VERSION "created by canmatrix"

NS_ :

BS_:

BU_: IPD

BO_ 351 ICBAD_RZCUCANFD_20ms_FrP05: 20 IPD
 SG_ ICBAD_20ms_Group05_CRC : 7|8@0+ (1,0) [0|255] "null" Vector__XXX
 SG_ ICBAD_20ms_Group05_RC : 11|4@0+ (1,0) [0|15] "null" Vector__XXX
 SG_ ICBAD_20ms_Group05_Reserved1 : 12|1@0+ (1,0) [0|1] "null" Vector__XXX
 SG_ APAVCUReqSts : 15|3@0+ (1,0) [0|7] "null" Vector__XXX
 SG_ ICBAD_20ms_Group05_Reserved2 : 23|8@0+ (1,0) [0|255] "null" Vector__XXX
 SG_ APAToqReqVal : 31|12@0+ (0.5,-848) [-848|1199.5] "Nm" Vector__XXX
 SG_ APACrpSpdReqVal_IPD : 33|10@0+ (0.1,0) [0|102.3] "km/h" Vector__XXX
 SG_ ICBAD_20ms_Group05_Reserved3 : 34|1@0+ (1,0) [0|1] "null" Vector__XXX
 SG_ APARevrDrgReq : 35|1@0+ (1,0) [0|1] "null" Vector__XXX
 SG_ ICBAD_20ms_Group05_Reserved4 : 55|8@0+ (1,0) [0|255] "null" Vector__XXX
 SG_ ICBAD_20ms_Group05_Reserved5 : 63|8@0+ (1,0) [0|255] "null" Vector__XXX
 SG_ APATotWhlToqReqVal : 71|16@0+ (1,-30000) [-30000|35535] "Nm" Vector__XXX
 SG_ ICBAD_20ms_Group05_Reserved6 : 87|8@0+ (1,0) [0|255] "null" Vector__XXX
 SG_ ICBAD_20ms_Group05_Reserved7 : 95|8@0+ (1,0) [0|255] "null" Vector__XXX
 SG_ ICBAD_20ms_Group05_Reserved8 : 103|8@0+ (1,0) [0|255] "null" Vector__XXX
 SG_ ICBAD_20ms_Group05_Reserved9 : 111|8@0+ (1,0) [0|255] "null" Vector__XXX
 SG_ ICBAD_20ms_Group05_Reserved10 : 119|8@0+ (1,0) [0|255] "null" Vector__XXX
 SG_ ICBAD_20ms_Group05_Reserved11 : 127|8@0+ (1,0) [0|255] "null" Vector__XXX
 SG_ ICBAD_20ms_Group05_Reserved12 : 135|8@0+ (1,0) [0|255] "null" Vector__XXX
 SG_ ICBAD_20ms_Group05_Reserved13 : 143|8@0+ (1,0) [0|255] "null" Vector__XXX
 SG_ ICBAD_20ms_Group05_Reserved14 : 151|8@0+ (1,0) [0|255] "null" Vector__XXX
 SG_ ICBAD_20ms_Group05_Reserved15 : 159|8@0+ (1,0) [0|255] "null" Vector__XXX

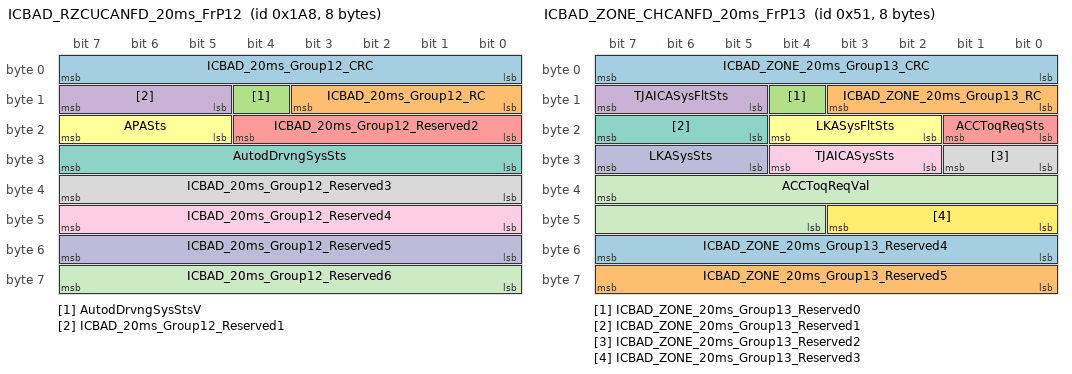
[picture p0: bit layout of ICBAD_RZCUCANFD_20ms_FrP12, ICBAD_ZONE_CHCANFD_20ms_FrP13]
BO_ 424 ICBAD_RZCUCANFD_20ms_FrP12: 8 IPD
 SG_ ICBAD_20ms_Group12_CRC : 7|8@0+ (1,0) [0|255] "null" Vector__XXX
 SG_ ICBAD_20ms_Group12_RC : 11|4@0+ (1,0) [0|15] "null" Vector__XXX
 SG_ AutodDrvngSysStsV : 12|1@0+ (1,0) [0|1] "null" Vector__XXX
 SG_ ICBAD_20ms_Group12_Reserved1 : 15|3@0+ (1,0) [0|7] "null" Vector__XXX
 SG_ ICBAD_20ms_Group12_Reserved2 : 20|5@0+ (1,0) [0|31] "null" Vector__XXX
 SG_ APASts : 23|3@0+ (1,0) [0|7] "null" Vector__XXX
 SG_ AutodDrvngSysSts : 31|8@0+ (1,0) [0|255] "null" Vector__XXX
 SG_ ICBAD_20ms_Group12_Reserved3 : 39|8@0+ (1,0) [0|255] "null" Vector__XXX
 SG_ ICBAD_20ms_Group12_Reserved4 : 47|8@0+ (1,0) [0|255] "null" Vector__XXX
 SG_ ICBAD_20ms_Group12_Reserved5 : 55|8@0+ (1,0) [0|255] "null" Vector__XXX
 SG_ ICBAD_20ms_Group12_Reserved6 : 63|8@0+ (1,0) [0|255] "null" Vector__XXX

BO_ 431 ICBAD_RZCUCANFD_20ms_FrP15_NoSec: 12 IPD
 SG_ ICBAD_20ms_Group15_CRC : 7|8@0+ (1,0) [0|255] "null" Vector__XXX
 SG_ ICBAD_20ms_Group15_RC : 11|4@0+ (1,0) [0|15] "null" Vector__XXX
 SG_ ACCDclReqSts : 13|2@0+ (1,0) [0|3] "null" Vector__XXX
 SG_ ICBAD_20ms_Group15_Reserved1 : 15|2@0+ (1,0) [0|3] "null" Vector__XXX
 SG_ ICBAD_20ms_Group15_Reserved2 : 23|8@0+ (1,0) [0|255] "null" Vector__XXX
 SG_ ACCOtptShaftTotToqReqVal : 31|12@0+ (2,-3392) [-3392|4798] "Nm" Vector__XXX
 SG_ ICBAD_20ms_Group15_Reserved3 : 33|2@0+ (1,0) [0|3] "null" Vector__XXX
 SG_ ACCOtptShaftTotToqReqSts : 35|2@0+ (1,0) [0|3] "null" Vector__XXX
 SG_ AutodDrvngSysStsPT : 47|8@0+ (1,0) [0|255] "null" Vector__XXX
 SG_ ICBAD_20ms_Group15_Reserved4 : 55|8@0+ (1,0) [0|255] "null" Vector__XXX
 SG_ ICBAD_20ms_Group15_Reserved5 : 63|8@0+ (1,0) [0|255] "null" Vector__XXX
 SG_ ICBAD_20ms_Group15_Reserved6 : 71|8@0+ (1,0) [0|255] "null" Vector__XXX
 SG_ ICBAD_20ms_Group15_Reserved7 : 79|8@0+ (1,0) [0|255] "null" Vector__XXX
 SG_ ICBAD_20ms_Group15_Reserved8 : 87|8@0+ (1,0) [0|255] "null" Vector__XXX
 SG_ ICBAD_20ms_Group15_Reserved9 : 95|8@0+ (1,0) [0|255] "null" Vector__XXX

BO_ 81 ICBAD_ZONE_CHCANFD_20ms_FrP13: 8 IPD
 SG_ ICBAD_ZONE_20ms_Group13_CRC : 7|8@0+ (1,0) [0|255] "null" Vector__XXX
 SG_ ICBAD_ZONE_20ms_Group13_RC : 11|4@0+ (1,0) [0|15] "null" Vector__XXX
 SG_ ICBAD_ZONE_20ms_Group13_Reserved0 : 12|1@0+ (1,0) [0|1] "null" Vector__XXX
 SG_ TJAICASysFltSts : 15|3@0+ (1,0) [0|7] "null" Vector__XXX
 SG_ ACCToqReqSts : 17|2@0+ (1,0) [0|3] "null" Vector__XXX
 SG_ LKASysFltSts : 20|3@0+ (1,0) [0|7] "null" Vector__XXX
 SG_ ICBAD_ZONE_20ms_Group13_Reserved1 : 23|3@0+ (1,0) [0|7] "null" Vector__XXX
 SG_ ICBAD_ZONE_20ms_Group13_Reserved2 : 25|2@0+ (1,0) [0|3] "null" Vector__XXX
 SG_ TJAICASysSts : 28|3@0+ (1,0) [0|7] "null" Vector__XXX
 SG_ LKASysSts : 31|3@0+ (1,0) [0|7] "null" Vector__XXX
 SG_ ACCToqReqVal : 39|12@0+ (0.5,-848) [-848|1199.5] "null" Vector__XXX
 SG_ ICBAD_ZONE_20ms_Group13_Reserved3 : 43|4@0+ (1,0) [0|15] "null" Vector__XXX
 SG_ ICBAD_ZONE_20ms_Group13_Reserved4 : 55|8@0+ (1,0) [0|255] "null" Vector__XXX
 SG_ ICBAD_ZONE_20ms_Group13_Reserved5 : 63|8@0+ (1,0) [0|255] "null" Vector__XXX

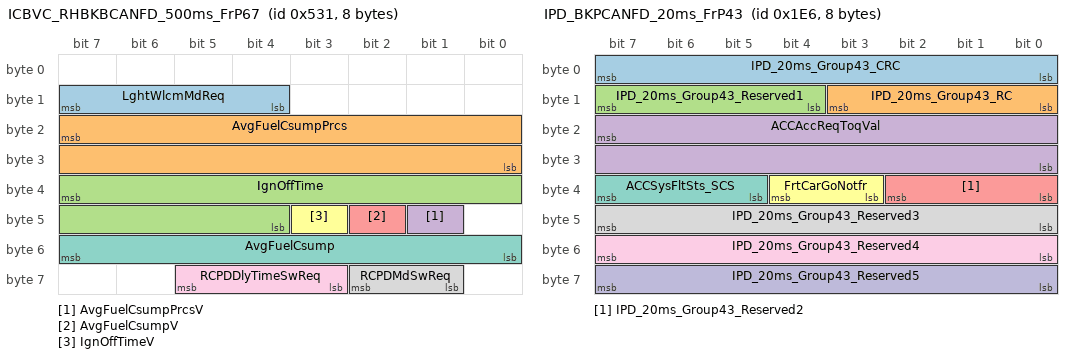
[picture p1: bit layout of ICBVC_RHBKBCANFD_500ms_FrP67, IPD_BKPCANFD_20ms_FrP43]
BO_ 1329 ICBVC_RHBKBCANFD_500ms_FrP67: 8 Vector__XXX
 SG_ LghtWlcmMdReq : 15|4@0+ (1,0) [0|15] "null" Vector__XXX
 SG_ AvgFuelCsumpPrcs : 23|16@0+ (0.01,0) [0.00|655.35] "0.01L/100km" Vector__XXX
 SG_ IgnOffTime : 39|12@0+ (0.5,0) [0|2047.5] "null" IPD
 SG_ AvgFuelCsumpPrcsV : 41|1@0+ (1,0) [0|1] "null" Vector__XXX
 SG_ AvgFuelCsumpV : 42|1@0+ (1,0) [0|1] "null" Vector__XXX
 SG_ IgnOffTimeV : 43|1@0+ (1,0) [0|1] "null" IPD
 SG_ AvgFuelCsump : 55|8@0+ (0.1,0) [0|25.5] "null" Vector__XXX
 SG_ RCPDMdSwReq : 58|2@0+ (1,0) [0|3] "null" Vector__XXX
 SG_ RCPDDlyTimeSwReq : 61|3@0+ (1,0) [0|7] "null" Vector__XXX

BO_ 1023 ICBVC_RZCUCANFD_100ms_FrP19: 8 Vector__XXX
 SG_ ICBVC_100ms_Group19_CRC : 7|8@0+ (1,0) [0|255] "null" IPD
 SG_ ICBVC_100ms_Group19_RC : 11|4@0+ (1,0) [0|15] "null" IPD
 SG_ RgnLvReqFICMV : 12|1@0+ (1,0) [0|1] "null" IPD
 SG_ RgnLvReqFICM : 15|3@0+ (1,0) [0|7] "null" IPD
 SG_ LVBatChrgReqRaw : 16|1@0+ (1,0) [0|1] "null" IPD
 SG_ LVBatChrgReqInhbt : 17|1@0+ (1,0) [0|1] "null" IPD
 SG_ LVBatEnrgSufct : 18|1@0+ (1,0) [0|1] "null" IPD
 SG_ LVBatEnrgLow : 19|1@0+ (1,0) [0|1] "null" IPD
 SG_ ICBVC_100ms_Group19_Reserved21 : 21|2@0+ (1,0) [0|3] "null" IPD
 SG_ EnrgSplReqV : 22|1@0+ (1,0) [0|1] "null" IPD
 SG_ EnrgSplReq : 23|1@0+ (1,0) [0|1] "null" IPD
 SG_ PMDCSta : 27|4@0+ (1,0) [0|15] "null" IPD
 SG_ EPMOprtMd : 31|4@0+ (1,0) [0|15] "null" IPD
 SG_ ICBVC_100ms_Group19_Reserved35 : 35|4@0+ (1,0) [0|15] "null" IPD
 SG_ VehEnrgRdyLvlV : 36|1@0+ (1,0) [0|1] "null" IPD
 SG_ VehEnrgRdyLvl : 39|3@0+ (1,0) [0|7] "null" IPD
 SG_ EPMCurEstdCapct : 47|8@0+ (0.5,0) [0|127.5] "Ah" IPD
 SG_ EPMMaxEstdCapct : 55|8@0+ (0.5,0) [0|127.5] "Ah" IPD
 SG_ LVBMDisChrgMOSCtrl : 56|1@0+ (1,0) [0|1] "null" IPD
 SG_ AuxBatUnAssembled : 57|1@0+ (1,0) [0|1] "null" IPD
 SG_ ICBVC_100ms_Group19_Reserved58 : 58|1@0+ (1,0) [0|1] "null" IPD
 SG_ EPTToqCustSetngReqV : 59|1@0+ (1,0) [0|1] "null" IPD
 SG_ EPTToqCustSetngReq : 61|2@0+ (1,0) [0|3] "null" IPD
 SG_ LVBatSelfWakeupFlg : 62|1@0+ (1,0) [0|1] "null" IPD
 SG_ EnrgSplReqRaw : 63|1@0+ (1,0) [0|1] "null" IPD

BO_ 486 IPD_BKPCANFD_20ms_FrP43: 8 IPD
 SG_ IPD_20ms_Group43_CRC : 7|8@0+ (1,0) [0|255] "null" Vector__XXX
 SG_ IPD_20ms_Group43_RC : 11|4@0+ (1,0) [0|15] "null" Vector__XXX
 SG_ IPD_20ms_Group43_Reserved1 : 15|4@0+ (1,0) [0|15] "null" Vector__XXX
 SG_ ACCAccReqToqVal : 23|16@0+ (1,0) [0|65535] "Nm" Vector__XXX
 SG_ IPD_20ms_Group43_Reserved2 : 34|3@0+ (1,0) [0|7] "null" Vector__XXX
 SG_ FrtCarGoNotfr : 36|2@0+ (1,0) [0|3] "null" Vector__XXX
 SG_ ACCSysFltSts_SCS : 39|3@0+ (1,0) [0|7] "null" Vector__XXX
 SG_ IPD_20ms_Group43_Reserved3 : 47|8@0+ (1,0) [0|255] "null" Vector__XXX
 SG_ IPD_20ms_Group43_Reserved4 : 55|8@0+ (1,0) [0|255] "null" Vector__XXX
 SG_ IPD_20ms_Group43_Reserved5 : 63|8@0+ (1,0) [0|255] "null" Vector__XXX

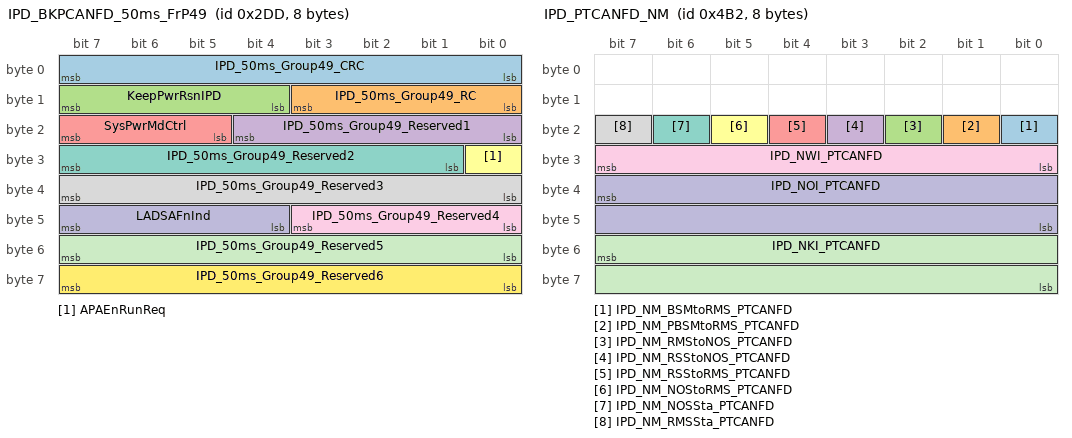
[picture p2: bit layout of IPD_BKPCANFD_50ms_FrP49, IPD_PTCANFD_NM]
BO_ 733 IPD_BKPCANFD_50ms_FrP49: 8 IPD
 SG_ IPD_50ms_Group49_CRC : 7|8@0+ (1,0) [0|255] "null" Vector__XXX
 SG_ IPD_50ms_Group49_RC : 11|4@0+ (1,0) [0|15] "null" Vector__XXX
 SG_ KeepPwrRsnIPD : 15|4@0+ (1,0) [0|15] "null" Vector__XXX
 SG_ IPD_50ms_Group49_Reserved1 : 20|5@0+ (1,0) [0|31] "null" Vector__XXX
 SG_ SysPwrMdCtrl : 23|3@0+ (1,0) [0|7] "null" Vector__XXX
 SG_ APAEnRunReq : 24|1@0+ (1,0) [0|1] "null" Vector__XXX
 SG_ IPD_50ms_Group49_Reserved2 : 31|7@0+ (1,0) [0|127] "null" Vector__XXX
 SG_ IPD_50ms_Group49_Reserved3 : 39|8@0+ (1,0) [0|255] "null" Vector__XXX
 SG_ IPD_50ms_Group49_Reserved4 : 43|4@0+ (1,0) [0|15] "null" Vector__XXX
 SG_ LADSAFnInd : 47|4@0+ (1,0) [0|15] "null" Vector__XXX
 SG_ IPD_50ms_Group49_Reserved5 : 55|8@0+ (1,0) [0|255] "null" Vector__XXX
 SG_ IPD_50ms_Group49_Reserved6 : 63|8@0+ (1,0) [0|255] "null" Vector__XXX

BO_ 982 IPD_PTCANFD_100ms_FrP03: 20 IPD
 SG_ ACCDetObjLongtRltvDist : 7|12@0+ (0.0625,0) [0.0000|255.9375] "null" Vector__XXX
 SG_ ACCDetObjSyncCtr : 11|4@0+ (1,0) [0|15] "null" Vector__XXX
 SG_ ACCDetObjLongtRltvSpd : 23|12@0+ (0.0625,-128) [-128.0000|127.9375] "null" Vector__XXX
 SG_ ACCDetObjRisk : 24|1@0+ (1,0) [0|1] "null" Vector__XXX
 SG_ ACCDetObjTyp : 27|3@0+ (1,0) [0|7] "null" Vector__XXX
 SG_ ACCDetObjLatRltvDist : 33|15@0+ (0.0078,-128) [-128.0000|127.5826] "null" Vector__XXX
 SG_ ACCDetObjExistPrblty : 39|6@0+ (0.015625,0) [0.000000|0.984375] "null" Vector__XXX
 SG_ ACCDetObjId : 50|6@0+ (1,0) [0|63] "null" Vector__XXX

BO_ 478 IPD_PTCANFD_20ms_FrP64: 16 IPD
 SG_ IPD_20ms_Group64_CRC : 7|8@0+ (1,0) [0|255] "null" Vector__XXX
 SG_ IPD_20ms_Group64_RC : 11|4@0+ (1,0) [0|15] "null" Vector__XXX
 SG_ APASCSDrvrReqSts : 12|1@0+ (1,0) [0|1] "null" Vector__XXX
 SG_ APASCSBrkFn : 15|3@0+ (1,0) [0|7] "null" Vector__XXX
 SG_ APASCSParkngVelMax : 23|8@0+ (0.1,0) [0|25.5] "null" Vector__XXX
 SG_ APASCSParkngTrgtDist : 31|12@0+ (1,0) [0|4095] "null" Vector__XXX
 SG_ APAEnToqReqVal : 35|12@0+ (0.5,-848) [-848|1199.5] "null" Vector__XXX
 SG_ IPD_20ms_Group64_Reserved1 : 48|1@0+ (1,0) [0|1] "null" Vector__XXX
 SG_ APAEnToqReqSts : 49|1@0+ (1,0) [0|1] "null" Vector__XXX
 SG_ APASCSParkngPrflReq : 50|1@0+ (1,0) [0|1] "null" Vector__XXX
 SG_ APASCSReqSts : 53|3@0+ (1,0) [0|7] "null" Vector__XXX
 SG_ APASCSBrkFnMd : 55|2@0+ (1,0) [0|3] "null" Vector__XXX
 SG_ IPD_20ms_Group64_Reserved2 : 63|8@0+ (1,0) [0|255] "null" Vector__XXX
 SG_ IPD_20ms_Group64_Reserved3 : 71|8@0+ (1,0) [0|255] "null" Vector__XXX
 SG_ IPD_20ms_Group64_Reserved4 : 79|8@0+ (1,0) [0|255] "null" Vector__XXX
 SG_ IPD_20ms_Group64_Reserved5 : 87|8@0+ (1,0) [0|255] "null" Vector__XXX
 SG_ IPD_20ms_Group64_Reserved6 : 95|8@0+ (1,0) [0|255] "null" Vector__XXX
 SG_ IPD_20ms_Group64_Reserved7 : 103|8@0+ (1,0) [0|255] "null" Vector__XXX
 SG_ IPD_20ms_Group64_Reserved8 : 111|8@0+ (1,0) [0|255] "null" Vector__XXX
 SG_ IPD_20ms_Group64_Reserved9 : 119|8@0+ (1,0) [0|255] "null" Vector__XXX
 SG_ IPD_20ms_Group64_Reserved10 : 127|8@0+ (1,0) [0|255] "null" Vector__XXX

BO_ 176 IPD_PTCANFD_20ms_FrP67: 16 IPD
 SG_ IPD_20ms_Group67_CRC : 7|8@0+ (1,0) [0|255] "null" Vector__XXX
 SG_ IPD_20ms_Group67_RC : 11|4@0+ (1,0) [0|15] "null" Vector__XXX
 SG_ IPD_20ms_Group67_Reserved15 : 15|4@0+ (1,0) [0|15] "null" Vector__XXX
 SG_ IPD_20ms_Group67_Reserved23 : 23|8@0+ (1,0) [0|255] "null" Vector__XXX
 SG_ IPD_20ms_Group67_Reserved31 : 31|8@0+ (1,0) [0|255] "null" Vector__XXX
 SG_ IPD_20ms_Group67_Reserved39 : 39|8@0+ (1,0) [0|255] "null" Vector__XXX
 SG_ IPD_20ms_Group67_Reserved47 : 47|8@0+ (1,0) [0|255] "null" Vector__XXX
 SG_ IPD_20ms_Group67_Reserved55 : 55|8@0+ (1,0) [0|255] "null" Vector__XXX
 SG_ IPD_20ms_Group67_Reserved63 : 63|8@0+ (1,0) [0|255] "null" Vector__XXX
 SG_ IPD_20ms_Group67_Reserved71 : 71|8@0+ (1,0) [0|255] "null" Vector__XXX
 SG_ ADS_SpdAstSysTrgtSpd : 79|15@0+ (0.015625,0) [0.000000|511.984375] "null" Vector__XXX
 SG_ ADS_SpdAstSysTrgtSpdV : 80|1@0+ (1,0) [0|1] "null" Vector__XXX
 SG_ IPD_20ms_Group67_Reserved95 : 95|8@0+ (1,0) [0|255] "null" Vector__XXX
 SG_ IPD_20ms_Group67_Reserved103 : 103|8@0+ (1,0) [0|255] "null" Vector__XXX
 SG_ IPD_20ms_Group67_Reserved111 : 111|8@0+ (1,0) [0|255] "null" Vector__XXX
 SG_ IPD_20ms_Group67_Reserved119 : 119|8@0+ (1,0) [0|255] "null" Vector__XXX
 SG_ IPD_20ms_Group67_Reserved127 : 127|8@0+ (1,0) [0|255] "null" Vector__XXX

BO_ 1202 IPD_PTCANFD_NM: 8 IPD
 SG_ IPD_NM_BSMtoRMS_PTCANFD : 16|1@0+ (1,0) [0|1] "null" Vector__XXX
 SG_ IPD_NM_PBSMtoRMS_PTCANFD : 17|1@0+ (1,0) [0|1] "null" Vector__XXX
 SG_ IPD_NM_RMStoNOS_PTCANFD : 18|1@0+ (1,0) [0|1] "null" Vector__XXX
 SG_ IPD_NM_RSStoNOS_PTCANFD : 19|1@0+ (1,0) [0|1] "null" Vector__XXX
 SG_ IPD_NM_RSStoRMS_PTCANFD : 20|1@0+ (1,0) [0|1] "null" Vector__XXX
 SG_ IPD_NM_NOStoRMS_PTCANFD : 21|1@0+ (1,0) [0|1] "null" Vector__XXX
 SG_ IPD_NM_NOSSta_PTCANFD : 22|1@0+ (1,0) [0|1] "null" Vector__XXX
 SG_ IPD_NM_RMSSta_PTCANFD : 23|1@0+ (1,0) [0|1] "null" Vector__XXX
 SG_ IPD_NWI_PTCANFD : 31|8@0+ (1,0) [0|255] "null" Vector__XXX
 SG_ IPD_NOI_PTCANFD : 39|16@0+ (1,0) [0|65535] "null" Vector__XXX
 SG_ IPD_NKI_PTCANFD : 55|16@0+ (1,0) [0|65535] "null" Vector__XXX

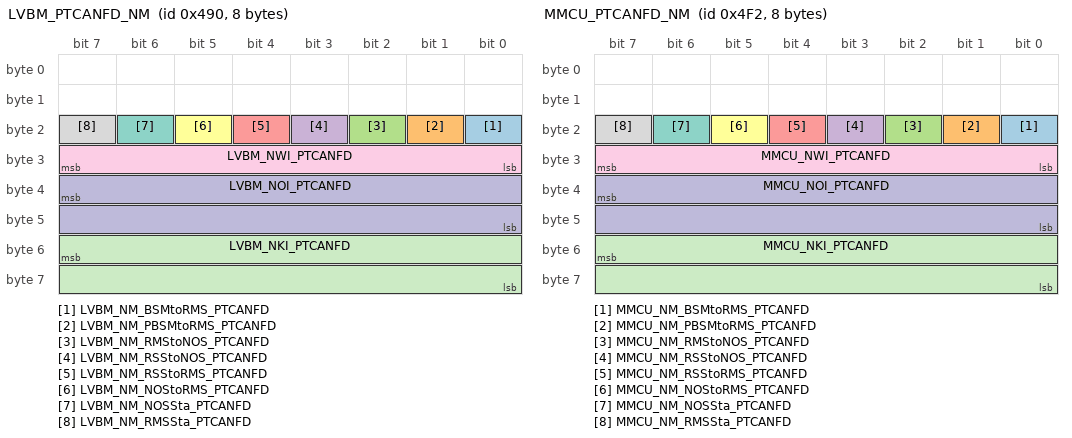
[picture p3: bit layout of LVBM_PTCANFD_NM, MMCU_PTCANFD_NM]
BO_ 1168 LVBM_PTCANFD_NM: 8 Vector__XXX
 SG_ LVBM_NM_BSMtoRMS_PTCANFD : 16|1@0+ (1,0) [0|1] "null" Vector__XXX
 SG_ LVBM_NM_PBSMtoRMS_PTCANFD : 17|1@0+ (1,0) [0|1] "null" Vector__XXX
 SG_ LVBM_NM_RMStoNOS_PTCANFD : 18|1@0+ (1,0) [0|1] "null" Vector__XXX
 SG_ LVBM_NM_RSStoNOS_PTCANFD : 19|1@0+ (1,0) [0|1] "null" Vector__XXX
 SG_ LVBM_NM_RSStoRMS_PTCANFD : 20|1@0+ (1,0) [0|1] "null" Vector__XXX
 SG_ LVBM_NM_NOStoRMS_PTCANFD : 21|1@0+ (1,0) [0|1] "null" Vector__XXX
 SG_ LVBM_NM_NOSSta_PTCANFD : 22|1@0+ (1,0) [0|1] "null" Vector__XXX
 SG_ LVBM_NM_RMSSta_PTCANFD : 23|1@0+ (1,0) [0|1] "null" Vector__XXX
 SG_ LVBM_NWI_PTCANFD : 31|8@0+ (1,0) [0|255] "null" Vector__XXX
 SG_ LVBM_NOI_PTCANFD : 39|16@0+ (1,0) [0|65535] "null" Vector__XXX
 SG_ LVBM_NKI_PTCANFD : 55|16@0+ (1,0) [0|65535] "null" Vector__XXX

BO_ 1266 MMCU_PTCANFD_NM: 8 Vector__XXX
 SG_ MMCU_NM_BSMtoRMS_PTCANFD : 16|1@0+ (1,0) [0|1] "null" Vector__XXX
 SG_ MMCU_NM_PBSMtoRMS_PTCANFD : 17|1@0+ (1,0) [0|1] "null" Vector__XXX
 SG_ MMCU_NM_RMStoNOS_PTCANFD : 18|1@0+ (1,0) [0|1] "null" Vector__XXX
 SG_ MMCU_NM_RSStoNOS_PTCANFD : 19|1@0+ (1,0) [0|1] "null" Vector__XXX
 SG_ MMCU_NM_RSStoRMS_PTCANFD : 20|1@0+ (1,0) [0|1] "null" Vector__XXX
 SG_ MMCU_NM_NOStoRMS_PTCANFD : 21|1@0+ (1,0) [0|1] "null" Vector__XXX
 SG_ MMCU_NM_NOSSta_PTCANFD : 22|1@0+ (1,0) [0|1] "null" Vector__XXX
 SG_ MMCU_NM_RMSSta_PTCANFD : 23|1@0+ (1,0) [0|1] "null" Vector__XXX
 SG_ MMCU_NWI_PTCANFD : 31|8@0+ (1,0) [0|255] "null" Vector__XXX
 SG_ MMCU_NOI_PTCANFD : 39|16@0+ (1,0) [0|65535] "null" Vector__XXX
 SG_ MMCU_NKI_PTCANFD : 55|16@0+ (1,0) [0|65535] "null" Vector__XXX

BO_ 153 PEU_PTCANFD_10ms_FrP25: 20 Vector__XXX
 SG_ PEU_10ms_Group25_CRC : 7|8@0+ (1,0) [0|255] "null" IPD
 SG_ PEU_10ms_Group25_RC : 11|4@0+ (1,0) [0|15] "null" IPD
 SG_ PEUMotBSpdSts : 13|2@0+ (1,0) [0|3] "null" IPD
 SG_ PEUMotASpdSts : 15|2@0+ (1,0) [0|3] "null" IPD
 SG_ PEUMotADampTrqCmdd : 23|16@0+ (0.03125,-1023.96875) [-1023.96875|1024.00000] "null" IPD
 SG_ PEUMotASpd : 39|16@0+ (1,-32768) [-32768|32767] "rpm" IPD
 SG_ PEUMotBDampTrqCmdd : 55|16@0+ (0.03125,-1023.96875) [-1023.96875|1024.00000] "null" IPD
 SG_ PEUMotBSpd : 71|16@0+ (1,-32768) [-32768|32767] "null" IPD
 SG_ PEUMotAToqAch : 87|12@0+ (0.5,-1023.5) [-1023.5|1024] "null" IPD
 SG_ PEUMotBToqAch : 90|11@0+ (0.5,-511.5) [-511.5|512] "null" IPD
 SG_ PEUMotASpdV : 91|1@0+ (1,0) [0|1] "null" IPD
 SG_ PEU_10ms_Group25_Reserved1 : 106|3@0+ (1,0) [0|7] "null" IPD
 SG_ ReAxleMaxAvlblWhlRgtnTqV : 107|1@0+ (1,0) [0|1] "null" IPD
 SG_ ReAxleMaxAvlblWhlDrvTqV : 108|1@0+ (1,0) [0|1] "null" IPD
 SG_ PEUMotBToqAchV : 109|1@0+ (1,0) [0|1] "null" IPD
 SG_ PEUMotBSpdV : 110|1@0+ (1,0) [0|1] "null" IPD
 SG_ PEUMotAToqAchV : 111|1@0+ (1,0) [0|1] "null" IPD
 SG_ ReAxleMaxAvlblWhlDrvTq : 119|16@0+ (1,-32767) [-32767|32768] "Nm" IPD
 SG_ ReAxleMaxAvlblWhlRgtnTq : 135|16@0+ (1,-32767) [-32767|32768] "Nm" IPD
 SG_ PEU_10ms_Group25_Reserved147 : 147|4@0+ (1,0) [0|15] "null" IPD
 SG_ PEUMotBMdAch : 149|2@0+ (1,0) [0|3] "null" IPD
 SG_ PEUMotAMdAch : 151|2@0+ (1,0) [0|3] "null" IPD
 SG_ PEU_10ms_Group25_Reserved3 : 159|8@0+ (1,0) [0|255] "null" IPD

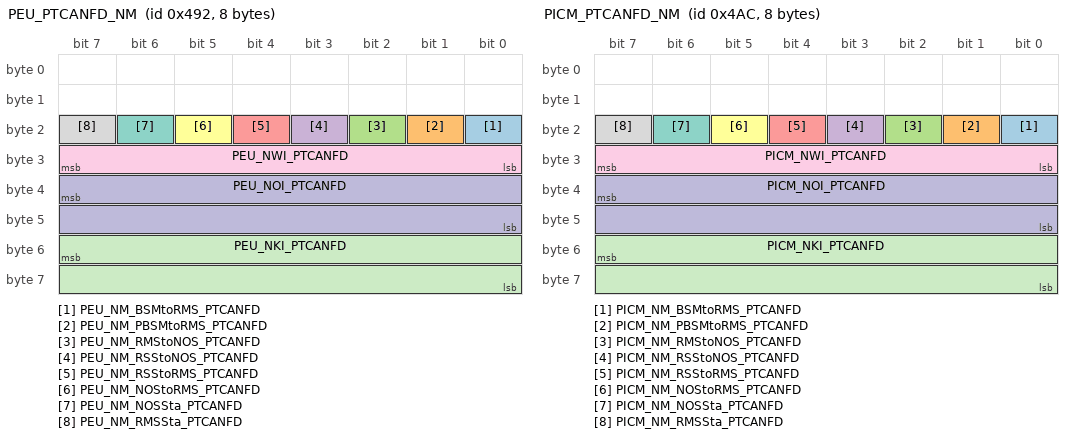
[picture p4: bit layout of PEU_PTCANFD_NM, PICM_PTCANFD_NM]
BO_ 1170 PEU_PTCANFD_NM: 8 Vector__XXX
 SG_ PEU_NM_BSMtoRMS_PTCANFD : 16|1@0+ (1,0) [0|1] "null" Vector__XXX
 SG_ PEU_NM_PBSMtoRMS_PTCANFD : 17|1@0+ (1,0) [0|1] "null" Vector__XXX
 SG_ PEU_NM_RMStoNOS_PTCANFD : 18|1@0+ (1,0) [0|1] "null" Vector__XXX
 SG_ PEU_NM_RSStoNOS_PTCANFD : 19|1@0+ (1,0) [0|1] "null" Vector__XXX
 SG_ PEU_NM_RSStoRMS_PTCANFD : 20|1@0+ (1,0) [0|1] "null" Vector__XXX
 SG_ PEU_NM_NOStoRMS_PTCANFD : 21|1@0+ (1,0) [0|1] "null" Vector__XXX
 SG_ PEU_NM_NOSSta_PTCANFD : 22|1@0+ (1,0) [0|1] "null" Vector__XXX
 SG_ PEU_NM_RMSSta_PTCANFD : 23|1@0+ (1,0) [0|1] "null" Vector__XXX
 SG_ PEU_NWI_PTCANFD : 31|8@0+ (1,0) [0|255] "null" Vector__XXX
 SG_ PEU_NOI_PTCANFD : 39|16@0+ (1,0) [0|65535] "null" Vector__XXX
 SG_ PEU_NKI_PTCANFD : 55|16@0+ (1,0) [0|65535] "null" Vector__XXX

BO_ 714 PICM_PTCANFD_100ms_FrP06: 20 Vector__XXX
 SG_ AGSModestatus2 : 13|2@0+ (1,0) [0|3] "null" Vector__XXX
 SG_ AGSModestatus1 : 15|2@0+ (1,0) [0|3] "null" Vector__XXX
 SG_ AGS1FltRsn : 23|12@0+ (1,0) [0|4095] "null" Vector__XXX
 SG_ AGS2FltRsn : 27|12@0+ (1,0) [0|4095] "null" Vector__XXX
 SG_ AGSActualPosition1 : 47|8@0+ (0.392157,0) [0.000000|100.000035] "null" Vector__XXX
 SG_ AGSActualPosition2 : 55|8@0+ (0.392157,0) [0.000000|100.000035] "null" Vector__XXX
 SG_ EPTElecWtrPumpActuSpd : 63|8@0+ (0.4,0) [0|102] "null" IPD
 SG_ ESSElecWtrPumpActuSpd : 71|8@0+ (0.4,0) [0|102] "null" Vector__XXX
 SG_ EDUClntTem : 79|8@0+ (1,-40) [-40|215] "null" IPD
 SG_ AGSTorqueResponse2 : 81|2@0+ (1,0) [0|3] "null" Vector__XXX
 SG_ AGSTorqueResponse1 : 83|2@0+ (1,0) [0|3] "null" Vector__XXX
 SG_ AGSSelflearnStatus2 : 85|2@0+ (1,0) [0|3] "null" Vector__XXX
 SG_ AGSSelflearnStatus1 : 87|2@0+ (1,0) [0|3] "null" Vector__XXX
 SG_ OBMLifeTimeParmFromEsMaxLmt : 88|1@0+ (1,0) [0|1] "null" Vector__XXX
 SG_ EndSocTrgtHCUV : 89|1@0+ (1,0) [0|1] "null" Vector__XXX
 SG_ AISocMngtActv : 90|1@0+ (1,0) [0|1] "null" Vector__XXX
 SG_ TrgtSOCUpdtReq : 91|1@0+ (1,0) [0|1] "null" Vector__XXX
 SG_ WCACThrWayVlvActuPosV : 92|1@0+ (1,0) [0|1] "null" Vector__XXX
 SG_ EDUClntTemV : 93|1@0+ (1,0) [0|1] "null" IPD
 SG_ AGSMoveStatus2 : 94|1@0+ (1,0) [0|1] "null" Vector__XXX
 SG_ AGSMoveStatus1 : 95|1@0+ (1,0) [0|1] "null" Vector__XXX
 SG_ WCACThrWayVlvActuPos : 103|8@0+ (0.4,0) [0|102] "Percent" Vector__XXX
 SG_ EndSocTrgtHCU : 111|10@0+ (0.1,0) [0|102.3] "null" Vector__XXX

BO_ 1196 PICM_PTCANFD_NM: 8 Vector__XXX
 SG_ PICM_NM_BSMtoRMS_PTCANFD : 16|1@0+ (1,0) [0|1] "null" Vector__XXX
 SG_ PICM_NM_PBSMtoRMS_PTCANFD : 17|1@0+ (1,0) [0|1] "null" Vector__XXX
 SG_ PICM_NM_RMStoNOS_PTCANFD : 18|1@0+ (1,0) [0|1] "null" Vector__XXX
 SG_ PICM_NM_RSStoNOS_PTCANFD : 19|1@0+ (1,0) [0|1] "null" Vector__XXX
 SG_ PICM_NM_RSStoRMS_PTCANFD : 20|1@0+ (1,0) [0|1] "null" Vector__XXX
 SG_ PICM_NM_NOStoRMS_PTCANFD : 21|1@0+ (1,0) [0|1] "null" Vector__XXX
 SG_ PICM_NM_NOSSta_PTCANFD : 22|1@0+ (1,0) [0|1] "null" Vector__XXX
 SG_ PICM_NM_RMSSta_PTCANFD : 23|1@0+ (1,0) [0|1] "null" Vector__XXX
 SG_ PICM_NWI_PTCANFD : 31|8@0+ (1,0) [0|255] "null" Vector__XXX
 SG_ PICM_NOI_PTCANFD : 39|16@0+ (1,0) [0|65535] "null" Vector__XXX
 SG_ PICM_NKI_PTCANFD : 55|16@0+ (1,0) [0|65535] "null" Vector__XXX

BO_ 140 PICU_PTCANFD_10ms_FrP03: 20 Vector__XXX
 SG_ PICU_10ms_Group03_CRC : 7|8@0+ (1,0) [0|255] "null" IPD
 SG_ PICU_10ms_Group03_RC : 11|4@0+ (1,0) [0|15] "null" IPD
 SG_ FrtAxleActuWhlToqV : 12|1@0+ (1,0) [0|1] "null" IPD
 SG_ PICU_10ms_Group03_Reserved1 : 13|1@0+ (1,0) [0|1] "null" IPD
 SG_ DrvrReqRrAxleWhlToqV : 14|1@0+ (1,0) [0|1] "null" IPD
 SG_ DrvrReqFrtAxleWhlToqV : 15|1@0+ (1,0) [0|1] "null" IPD
 SG_ DrvrReqFrtAxleWhlToq : 23|16@0+ (1,-30000) [-30000|35535] "null" IPD
 SG_ DrvrReqRrAxleWhlToq : 39|16@0+ (1,-30000) [-30000|35535] "null" IPD
 SG_ FrtAxleActuWhlToq : 55|16@0+ (1,-30000) [-30000|35535] "null" IPD
 SG_ RrAxleActuWhlToq : 71|16@0+ (1,-30000) [-30000|35535] "null" IPD
 SG_ TotActuWhlToq : 87|16@0+ (1,-30000) [-30000|35535] "null" IPD
 SG_ PICU_10ms_Group03_Reserved2 : 99|4@0+ (1,0) [0|15] "null" IPD
 SG_ TotActuWhlToqV : 100|1@0+ (1,0) [0|1] "null" IPD
 SG_ RrAxleActuWhlToqV : 101|1@0+ (1,0) [0|1] "null" IPD
 SG_ PtHVCntarReq : 103|2@0+ (1,0) [0|3] "null" IPD
 SG_ PICU_10ms_Group03_Reserved3 : 111|8@0+ (1,0) [0|255] "null" IPD
 SG_ PICU_10ms_Group03_Reserved4 : 119|8@0+ (1,0) [0|255] "null" IPD
 SG_ PICU_10ms_Group03_Reserved5 : 127|8@0+ (1,0) [0|255] "null" IPD
 SG_ PICU_10ms_Group03_Reserved6 : 135|8@0+ (1,0) [0|255] "null" IPD
 SG_ PICU_10ms_Group03_Reserved7 : 143|8@0+ (1,0) [0|255] "null" IPD
 SG_ PICU_10ms_Group03_Reserved8 : 151|8@0+ (1,0) [0|255] "null" IPD
 SG_ PICU_10ms_Group03_Reserved9 : 159|8@0+ (1,0) [0|255] "null" IPD

BO_ 359 PICU_PTCANFD_20ms_FrP11: 16 Vector__XXX
 SG_ PICU_20ms_Group11_CRC : 7|8@0+ (1,0) [0|255] "null" IPD
 SG_ PICU_20ms_Group11_RC : 11|4@0+ (1,0) [0|15] "null" IPD
 SG_ PICU_20ms_Group11_Reserved1 : 12|1@0+ (1,0) [0|1] "null" IPD
 SG_ HybAPAAvlbl : 13|1@0+ (1,0) [0|1] "null" IPD
 SG_ MinAvlblTotWhlToqV : 14|1@0+ (1,0) [0|1] "null" IPD
 SG_ MaxAvlblTotWhlToqV : 15|1@0+ (1,0) [0|1] "null" IPD
 SG_ MaxAvlblTotWhlToq : 23|16@0+ (1,-30000) [-30000|35535] "Nm" IPD
 SG_ MinAvlblTotWhlToq : 39|16@0+ (1,-30000) [-30000|35535] "Nm" IPD
 SG_ PICU_20ms_Group11_Reserved2 : 55|8@0+ (1,0) [0|255] "null" IPD
 SG_ CstRgtnBrkLgtReq : 56|1@0+ (1,0) [0|1] "null" IPD
 SG_ CstRgtnBrkLgtReqV : 57|1@0+ (1,0) [0|1] "null" IPD
 SG_ PICU_20ms_Group11_Reserved3 : 63|6@0+ (1,0) [0|63] "null" IPD
 SG_ PICU_20ms_Group11_Reserved4 : 71|8@0+ (1,0) [0|255] "null" IPD
 SG_ PICU_20ms_Group11_Reserved6 : 73|2@0+ (1,0) [0|3] "null" IPD
 SG_ RdundtHybCmddEnToqRespTyp : 75|2@0+ (1,0) [0|3] "null" IPD
 SG_ PICU_20ms_Group11_Reserved5 : 79|4@0+ (1,0) [0|15] "null" IPD
 SG_ PICU_20ms_Group11_Reserved7 : 87|8@0+ (1,0) [0|255] "null" IPD
 SG_ RdundtHybCmddEnToqImmd : 95|12@0+ (0.5,-848) [-848|1199.5] "null" IPD
 SG_ RdundtHybCmddEnToqPrdtd : 99|12@0+ (0.5,-848) [-848|1199.5] "null" IPD
 SG_ PICU_20ms_Group11_Reserved8 : 119|8@0+ (1,0) [0|255] "null" IPD
 SG_ PICU_20ms_Group11_Reserved9 : 127|8@0+ (1,0) [0|255] "null" IPD

BO_ 236 PICU_PTEXTDCAN_10ms_FrP23: 8 Vector__XXX
 SG_ PICU_10ms_Group23_CRC : 7|8@0+ (1,0) [0|255] "null" IPD
 SG_ PICU_10ms_Group23_RC : 11|4@0+ (1,0) [0|15] "null" IPD
 SG_ EnStCtrlA : 12|1@0+ (1,0) [0|1] "null" IPD
 SG_ EnFuelCutA : 13|1@0+ (1,0) [0|1] "null" IPD
 SG_ HybEnStSpOvrd : 15|2@0+ (1,0) [0|3] "null" IPD
 SG_ HybEnSpdReqF : 16|1@0+ (1,0) [0|1] "null" IPD
 SG_ EnDclFuelCutOffAld : 17|1@0+ (1,0) [0|1] "null" IPD
 SG_ PICU_10ms_Group23_Reserved18 : 18|1@0+ (1,0) [0|1] "null" IPD
 SG_ RVSEnRunning : 19|1@0+ (1,0) [0|1] "null" IPD
 SG_ EnHybVehStaOvrd : 23|4@0+ (1,0) [0|15] "null" IPD
 SG_ EnSynRdy : 24|1@0+ (1,0) [0|1] "null" IPD
 SG_ EnSysDsbld : 25|1@0+ (1,0) [0|1] "null" IPD
 SG_ EnComFlrRducdPwrCmdd : 26|1@0+ (1,0) [0|1] "null" IPD
 SG_ PtACCA : 27|1@0+ (1,0) [0|1] "null" IPD
 SG_ EnDclFuelCutOffReq : 28|1@0+ (1,0) [0|1] "null" IPD
 SG_ EnDclFuelCutOffSta : 29|1@0+ (1,0) [0|1] "null" IPD
 SG_ EnIdleCtrlA : 30|1@0+ (1,0) [0|1] "null" IPD
 SG_ EnIdleCtrlSts : 31|1@0+ (1,0) [0|1] "null" IPD
 SG_ CrkshftNonTrRegdCmddToq : 39|12@0+ (0.5,0) [0|2047.5] "null" IPD
 SG_ EnReqdStTyp : 43|4@0+ (1,0) [0|15] "null" IPD
 SG_ EnFuelRcvrySpd : 55|16@0+ (0.25,0) [0.00|16383.75] "null" IPD

BO_ 777 RZCU_PTCANFD_100ms_FrP10: 8 Vector__XXX
 SG_ RZCU_100ms_Group10_CRC : 7|8@0+ (1,0) [0|255] "null" IPD
 SG_ RZCU_100ms_Group10_RC : 11|4@0+ (1,0) [0|15] "null" IPD
 SG_ RZCU_100ms_Group10_Reserved1 : 13|2@0+ (1,0) [0|3] "null" IPD
 SG_ FlbStrgFnSts : 15|2@0+ (1,0) [0|3] "null" IPD
 SG_ OfbdChrgrNgtvSktTem : 23|8@0+ (1,-40) [-40|215] "degreeCelsius" IPD
 SG_ OnBdChrgrSktPstvSnsrTem : 31|8@0+ (1,-40) [-40|215] "degreeCelsius" IPD
 SG_ EleccLckCtrlResp : 34|3@0+ (1,0) [0|7] "null" IPD
 SG_ OnbdChrgrSktEleccLckEnable : 36|2@0+ (1,0) [0|3] "null" IPD
 SG_ OnBdChrgrSktPstvSnsrTemV : 37|1@0+ (1,0) [0|1] "null" IPD
 SG_ OfbdChrgrNgtvSktTemV : 38|1@0+ (1,0) [0|1] "null" IPD
 SG_ RZCU_100ms_Group10_Reserved2 : 39|1@0+ (1,0) [0|1] "null" IPD
 SG_ RZCU_100ms_Group10_Reserved3 : 45|7@0+ (1,0) [0|127] "null" IPD
 SG_ FlbStrgFnStsResp : 47|2@0+ (1,0) [0|3] "null" IPD
 SG_ RZCU_100ms_Group10_Reserved4 : 49|4@0+ (1,0) [0|15] "null" IPD
 SG_ IMU_Signal_status : 52|3@0+ (1,0) [0|7] "null" IPD
 SG_ VCUCtrlS2Req : 54|2@0+ (1,0) [0|3] "null" IPD
 SG_ RZCU_100ms_Group10_Reserved5 : 58|3@0+ (1,0) [0|7] "null" IPD
 SG_ OnBdChrgrSktElecLckStaV : 59|1@0+ (1,0) [0|1] "null" IPD
 SG_ OnBdChrgrSktElecLckSta : 61|2@0+ (1,0) [0|3] "null" IPD

BA_DEF_ BO_ "FrameTriggeringName" STRING;
BA_DEF_ BO_ "GenMsgCycleTime" INT 0 65535;
BA_DEF_ BO_ "GenMsgSendType" ENUM  "cyclicX","spontanX","cyclicIfActiveX","spontanWithDelay","cyclicAndSpontanX","cyclicAndSpontanWithDelay","spontanWithRepitition","cyclicIfActiveAndSpontanWD","cyclicIfActiveFast","cyclicWithRepeatOnDemand","none";
BA_DEF_ BO_ "GenMsgStartValue" STRING;
BA_DEF_ BO_ "PduName" STRING;
BA_DEF_ BO_ "SystemMessageLongSymbol" STRING;
BA_DEF_ BO_ "VFrameFormat" ENUM  "StandardCAN","ExtendedCAN","reserved","reserved","reserved","reserved","reserved","reserved","reserved","reserved","reserved","reserved","reserved","reserved","StandardCAN_FD","ExtendedCAN_FD";
BA_DEF_ SG_ "CompuMethodName" STRING;
BA_DEF_ SG_ "GenSigStartValue" FLOAT 0 100000000000;
BA_DEF_ SG_ "ISignalName" STRING;
BA_DEF_ SG_ "LongName" STRING;
BA_DEF_ SG_ "SysSignalName" STRING;
BA_DEF_ SG_ "SystemSignalLongSymbol" STRING;
BA_ "FrameTriggeringName" BO_ 351 "ICBAD_RZCUCANFD_20ms_FrP05";
BA_ "GenMsgCycleTime" BO_ 351 20;
BA_ "GenMsgSendType" BO_ 351 0;
BA_ "GenMsgStartValue" BO_ 351 "0010ff000400ffff0000ffffffffffffffffffff";
BA_ "PduName" BO_ 351 "ICBAD_20ms_PDU05";
BA_ "VFrameFormat" BO_ 351 14;
BA_ "FrameTriggeringName" BO_ 424 "ICBAD_RZCUCANFD_20ms_FrP12";
BA_ "GenMsgCycleTime" BO_ 424 20;
BA_ "GenMsgSendType" BO_ 424 0;
BA_ "GenMsgStartValue" BO_ 424 "00e01f00ffffffff";
BA_ "PduName" BO_ 424 "ICBAD_20ms_PDU12";
BA_ "VFrameFormat" BO_ 424 14;
BA_ "FrameTriggeringName" BO_ 431 "ICBAD_RZCUCANFD_20ms_FrP15_NoSecOC";
BA_ "GenMsgCycleTime" BO_ 431 20;
BA_ "GenMsgSendType" BO_ 431 0;
BA_ "GenMsgStartValue" BO_ 431 "00c0ff6a0300ffffffffffff";
BA_ "PduName" BO_ 431 "ICBAD_20ms_PDU15";
BA_ "SystemMessageLongSymbol" BO_ 431 "ICBAD_RZCUCANFD_20ms_FrP15_NoSecOC";
BA_ "VFrameFormat" BO_ 431 14;
BA_ "FrameTriggeringName" BO_ 81 "ICBAD_ZONE_CHCANFD_20ms_FrP13";
BA_ "GenMsgCycleTime" BO_ 81 20;
BA_ "GenMsgSendType" BO_ 81 0;
BA_ "GenMsgStartValue" BO_ 81 "0010e0036a0fffff";
BA_ "PduName" BO_ 81 "ICBAD_ZONE_20ms_PDU13";
BA_ "VFrameFormat" BO_ 81 14;
BA_ "FrameTriggeringName" BO_ 1329 "ICBVC_RHBKBCANFD_500ms_FrP67";
BA_ "GenMsgCycleTime" BO_ 1329 500;
BA_ "GenMsgSendType" BO_ 1329 0;
BA_ "GenMsgStartValue" BO_ 1329 "00000000fff60000";
BA_ "PduName" BO_ 1329 "ICBVC_500ms_PDU67";
BA_ "VFrameFormat" BO_ 1329 14;
BA_ "FrameTriggeringName" BO_ 1023 "ICBVC_RZCUCANFD_100ms_FrP19";
BA_ "GenMsgCycleTime" BO_ 1023 100;
BA_ "GenMsgSendType" BO_ 1023 0;
BA_ "GenMsgStartValue" BO_ 1023 "003078002f00002c";
BA_ "PduName" BO_ 1023 "ICBVC_100ms_PDU19";
BA_ "VFrameFormat" BO_ 1023 14;
BA_ "FrameTriggeringName" BO_ 486 "IPD_BKPCANFD_20ms_FrP43";
BA_ "GenMsgCycleTime" BO_ 486 20;
BA_ "GenMsgSendType" BO_ 486 0;
BA_ "GenMsgStartValue" BO_ 486 "00f0000007ffffff";
BA_ "PduName" BO_ 486 "IPD_20ms_PDU43";
BA_ "VFrameFormat" BO_ 486 14;
BA_ "FrameTriggeringName" BO_ 733 "IPD_BKPCANFD_50ms_FrP49";
BA_ "GenMsgCycleTime" BO_ 733 50;
BA_ "GenMsgSendType" BO_ 733 0;
BA_ "GenMsgStartValue" BO_ 733 "00001ffeff0fffff";
BA_ "PduName" BO_ 733 "IPD_50ms_PDU49";
BA_ "VFrameFormat" BO_ 733 14;
BA_ "FrameTriggeringName" BO_ 982 "IPD_PTCANFD_100ms_FrP03";
BA_ "GenMsgCycleTime" BO_ 982 100;
BA_ "GenMsgSendType" BO_ 982 0;
BA_ "GenMsgStartValue" BO_ 982 "0000000000000000000000000000000000000000";
BA_ "PduName" BO_ 982 "IPD_100ms_PDU03";
BA_ "VFrameFormat" BO_ 982 14;
BA_ "FrameTriggeringName" BO_ 478 "IPD_PTCANFD_20ms_FrP64";
BA_ "GenMsgCycleTime" BO_ 478 20;
BA_ "GenMsgSendType" BO_ 478 0;
BA_ "GenMsgStartValue" BO_ 478 "00000000000001ffffffffffffffffff";
BA_ "PduName" BO_ 478 "IPD_20ms_PDU64";
BA_ "VFrameFormat" BO_ 478 14;
BA_ "FrameTriggeringName" BO_ 176 "IPD_PTCANFD_20ms_FrP67";
BA_ "GenMsgCycleTime" BO_ 176 20;
BA_ "GenMsgSendType" BO_ 176 0;
BA_ "GenMsgStartValue" BO_ 176 "00f0ffffffffffffff0000ffffffffff";
BA_ "PduName" BO_ 176 "IPD_20ms_PDU67";
BA_ "VFrameFormat" BO_ 176 14;
BA_ "FrameTriggeringName" BO_ 1202 "IPD_PTCANFD_NM";
BA_ "GenMsgSendType" BO_ 1202 1;
BA_ "GenMsgStartValue" BO_ 1202 "0000000000000000";
BA_ "PduName" BO_ 1202 "NmPDU_PTCANFD_IPD";
BA_ "VFrameFormat" BO_ 1202 14;
BA_ "FrameTriggeringName" BO_ 1168 "LVBM_PTCANFD_NM";
BA_ "GenMsgSendType" BO_ 1168 1;
BA_ "GenMsgStartValue" BO_ 1168 "0000000000000000";
BA_ "PduName" BO_ 1168 "NmPDU_PTCANFD_LVBM";
BA_ "VFrameFormat" BO_ 1168 14;
BA_ "FrameTriggeringName" BO_ 1266 "MMCU_PTCANFD_NM";
BA_ "GenMsgSendType" BO_ 1266 1;
BA_ "GenMsgStartValue" BO_ 1266 "0000000000000000";
BA_ "PduName" BO_ 1266 "NmPDU_PTCANFD_MMCU";
BA_ "VFrameFormat" BO_ 1266 14;
BA_ "FrameTriggeringName" BO_ 153 "PEU_PTCANFD_10ms_FrP25";
BA_ "GenMsgCycleTime" BO_ 153 10;
BA_ "GenMsgSendType" BO_ 153 0;
BA_ "GenMsgStartValue" BO_ 153 "00007fff7fff7fff7fff7ffbff1f7fff7fff0fff";
BA_ "PduName" BO_ 153 "PEU_10ms_PDU25";
BA_ "VFrameFormat" BO_ 153 14;
BA_ "FrameTriggeringName" BO_ 1170 "PEU_PTCANFD_NM";
BA_ "GenMsgSendType" BO_ 1170 1;
BA_ "GenMsgStartValue" BO_ 1170 "0000000000000000";
BA_ "PduName" BO_ 1170 "NmPDU_PTCANFD_PEU";
BA_ "VFrameFormat" BO_ 1170 14;
BA_ "FrameTriggeringName" BO_ 714 "PICM_PTCANFD_100ms_FrP06";
BA_ "GenMsgCycleTime" BO_ 714 100;
BA_ "GenMsgSendType" BO_ 714 0;
BA_ "GenMsgStartValue" BO_ 714 "00f00000000000ffff00ff320000000000000000";
BA_ "PduName" BO_ 714 "PICM_100ms_PDU06";
BA_ "VFrameFormat" BO_ 714 14;
BA_ "FrameTriggeringName" BO_ 1196 "PICM_PTCANFD_NM";
BA_ "GenMsgSendType" BO_ 1196 1;
BA_ "GenMsgStartValue" BO_ 1196 "0000000000000000";
BA_ "PduName" BO_ 1196 "NmPDU_PTCANFD_PICM";
BA_ "VFrameFormat" BO_ 1196 14;
BA_ "FrameTriggeringName" BO_ 140 "PICU_PTCANFD_10ms_FrP03";
BA_ "GenMsgCycleTime" BO_ 140 10;
BA_ "GenMsgSendType" BO_ 140 0;
BA_ "GenMsgStartValue" BO_ 140 "00f0753075307530753075303fffffffffffffff";
BA_ "PduName" BO_ 140 "PICU_10ms_PDU03";
BA_ "VFrameFormat" BO_ 140 14;
BA_ "FrameTriggeringName" BO_ 359 "PICU_PTCANFD_20ms_FrP11";
BA_ "GenMsgCycleTime" BO_ 359 20;
BA_ "GenMsgSendType" BO_ 359 0;
BA_ "GenMsgStartValue" BO_ 359 "00d075307530fffcfff3ff6a06a0ffff";
BA_ "PduName" BO_ 359 "PICU_20ms_PDU11";
BA_ "VFrameFormat" BO_ 359 14;
BA_ "FrameTriggeringName" BO_ 236 "PICU_PTEXTDCAN_10ms_FrP23";
BA_ "GenMsgCycleTime" BO_ 236 20;
BA_ "GenMsgSendType" BO_ 236 0;
BA_ "GenMsgStartValue" BO_ 236 "0000040000000000";
BA_ "PduName" BO_ 236 "PICU_10ms_PDU23";
BA_ "VFrameFormat" BO_ 236 14;
BA_ "FrameTriggeringName" BO_ 777 "RZCU_PTCANFD_100ms_FrP10";
BA_ "GenMsgCycleTime" BO_ 777 100;
BA_ "GenMsgSendType" BO_ 777 0;
BA_ "GenMsgStartValue" BO_ 777 "0030fe00e03f83cf";
BA_ "PduName" BO_ 777 "RZCU_100ms_PDU10";
BA_ "VFrameFormat" BO_ 777 14;
BA_ "CompuMethodName" SG_ 351 ICBAD_20ms_Group05_CRC "ICBAD_20ms_Group05_CRC";
BA_ "ISignalName" SG_ 351 ICBAD_20ms_Group05_CRC "IICBAD_20ms_Group05_CRC";
BA_ "LongName" SG_ 351 ICBAD_20ms_Group05_CRC "ICBAD_20ms_Group05_CRC";
BA_ "SysSignalName" SG_ 351 ICBAD_20ms_Group05_CRC "ICBAD_20ms_Group05_CRC";
BA_ "CompuMethodName" SG_ 351 ICBAD_20ms_Group05_RC "ICBAD_20ms_Group05_RC";
BA_ "ISignalName" SG_ 351 ICBAD_20ms_Group05_RC "IICBAD_20ms_Group05_RC";
BA_ "LongName" SG_ 351 ICBAD_20ms_Group05_RC "ICBAD_20ms_Group05_RC";
BA_ "SysSignalName" SG_ 351 ICBAD_20ms_Group05_RC "ICBAD_20ms_Group05_RC";
BA_ "CompuMethodName" SG_ 351 ICBAD_20ms_Group05_Reserved1 "ICBAD_20ms_Group05_Reserved1";
BA_ "GenSigStartValue" SG_ 351 ICBAD_20ms_Group05_Reserved1 1;
BA_ "ISignalName" SG_ 351 ICBAD_20ms_Group05_Reserved1 "IICBAD_20ms_Group05_Reserved1";
BA_ "SysSignalName" SG_ 351 ICBAD_20ms_Group05_Reserved1 "ICBAD_20ms_Group05_Reserved1";
BA_ "CompuMethodName" SG_ 351 APAVCUReqSts "APAVCUReqSts";
BA_ "ISignalName" SG_ 351 APAVCUReqSts "IAPAVCUReqSts";
BA_ "LongName" SG_ 351 APAVCUReqSts "Apa Vcu Request Status";
BA_ "SysSignalName" SG_ 351 APAVCUReqSts "APAVCUReqSts";
BA_ "CompuMethodName" SG_ 351 ICBAD_20ms_Group05_Reserved2 "ICBAD_20ms_Group05_Reserved2";
BA_ "GenSigStartValue" SG_ 351 ICBAD_20ms_Group05_Reserved2 255;
BA_ "ISignalName" SG_ 351 ICBAD_20ms_Group05_Reserved2 "IICBAD_20ms_Group05_Reserved2";
BA_ "SysSignalName" SG_ 351 ICBAD_20ms_Group05_Reserved2 "ICBAD_20ms_Group05_Reserved2";
BA_ "CompuMethodName" SG_ 351 APAToqReqVal "APAToqReqVal";
BA_ "ISignalName" SG_ 351 APAToqReqVal "IAPAToqReqVal";
BA_ "LongName" SG_ 351 APAToqReqVal "Advanced Park Assist Torque Request Value";
BA_ "SysSignalName" SG_ 351 APAToqReqVal "APAToqReqVal";
BA_ "CompuMethodName" SG_ 351 APACrpSpdReqVal_IPD "APACrpSpdReqVal_IPD";
BA_ "ISignalName" SG_ 351 APACrpSpdReqVal_IPD "IAPACrpSpdReqVal_IPD";
BA_ "LongName" SG_ 351 APACrpSpdReqVal_IPD "Advanced Park Assist Creep Speed Request Value";
BA_ "SysSignalName" SG_ 351 APACrpSpdReqVal_IPD "APACrpSpdReqVal_IPD";
BA_ "CompuMethodName" SG_ 351 ICBAD_20ms_Group05_Reserved3 "ICBAD_20ms_Group05_Reserved3";
BA_ "GenSigStartValue" SG_ 351 ICBAD_20ms_Group05_Reserved3 1;
BA_ "ISignalName" SG_ 351 ICBAD_20ms_Group05_Reserved3 "IICBAD_20ms_Group05_Reserved3";
BA_ "SysSignalName" SG_ 351 ICBAD_20ms_Group05_Reserved3 "ICBAD_20ms_Group05_Reserved3";
BA_ "CompuMethodName" SG_ 351 APARevrDrgReq "APARevrDrgReq";
BA_ "ISignalName" SG_ 351 APARevrDrgReq "IAPARevrDrgReq";
BA_ "LongName" SG_ 351 APARevrDrgReq "Advanced Park Assist Reverse Drag Request";
BA_ "SysSignalName" SG_ 351 APARevrDrgReq "APARevrDrgReq";
BA_ "CompuMethodName" SG_ 351 ICBAD_20ms_Group05_Reserved4 "ICBAD_20ms_Group05_Reserved4";
BA_ "GenSigStartValue" SG_ 351 ICBAD_20ms_Group05_Reserved4 255;
BA_ "ISignalName" SG_ 351 ICBAD_20ms_Group05_Reserved4 "IICBAD_20ms_Group05_Reserved4";
BA_ "SysSignalName" SG_ 351 ICBAD_20ms_Group05_Reserved4 "ICBAD_20ms_Group05_Reserved4";
BA_ "CompuMethodName" SG_ 351 ICBAD_20ms_Group05_Reserved5 "ICBAD_20ms_Group05_Reserved5";
BA_ "GenSigStartValue" SG_ 351 ICBAD_20ms_Group05_Reserved5 255;
BA_ "ISignalName" SG_ 351 ICBAD_20ms_Group05_Reserved5 "IICBAD_20ms_Group05_Reserved5";
BA_ "SysSignalName" SG_ 351 ICBAD_20ms_Group05_Reserved5 "ICBAD_20ms_Group05_Reserved5";
BA_ "CompuMethodName" SG_ 351 APATotWhlToqReqVal "APATotWhlToqReqVal";
BA_ "ISignalName" SG_ 351 APATotWhlToqReqVal "IAPATotWhlToqReqVal";
BA_ "LongName" SG_ 351 APATotWhlToqReqVal "Advanced_Park_Assist_Total_Wheel_Torque_Request_Value";
BA_ "SysSignalName" SG_ 351 APATotWhlToqReqVal "APATotWhlToqReqVal";
BA_ "CompuMethodName" SG_ 351 ICBAD_20ms_Group05_Reserved6 "ICBAD_20ms_Group05_Reserved6";
BA_ "GenSigStartValue" SG_ 351 ICBAD_20ms_Group05_Reserved6 255;
BA_ "ISignalName" SG_ 351 ICBAD_20ms_Group05_Reserved6 "IICBAD_20ms_Group05_Reserved6";
BA_ "SysSignalName" SG_ 351 ICBAD_20ms_Group05_Reserved6 "ICBAD_20ms_Group05_Reserved6";
BA_ "CompuMethodName" SG_ 351 ICBAD_20ms_Group05_Reserved7 "ICBAD_20ms_Group05_Reserved7";
BA_ "GenSigStartValue" SG_ 351 ICBAD_20ms_Group05_Reserved7 255;
BA_ "ISignalName" SG_ 351 ICBAD_20ms_Group05_Reserved7 "IICBAD_20ms_Group05_Reserved7";
BA_ "SysSignalName" SG_ 351 ICBAD_20ms_Group05_Reserved7 "ICBAD_20ms_Group05_Reserved7";
BA_ "CompuMethodName" SG_ 351 ICBAD_20ms_Group05_Reserved8 "ICBAD_20ms_Group05_Reserved8";
BA_ "GenSigStartValue" SG_ 351 ICBAD_20ms_Group05_Reserved8 255;
BA_ "ISignalName" SG_ 351 ICBAD_20ms_Group05_Reserved8 "IICBAD_20ms_Group05_Reserved8";
BA_ "SysSignalName" SG_ 351 ICBAD_20ms_Group05_Reserved8 "ICBAD_20ms_Group05_Reserved8";
BA_ "CompuMethodName" SG_ 351 ICBAD_20ms_Group05_Reserved9 "ICBAD_20ms_Group05_Reserved9";
BA_ "GenSigStartValue" SG_ 351 ICBAD_20ms_Group05_Reserved9 255;
BA_ "ISignalName" SG_ 351 ICBAD_20ms_Group05_Reserved9 "IICBAD_20ms_Group05_Reserved9";
BA_ "SysSignalName" SG_ 351 ICBAD_20ms_Group05_Reserved9 "ICBAD_20ms_Group05_Reserved9";
BA_ "CompuMethodName" SG_ 351 ICBAD_20ms_Group05_Reserved10 "ICBAD_20ms_Group05_Reserved10";
BA_ "GenSigStartValue" SG_ 351 ICBAD_20ms_Group05_Reserved10 255;
BA_ "ISignalName" SG_ 351 ICBAD_20ms_Group05_Reserved10 "IICBAD_20ms_Group05_Reserved10";
BA_ "SysSignalName" SG_ 351 ICBAD_20ms_Group05_Reserved10 "ICBAD_20ms_Group05_Reserved10";
BA_ "CompuMethodName" SG_ 351 ICBAD_20ms_Group05_Reserved11 "ICBAD_20ms_Group05_Reserved11";
BA_ "GenSigStartValue" SG_ 351 ICBAD_20ms_Group05_Reserved11 255;
BA_ "ISignalName" SG_ 351 ICBAD_20ms_Group05_Reserved11 "IICBAD_20ms_Group05_Reserved11";
BA_ "SysSignalName" SG_ 351 ICBAD_20ms_Group05_Reserved11 "ICBAD_20ms_Group05_Reserved11";
BA_ "CompuMethodName" SG_ 351 ICBAD_20ms_Group05_Reserved12 "ICBAD_20ms_Group05_Reserved12";
BA_ "GenSigStartValue" SG_ 351 ICBAD_20ms_Group05_Reserved12 255;
BA_ "ISignalName" SG_ 351 ICBAD_20ms_Group05_Reserved12 "IICBAD_20ms_Group05_Reserved12";
BA_ "SysSignalName" SG_ 351 ICBAD_20ms_Group05_Reserved12 "ICBAD_20ms_Group05_Reserved12";
BA_ "CompuMethodName" SG_ 351 ICBAD_20ms_Group05_Reserved13 "ICBAD_20ms_Group05_Reserved13";
BA_ "GenSigStartValue" SG_ 351 ICBAD_20ms_Group05_Reserved13 255;
BA_ "ISignalName" SG_ 351 ICBAD_20ms_Group05_Reserved13 "IICBAD_20ms_Group05_Reserved13";
BA_ "SysSignalName" SG_ 351 ICBAD_20ms_Group05_Reserved13 "ICBAD_20ms_Group05_Reserved13";
BA_ "CompuMethodName" SG_ 351 ICBAD_20ms_Group05_Reserved14 "ICBAD_20ms_Group05_Reserved14";
BA_ "GenSigStartValue" SG_ 351 ICBAD_20ms_Group05_Reserved14 255;
BA_ "ISignalName" SG_ 351 ICBAD_20ms_Group05_Reserved14 "IICBAD_20ms_Group05_Reserved14";
BA_ "SysSignalName" SG_ 351 ICBAD_20ms_Group05_Reserved14 "ICBAD_20ms_Group05_Reserved14";
BA_ "CompuMethodName" SG_ 351 ICBAD_20ms_Group05_Reserved15 "ICBAD_20ms_Group05_Reserved15";
BA_ "GenSigStartValue" SG_ 351 ICBAD_20ms_Group05_Reserved15 255;
BA_ "ISignalName" SG_ 351 ICBAD_20ms_Group05_Reserved15 "IICBAD_20ms_Group05_Reserved15";
BA_ "SysSignalName" SG_ 351 ICBAD_20ms_Group05_Reserved15 "ICBAD_20ms_Group05_Reserved15";
BA_ "CompuMethodName" SG_ 424 ICBAD_20ms_Group12_CRC "ICBAD_20ms_Group12_CRC";
BA_ "ISignalName" SG_ 424 ICBAD_20ms_Group12_CRC "IICBAD_20ms_Group12_CRC";
BA_ "LongName" SG_ 424 ICBAD_20ms_Group12_CRC "ICBAD_20ms_Group12_CRC";
BA_ "SysSignalName" SG_ 424 ICBAD_20ms_Group12_CRC "ICBAD_20ms_Group12_CRC";
BA_ "CompuMethodName" SG_ 424 ICBAD_20ms_Group12_RC "ICBAD_20ms_Group12_RC";
BA_ "ISignalName" SG_ 424 ICBAD_20ms_Group12_RC "IICBAD_20ms_Group12_RC";
BA_ "LongName" SG_ 424 ICBAD_20ms_Group12_RC "ICBAD_20ms_Group12_RC";
BA_ "SysSignalName" SG_ 424 ICBAD_20ms_Group12_RC "ICBAD_20ms_Group12_RC";
BA_ "CompuMethodName" SG_ 424 AutodDrvngSysStsV "AutodDrvngSysStsV";
BA_ "ISignalName" SG_ 424 AutodDrvngSysStsV "IAutodDrvngSysStsV";
BA_ "LongName" SG_ 424 AutodDrvngSysStsV "Automated Driving System Status Validity";
BA_ "SysSignalName" SG_ 424 AutodDrvngSysStsV "AutodDrvngSysStsV";
BA_ "CompuMethodName" SG_ 424 ICBAD_20ms_Group12_Reserved1 "ICBAD_20ms_Group12_Reserved1";
BA_ "GenSigStartValue" SG_ 424 ICBAD_20ms_Group12_Reserved1 7;
BA_ "ISignalName" SG_ 424 ICBAD_20ms_Group12_Reserved1 "IICBAD_20ms_Group12_Reserved1";
BA_ "SysSignalName" SG_ 424 ICBAD_20ms_Group12_Reserved1 "ICBAD_20ms_Group12_Reserved1";
BA_ "CompuMethodName" SG_ 424 ICBAD_20ms_Group12_Reserved2 "ICBAD_20ms_Group12_Reserved2";
BA_ "GenSigStartValue" SG_ 424 ICBAD_20ms_Group12_Reserved2 31;
BA_ "ISignalName" SG_ 424 ICBAD_20ms_Group12_Reserved2 "IICBAD_20ms_Group12_Reserved2";
BA_ "SysSignalName" SG_ 424 ICBAD_20ms_Group12_Reserved2 "ICBAD_20ms_Group12_Reserved2";
BA_ "CompuMethodName" SG_ 424 APASts "APASts";
BA_ "ISignalName" SG_ 424 APASts "IAPASts";
BA_ "LongName" SG_ 424 APASts "Advanced_Park_Assist_Status";
BA_ "SysSignalName" SG_ 424 APASts "APASts";
BA_ "CompuMethodName" SG_ 424 AutodDrvngSysSts "AutodDrvngSysSts";
BA_ "ISignalName" SG_ 424 AutodDrvngSysSts "IAutodDrvngSysSts";
BA_ "LongName" SG_ 424 AutodDrvngSysSts "Automated_Driving_System_Status";
BA_ "SysSignalName" SG_ 424 AutodDrvngSysSts "AutodDrvngSysSts";
BA_ "CompuMethodName" SG_ 424 ICBAD_20ms_Group12_Reserved3 "ICBAD_20ms_Group12_Reserved3";
BA_ "GenSigStartValue" SG_ 424 ICBAD_20ms_Group12_Reserved3 255;
BA_ "ISignalName" SG_ 424 ICBAD_20ms_Group12_Reserved3 "IICBAD_20ms_Group12_Reserved3";
BA_ "SysSignalName" SG_ 424 ICBAD_20ms_Group12_Reserved3 "ICBAD_20ms_Group12_Reserved3";
BA_ "CompuMethodName" SG_ 424 ICBAD_20ms_Group12_Reserved4 "ICBAD_20ms_Group12_Reserved4";
BA_ "GenSigStartValue" SG_ 424 ICBAD_20ms_Group12_Reserved4 255;
BA_ "ISignalName" SG_ 424 ICBAD_20ms_Group12_Reserved4 "IICBAD_20ms_Group12_Reserved4";
BA_ "SysSignalName" SG_ 424 ICBAD_20ms_Group12_Reserved4 "ICBAD_20ms_Group12_Reserved4";
BA_ "CompuMethodName" SG_ 424 ICBAD_20ms_Group12_Reserved5 "ICBAD_20ms_Group12_Reserved5";
BA_ "GenSigStartValue" SG_ 424 ICBAD_20ms_Group12_Reserved5 255;
BA_ "ISignalName" SG_ 424 ICBAD_20ms_Group12_Reserved5 "IICBAD_20ms_Group12_Reserved5";
BA_ "SysSignalName" SG_ 424 ICBAD_20ms_Group12_Reserved5 "ICBAD_20ms_Group12_Reserved5";
BA_ "CompuMethodName" SG_ 424 ICBAD_20ms_Group12_Reserved6 "ICBAD_20ms_Group12_Reserved6";
BA_ "GenSigStartValue" SG_ 424 ICBAD_20ms_Group12_Reserved6 255;
BA_ "ISignalName" SG_ 424 ICBAD_20ms_Group12_Reserved6 "IICBAD_20ms_Group12_Reserved6";
BA_ "SysSignalName" SG_ 424 ICBAD_20ms_Group12_Reserved6 "ICBAD_20ms_Group12_Reserved6";
BA_ "CompuMethodName" SG_ 431 ICBAD_20ms_Group15_CRC "ICBAD_20ms_Group15_CRC";
BA_ "ISignalName" SG_ 431 ICBAD_20ms_Group15_CRC "IICBAD_20ms_Group15_CRC";
BA_ "LongName" SG_ 431 ICBAD_20ms_Group15_CRC "ICBAD_20ms_Group15_CRC";
BA_ "SysSignalName" SG_ 431 ICBAD_20ms_Group15_CRC "ICBAD_20ms_Group15_CRC";
BA_ "CompuMethodName" SG_ 431 ICBAD_20ms_Group15_RC "ICBAD_20ms_Group15_RC";
BA_ "ISignalName" SG_ 431 ICBAD_20ms_Group15_RC "IICBAD_20ms_Group15_RC";
BA_ "LongName" SG_ 431 ICBAD_20ms_Group15_RC "ICBAD_20ms_Group15_RC";
BA_ "SysSignalName" SG_ 431 ICBAD_20ms_Group15_RC "ICBAD_20ms_Group15_RC";
BA_ "CompuMethodName" SG_ 431 ACCDclReqSts "ACCDclReqSts";
BA_ "ISignalName" SG_ 431 ACCDclReqSts "IACCDclReqSts";
BA_ "LongName" SG_ 431 ACCDclReqSts "Adaptive Cruise Control Deceleration Request Status";
BA_ "SysSignalName" SG_ 431 ACCDclReqSts "ACCDclReqSts";
BA_ "CompuMethodName" SG_ 431 ICBAD_20ms_Group15_Reserved1 "ICBAD_20ms_Group15_Reserved1";
BA_ "GenSigStartValue" SG_ 431 ICBAD_20ms_Group15_Reserved1 3;
BA_ "ISignalName" SG_ 431 ICBAD_20ms_Group15_Reserved1 "IICBAD_20ms_Group15_Reserved1";
BA_ "SysSignalName" SG_ 431 ICBAD_20ms_Group15_Reserved1 "ICBAD_20ms_Group15_Reserved1";
BA_ "CompuMethodName" SG_ 431 ICBAD_20ms_Group15_Reserved2 "ICBAD_20ms_Group15_Reserved2";
BA_ "GenSigStartValue" SG_ 431 ICBAD_20ms_Group15_Reserved2 255;
BA_ "ISignalName" SG_ 431 ICBAD_20ms_Group15_Reserved2 "IICBAD_20ms_Group15_Reserved2";
BA_ "SysSignalName" SG_ 431 ICBAD_20ms_Group15_Reserved2 "ICBAD_20ms_Group15_Reserved2";
BA_ "CompuMethodName" SG_ 431 ACCOtptShaftTotToqReqVal "ACCOtptShaftTotToqReqVal";
BA_ "GenSigStartValue" SG_ 431 ACCOtptShaftTotToqReqVal 1696;
BA_ "ISignalName" SG_ 431 ACCOtptShaftTotToqReqVal "IACCOtptShaftTotToqReqVal";
BA_ "LongName" SG_ 431 ACCOtptShaftTotToqReqVal "Adaptive Cruise Control Output Shaft Total Torque Request Value";
BA_ "SysSignalName" SG_ 431 ACCOtptShaftTotToqReqVal "ACCOtptShaftTotToqReqVal";
BA_ "CompuMethodName" SG_ 431 ICBAD_20ms_Group15_Reserved3 "ICBAD_20ms_Group15_Reserved3";
BA_ "GenSigStartValue" SG_ 431 ICBAD_20ms_Group15_Reserved3 3;
BA_ "ISignalName" SG_ 431 ICBAD_20ms_Group15_Reserved3 "IICBAD_20ms_Group15_Reserved3";
BA_ "SysSignalName" SG_ 431 ICBAD_20ms_Group15_Reserved3 "ICBAD_20ms_Group15_Reserved3";
BA_ "CompuMethodName" SG_ 431 ACCOtptShaftTotToqReqSts "ACCOtptShaftTotToqReqSts";
BA_ "ISignalName" SG_ 431 ACCOtptShaftTotToqReqSts "IACCOtptShaftTotToqReqSts";
BA_ "LongName" SG_ 431 ACCOtptShaftTotToqReqSts "Adaptive Cruise Control Output Shaft Total Torque Request Status";
BA_ "SysSignalName" SG_ 431 ACCOtptShaftTotToqReqSts "ACCOtptShaftTotToqReqSts";
BA_ "CompuMethodName" SG_ 431 AutodDrvngSysStsPT "AutodDrvngSysStsPT";
BA_ "ISignalName" SG_ 431 AutodDrvngSysStsPT "IAutodDrvngSysStsPT";
BA_ "LongName" SG_ 431 AutodDrvngSysStsPT "Automated Driving System Status PT";
BA_ "SysSignalName" SG_ 431 AutodDrvngSysStsPT "AutodDrvngSysStsPT";
BA_ "CompuMethodName" SG_ 431 ICBAD_20ms_Group15_Reserved4 "ICBAD_20ms_Group15_Reserved4";
BA_ "GenSigStartValue" SG_ 431 ICBAD_20ms_Group15_Reserved4 255;
BA_ "ISignalName" SG_ 431 ICBAD_20ms_Group15_Reserved4 "IICBAD_20ms_Group15_Reserved4";
BA_ "SysSignalName" SG_ 431 ICBAD_20ms_Group15_Reserved4 "ICBAD_20ms_Group15_Reserved4";
BA_ "CompuMethodName" SG_ 431 ICBAD_20ms_Group15_Reserved5 "ICBAD_20ms_Group15_Reserved5";
BA_ "GenSigStartValue" SG_ 431 ICBAD_20ms_Group15_Reserved5 255;
BA_ "ISignalName" SG_ 431 ICBAD_20ms_Group15_Reserved5 "IICBAD_20ms_Group15_Reserved5";
BA_ "SysSignalName" SG_ 431 ICBAD_20ms_Group15_Reserved5 "ICBAD_20ms_Group15_Reserved5";
BA_ "CompuMethodName" SG_ 431 ICBAD_20ms_Group15_Reserved6 "ICBAD_20ms_Group15_Reserved6";
BA_ "GenSigStartValue" SG_ 431 ICBAD_20ms_Group15_Reserved6 255;
BA_ "ISignalName" SG_ 431 ICBAD_20ms_Group15_Reserved6 "IICBAD_20ms_Group15_Reserved6";
BA_ "SysSignalName" SG_ 431 ICBAD_20ms_Group15_Reserved6 "ICBAD_20ms_Group15_Reserved6";
BA_ "CompuMethodName" SG_ 431 ICBAD_20ms_Group15_Reserved7 "ICBAD_20ms_Group15_Reserved7";
BA_ "GenSigStartValue" SG_ 431 ICBAD_20ms_Group15_Reserved7 255;
BA_ "ISignalName" SG_ 431 ICBAD_20ms_Group15_Reserved7 "IICBAD_20ms_Group15_Reserved7";
BA_ "SysSignalName" SG_ 431 ICBAD_20ms_Group15_Reserved7 "ICBAD_20ms_Group15_Reserved7";
BA_ "CompuMethodName" SG_ 431 ICBAD_20ms_Group15_Reserved8 "ICBAD_20ms_Group15_Reserved8";
BA_ "GenSigStartValue" SG_ 431 ICBAD_20ms_Group15_Reserved8 255;
BA_ "ISignalName" SG_ 431 ICBAD_20ms_Group15_Reserved8 "IICBAD_20ms_Group15_Reserved8";
BA_ "SysSignalName" SG_ 431 ICBAD_20ms_Group15_Reserved8 "ICBAD_20ms_Group15_Reserved8";
BA_ "CompuMethodName" SG_ 431 ICBAD_20ms_Group15_Reserved9 "ICBAD_20ms_Group15_Reserved9";
BA_ "GenSigStartValue" SG_ 431 ICBAD_20ms_Group15_Reserved9 255;
BA_ "ISignalName" SG_ 431 ICBAD_20ms_Group15_Reserved9 "IICBAD_20ms_Group15_Reserved9";
BA_ "SysSignalName" SG_ 431 ICBAD_20ms_Group15_Reserved9 "ICBAD_20ms_Group15_Reserved9";
BA_ "CompuMethodName" SG_ 81 ICBAD_ZONE_20ms_Group13_CRC "ICBAD_ZONE_20ms_Group13_CRC";
BA_ "ISignalName" SG_ 81 ICBAD_ZONE_20ms_Group13_CRC "IICBAD_ZONE_20ms_Group13_CRC";
BA_ "LongName" SG_ 81 ICBAD_ZONE_20ms_Group13_CRC "ICBAD_ZONE_20ms_Group13_CRC";
BA_ "SysSignalName" SG_ 81 ICBAD_ZONE_20ms_Group13_CRC "ICBAD_ZONE_20ms_Group13_CRC";
BA_ "CompuMethodName" SG_ 81 ICBAD_ZONE_20ms_Group13_RC "ICBAD_ZONE_20ms_Group13_RC";
BA_ "ISignalName" SG_ 81 ICBAD_ZONE_20ms_Group13_RC "IICBAD_ZONE_20ms_Group13_RC";
BA_ "LongName" SG_ 81 ICBAD_ZONE_20ms_Group13_RC "ICBAD_ZONE_20ms_Group13_RC";
BA_ "SysSignalName" SG_ 81 ICBAD_ZONE_20ms_Group13_RC "ICBAD_ZONE_20ms_Group13_RC";
BA_ "CompuMethodName" SG_ 81 ICBAD_ZONE_20ms_Group13_Reserved0 "ICBAD_ZONE_20ms_Group13_Reserved1";
BA_ "GenSigStartValue" SG_ 81 ICBAD_ZONE_20ms_Group13_Reserved0 1;
BA_ "ISignalName" SG_ 81 ICBAD_ZONE_20ms_Group13_Reserved0 "IICBAD_ZONE_20ms_Group13_Reserved1";
BA_ "SysSignalName" SG_ 81 ICBAD_ZONE_20ms_Group13_Reserved0 "ICBAD_ZONE_20ms_Group13_Reserved1";
BA_ "SystemSignalLongSymbol" SG_ 81 ICBAD_ZONE_20ms_Group13_Reserved0 "ICBAD_ZONE_20ms_Group13_Reserved1";
BA_ "CompuMethodName" SG_ 81 TJAICASysFltSts "TJAICASysFltSts";
BA_ "ISignalName" SG_ 81 TJAICASysFltSts "ITJAICASysFltSts";
BA_ "LongName" SG_ 81 TJAICASysFltSts "Traffic Jam Assist Integrated Cruise Assist Fault Status";
BA_ "SysSignalName" SG_ 81 TJAICASysFltSts "TJAICASysFltSts";
BA_ "CompuMethodName" SG_ 81 ACCToqReqSts "ACCToqReqSts";
BA_ "ISignalName" SG_ 81 ACCToqReqSts "IACCToqReqSts";
BA_ "SysSignalName" SG_ 81 ACCToqReqSts "ACCToqReqSts";
BA_ "CompuMethodName" SG_ 81 LKASysFltSts "LKASysFltSts";
BA_ "ISignalName" SG_ 81 LKASysFltSts "ILKASysFltSts";
BA_ "LongName" SG_ 81 LKASysFltSts "Lane Keeping Assist System Fault Status";
BA_ "SysSignalName" SG_ 81 LKASysFltSts "LKASysFltSts";
BA_ "CompuMethodName" SG_ 81 ICBAD_ZONE_20ms_Group13_Reserved1 "ICBAD_ZONE_20ms_Group13_Reserved2";
BA_ "GenSigStartValue" SG_ 81 ICBAD_ZONE_20ms_Group13_Reserved1 7;
BA_ "ISignalName" SG_ 81 ICBAD_ZONE_20ms_Group13_Reserved1 "IICBAD_ZONE_20ms_Group13_Reserved2";
BA_ "SysSignalName" SG_ 81 ICBAD_ZONE_20ms_Group13_Reserved1 "ICBAD_ZONE_20ms_Group13_Reserved2";
BA_ "SystemSignalLongSymbol" SG_ 81 ICBAD_ZONE_20ms_Group13_Reserved1 "ICBAD_ZONE_20ms_Group13_Reserved2";
BA_ "CompuMethodName" SG_ 81 ICBAD_ZONE_20ms_Group13_Reserved2 "ICBAD_ZONE_20ms_Group13_Reserved3";
BA_ "GenSigStartValue" SG_ 81 ICBAD_ZONE_20ms_Group13_Reserved2 3;
BA_ "ISignalName" SG_ 81 ICBAD_ZONE_20ms_Group13_Reserved2 "IICBAD_ZONE_20ms_Group13_Reserved3";
BA_ "SysSignalName" SG_ 81 ICBAD_ZONE_20ms_Group13_Reserved2 "ICBAD_ZONE_20ms_Group13_Reserved3";
BA_ "SystemSignalLongSymbol" SG_ 81 ICBAD_ZONE_20ms_Group13_Reserved2 "ICBAD_ZONE_20ms_Group13_Reserved3";
BA_ "CompuMethodName" SG_ 81 TJAICASysSts "TJAICASysSts";
BA_ "ISignalName" SG_ 81 TJAICASysSts "ITJAICASysSts";
BA_ "LongName" SG_ 81 TJAICASysSts "Traffic Jam Assist Integrated Cruise Assist System Status";
BA_ "SysSignalName" SG_ 81 TJAICASysSts "TJAICASysSts";
BA_ "CompuMethodName" SG_ 81 LKASysSts "LKASysSts";
BA_ "ISignalName" SG_ 81 LKASysSts "ILKASysSts";
BA_ "LongName" SG_ 81 LKASysSts "Lane Keeping Assist System Status";
BA_ "SysSignalName" SG_ 81 LKASysSts "LKASysSts";
BA_ "CompuMethodName" SG_ 81 ACCToqReqVal "ACCToqReqVal";
BA_ "GenSigStartValue" SG_ 81 ACCToqReqVal 1696;
BA_ "ISignalName" SG_ 81 ACCToqReqVal "IACCToqReqVal";
BA_ "SysSignalName" SG_ 81 ACCToqReqVal "ACCToqReqVal";
BA_ "CompuMethodName" SG_ 81 ICBAD_ZONE_20ms_Group13_Reserved3 "ICBAD_ZONE_20ms_Group13_Reserved4";
BA_ "GenSigStartValue" SG_ 81 ICBAD_ZONE_20ms_Group13_Reserved3 15;
BA_ "ISignalName" SG_ 81 ICBAD_ZONE_20ms_Group13_Reserved3 "IICBAD_ZONE_20ms_Group13_Reserved4";
BA_ "SysSignalName" SG_ 81 ICBAD_ZONE_20ms_Group13_Reserved3 "ICBAD_ZONE_20ms_Group13_Reserved4";
BA_ "SystemSignalLongSymbol" SG_ 81 ICBAD_ZONE_20ms_Group13_Reserved3 "ICBAD_ZONE_20ms_Group13_Reserved4";
BA_ "CompuMethodName" SG_ 81 ICBAD_ZONE_20ms_Group13_Reserved4 "ICBAD_ZONE_20ms_Group13_Reserved5";
BA_ "GenSigStartValue" SG_ 81 ICBAD_ZONE_20ms_Group13_Reserved4 255;
BA_ "ISignalName" SG_ 81 ICBAD_ZONE_20ms_Group13_Reserved4 "IICBAD_ZONE_20ms_Group13_Reserved5";
BA_ "SysSignalName" SG_ 81 ICBAD_ZONE_20ms_Group13_Reserved4 "ICBAD_ZONE_20ms_Group13_Reserved5";
BA_ "SystemSignalLongSymbol" SG_ 81 ICBAD_ZONE_20ms_Group13_Reserved4 "ICBAD_ZONE_20ms_Group13_Reserved5";
BA_ "CompuMethodName" SG_ 81 ICBAD_ZONE_20ms_Group13_Reserved5 "ICBAD_ZONE_20ms_Group13_Reserved6";
BA_ "GenSigStartValue" SG_ 81 ICBAD_ZONE_20ms_Group13_Reserved5 255;
BA_ "ISignalName" SG_ 81 ICBAD_ZONE_20ms_Group13_Reserved5 "IICBAD_ZONE_20ms_Group13_Reserved6";
BA_ "SysSignalName" SG_ 81 ICBAD_ZONE_20ms_Group13_Reserved5 "ICBAD_ZONE_20ms_Group13_Reserved6";
BA_ "SystemSignalLongSymbol" SG_ 81 ICBAD_ZONE_20ms_Group13_Reserved5 "ICBAD_ZONE_20ms_Group13_Reserved6";
BA_ "CompuMethodName" SG_ 1329 LghtWlcmMdReq "LghtWlcmMdReq";
BA_ "ISignalName" SG_ 1329 LghtWlcmMdReq "ILghtWlcmMdReq";
BA_ "LongName" SG_ 1329 LghtWlcmMdReq "Light Welcome Mode Request";
BA_ "SysSignalName" SG_ 1329 LghtWlcmMdReq "LghtWlcmMdReq";
BA_ "CompuMethodName" SG_ 1329 AvgFuelCsumpPrcs "AvgFuelCsumpPrcs";
BA_ "ISignalName" SG_ 1329 AvgFuelCsumpPrcs "IAvgFuelCsumpPrcs";
BA_ "LongName" SG_ 1329 AvgFuelCsumpPrcs "Average Fuel Consumption Precision";
BA_ "SysSignalName" SG_ 1329 AvgFuelCsumpPrcs "AvgFuelCsumpPrcs";
BA_ "CompuMethodName" SG_ 1329 IgnOffTime "IgnOffTime";
BA_ "GenSigStartValue" SG_ 1329 IgnOffTime 4095;
BA_ "ISignalName" SG_ 1329 IgnOffTime "IIgnOffTime";
BA_ "LongName" SG_ 1329 IgnOffTime "Ignition Off Time";
BA_ "SysSignalName" SG_ 1329 IgnOffTime "IgnOffTime";
BA_ "CompuMethodName" SG_ 1329 AvgFuelCsumpPrcsV "AvgFuelCsumpPrcsV";
BA_ "GenSigStartValue" SG_ 1329 AvgFuelCsumpPrcsV 1;
BA_ "ISignalName" SG_ 1329 AvgFuelCsumpPrcsV "IAvgFuelCsumpPrcsV";
BA_ "LongName" SG_ 1329 AvgFuelCsumpPrcsV "Average Fuel Consumption Precision Validity";
BA_ "SysSignalName" SG_ 1329 AvgFuelCsumpPrcsV "AvgFuelCsumpPrcsV";
BA_ "CompuMethodName" SG_ 1329 AvgFuelCsumpV "AvgFuelCsumpV";
BA_ "GenSigStartValue" SG_ 1329 AvgFuelCsumpV 1;
BA_ "ISignalName" SG_ 1329 AvgFuelCsumpV "IAvgFuelCsumpV";
BA_ "LongName" SG_ 1329 AvgFuelCsumpV "Average Fuel Consumption Validity";
BA_ "SysSignalName" SG_ 1329 AvgFuelCsumpV "AvgFuelCsumpV";
BA_ "CompuMethodName" SG_ 1329 IgnOffTimeV "IgnOffTimeV";
BA_ "ISignalName" SG_ 1329 IgnOffTimeV "IIgnOffTimeV";
BA_ "LongName" SG_ 1329 IgnOffTimeV "Ignition Off Time Valid";
BA_ "SysSignalName" SG_ 1329 IgnOffTimeV "IgnOffTimeV";
BA_ "CompuMethodName" SG_ 1329 AvgFuelCsump "AvgFuelCsump";
BA_ "ISignalName" SG_ 1329 AvgFuelCsump "IAvgFuelCsump";
BA_ "LongName" SG_ 1329 AvgFuelCsump "Average Fuel Consumption";
BA_ "SysSignalName" SG_ 1329 AvgFuelCsump "AvgFuelCsump";
BA_ "CompuMethodName" SG_ 1329 RCPDMdSwReq "RCPDMdSwReq";
BA_ "ISignalName" SG_ 1329 RCPDMdSwReq "IRCPDMdSwReq";
BA_ "LongName" SG_ 1329 RCPDMdSwReq "Rear Child Presence Detection Mode Switch Request";
BA_ "SysSignalName" SG_ 1329 RCPDMdSwReq "RCPDMdSwReq";
BA_ "CompuMethodName" SG_ 1329 RCPDDlyTimeSwReq "RCPDDlyTimeSwReq";
BA_ "ISignalName" SG_ 1329 RCPDDlyTimeSwReq "IRCPDDlyTimeSwReq";
BA_ "LongName" SG_ 1329 RCPDDlyTimeSwReq "Rear Child Presence Detection Delay Time Switch Request";
BA_ "SysSignalName" SG_ 1329 RCPDDlyTimeSwReq "RCPDDlyTimeSwReq";
BA_ "CompuMethodName" SG_ 1023 ICBVC_100ms_Group19_CRC "ICBVC_100ms_Group19_CRC";
BA_ "ISignalName" SG_ 1023 ICBVC_100ms_Group19_CRC "IICBVC_100ms_Group19_CRC";
BA_ "SysSignalName" SG_ 1023 ICBVC_100ms_Group19_CRC "ICBVC_100ms_Group19_CRC";
BA_ "CompuMethodName" SG_ 1023 ICBVC_100ms_Group19_RC "ICBVC_100ms_Group19_RC";
BA_ "ISignalName" SG_ 1023 ICBVC_100ms_Group19_RC "IICBVC_100ms_Group19_RC";
BA_ "SysSignalName" SG_ 1023 ICBVC_100ms_Group19_RC "ICBVC_100ms_Group19_RC";
BA_ "CompuMethodName" SG_ 1023 RgnLvReqFICMV "RgnLvReqFICMV";
BA_ "GenSigStartValue" SG_ 1023 RgnLvReqFICMV 1;
BA_ "ISignalName" SG_ 1023 RgnLvReqFICMV "IRgnLvReqFICMV";
BA_ "LongName" SG_ 1023 RgnLvReqFICMV "Regen Level Request Front Infotainment Control Module Validity";
BA_ "SysSignalName" SG_ 1023 RgnLvReqFICMV "RgnLvReqFICMV";
BA_ "CompuMethodName" SG_ 1023 RgnLvReqFICM "RgnLvReqFICM";
BA_ "GenSigStartValue" SG_ 1023 RgnLvReqFICM 1;
BA_ "ISignalName" SG_ 1023 RgnLvReqFICM "IRgnLvReqFICM";
BA_ "LongName" SG_ 1023 RgnLvReqFICM "Regen Level Request Front Infotainment Control Module";
BA_ "SysSignalName" SG_ 1023 RgnLvReqFICM "RgnLvReqFICM";
BA_ "CompuMethodName" SG_ 1023 LVBatChrgReqRaw "LVBatChrgReqRaw";
BA_ "ISignalName" SG_ 1023 LVBatChrgReqRaw "ILVBatChrgReqRaw";
BA_ "LongName" SG_ 1023 LVBatChrgReqRaw "Low Voltage Battery Charge Request Raw";
BA_ "SysSignalName" SG_ 1023 LVBatChrgReqRaw "LVBatChrgReqRaw";
BA_ "CompuMethodName" SG_ 1023 LVBatChrgReqInhbt "LVBatChrgReqInhbt";
BA_ "ISignalName" SG_ 1023 LVBatChrgReqInhbt "ILVBatChrgReqInhbt";
BA_ "LongName" SG_ 1023 LVBatChrgReqInhbt "Low Voltage Battery Charge Request Inhibit flag";
BA_ "SysSignalName" SG_ 1023 LVBatChrgReqInhbt "LVBatChrgReqInhbt";
BA_ "CompuMethodName" SG_ 1023 LVBatEnrgSufct "LVBatEnrgSufct";
BA_ "ISignalName" SG_ 1023 LVBatEnrgSufct "ILVBatEnrgSufct";
BA_ "LongName" SG_ 1023 LVBatEnrgSufct "Low Voltage Battery Energy Sufficient";
BA_ "SysSignalName" SG_ 1023 LVBatEnrgSufct "LVBatEnrgSufct";
BA_ "CompuMethodName" SG_ 1023 LVBatEnrgLow "LVBatEnrgLow";
BA_ "GenSigStartValue" SG_ 1023 LVBatEnrgLow 1;
BA_ "ISignalName" SG_ 1023 LVBatEnrgLow "ILVBatEnrgLow";
BA_ "LongName" SG_ 1023 LVBatEnrgLow "Low Voltage Battery Energy Low";
BA_ "SysSignalName" SG_ 1023 LVBatEnrgLow "LVBatEnrgLow";
BA_ "CompuMethodName" SG_ 1023 ICBVC_100ms_Group19_Reserved21 "ICBVC_100ms_Group19_Reserved21";
BA_ "GenSigStartValue" SG_ 1023 ICBVC_100ms_Group19_Reserved21 3;
BA_ "ISignalName" SG_ 1023 ICBVC_100ms_Group19_Reserved21 "IICBVC_100ms_Group19_Reserved21";
BA_ "SysSignalName" SG_ 1023 ICBVC_100ms_Group19_Reserved21 "ICBVC_100ms_Group19_Reserved21";
BA_ "CompuMethodName" SG_ 1023 EnrgSplReqV "EnrgSplReqV";
BA_ "GenSigStartValue" SG_ 1023 EnrgSplReqV 1;
BA_ "ISignalName" SG_ 1023 EnrgSplReqV "IEnrgSplReqV";
BA_ "LongName" SG_ 1023 EnrgSplReqV "Energy_Supply_Request_Validity";
BA_ "SysSignalName" SG_ 1023 EnrgSplReqV "EnrgSplReqV";
BA_ "CompuMethodName" SG_ 1023 EnrgSplReq "EnrgSplReq";
BA_ "ISignalName" SG_ 1023 EnrgSplReq "IEnrgSplReq";
BA_ "LongName" SG_ 1023 EnrgSplReq "Energy_Supply_Request";
BA_ "SysSignalName" SG_ 1023 EnrgSplReq "EnrgSplReq";
BA_ "CompuMethodName" SG_ 1023 PMDCSta "PMDCSta";
BA_ "ISignalName" SG_ 1023 PMDCSta "IPMDCSta";
BA_ "LongName" SG_ 1023 PMDCSta "Power_Management_Direct_Current_Converter_State";
BA_ "SysSignalName" SG_ 1023 PMDCSta "PMDCSta";
BA_ "CompuMethodName" SG_ 1023 EPMOprtMd "EPMOprtMd";
BA_ "ISignalName" SG_ 1023 EPMOprtMd "IEPMOprtMd";
BA_ "LongName" SG_ 1023 EPMOprtMd "Electric_Power_Management_Operation_Mode";
BA_ "SysSignalName" SG_ 1023 EPMOprtMd "EPMOprtMd";
BA_ "CompuMethodName" SG_ 1023 ICBVC_100ms_Group19_Reserved35 "ICBVC_100ms_Group19_Reserved35";
BA_ "GenSigStartValue" SG_ 1023 ICBVC_100ms_Group19_Reserved35 15;
BA_ "ISignalName" SG_ 1023 ICBVC_100ms_Group19_Reserved35 "IICBVC_100ms_Group19_Reserved35";
BA_ "SysSignalName" SG_ 1023 ICBVC_100ms_Group19_Reserved35 "ICBVC_100ms_Group19_Reserved35";
BA_ "CompuMethodName" SG_ 1023 VehEnrgRdyLvlV "VehEnrgRdyLvlV";
BA_ "ISignalName" SG_ 1023 VehEnrgRdyLvlV "IVehEnrgRdyLvlV";
BA_ "LongName" SG_ 1023 VehEnrgRdyLvlV "Vehicle_Energy_Ready_Level_Validity";
BA_ "SysSignalName" SG_ 1023 VehEnrgRdyLvlV "VehEnrgRdyLvlV";
BA_ "CompuMethodName" SG_ 1023 VehEnrgRdyLvl "VehEnrgRdyLvl";
BA_ "GenSigStartValue" SG_ 1023 VehEnrgRdyLvl 1;
BA_ "ISignalName" SG_ 1023 VehEnrgRdyLvl "IVehEnrgRdyLvl";
BA_ "LongName" SG_ 1023 VehEnrgRdyLvl "Vehicle_Energy_Ready_Level";
BA_ "SysSignalName" SG_ 1023 VehEnrgRdyLvl "VehEnrgRdyLvl";
BA_ "CompuMethodName" SG_ 1023 EPMCurEstdCapct "EPMCurEstdCapct";
BA_ "ISignalName" SG_ 1023 EPMCurEstdCapct "IEPMCurEstdCapct";
BA_ "LongName" SG_ 1023 EPMCurEstdCapct "Electric_Power_Management_Current
Estimated Capacity";
BA_ "SysSignalName" SG_ 1023 EPMCurEstdCapct "EPMCurEstdCapct";
BA_ "CompuMethodName" SG_ 1023 EPMMaxEstdCapct "EPMMaxEstdCapct";
BA_ "ISignalName" SG_ 1023 EPMMaxEstdCapct "IEPMMaxEstdCapct";
BA_ "LongName" SG_ 1023 EPMMaxEstdCapct "Electric_Power_Management_Maximum
Estimated Capacity";
BA_ "SysSignalName" SG_ 1023 EPMMaxEstdCapct "EPMMaxEstdCapct";
BA_ "CompuMethodName" SG_ 1023 LVBMDisChrgMOSCtrl "LVBMDisChrgMOSCtrl";
BA_ "ISignalName" SG_ 1023 LVBMDisChrgMOSCtrl "ILVBMDisChrgMOSCtrl";
BA_ "LongName" SG_ 1023 LVBMDisChrgMOSCtrl "Low Voltage Battery Module Discharge Mos Control";
BA_ "SysSignalName" SG_ 1023 LVBMDisChrgMOSCtrl "LVBMDisChrgMOSCtrl";
BA_ "CompuMethodName" SG_ 1023 AuxBatUnAssembled "AuxBatUnAssembled";
BA_ "ISignalName" SG_ 1023 AuxBatUnAssembled "IAuxBatUnAssembled";
BA_ "LongName" SG_ 1023 AuxBatUnAssembled "Auxiliary Battery UnAssemled";
BA_ "SysSignalName" SG_ 1023 AuxBatUnAssembled "AuxBatUnAssembled";
BA_ "CompuMethodName" SG_ 1023 ICBVC_100ms_Group19_Reserved58 "ICBVC_100ms_Group19_Reserved58";
BA_ "GenSigStartValue" SG_ 1023 ICBVC_100ms_Group19_Reserved58 1;
BA_ "ISignalName" SG_ 1023 ICBVC_100ms_Group19_Reserved58 "IICBVC_100ms_Group19_Reserved58";
BA_ "SysSignalName" SG_ 1023 ICBVC_100ms_Group19_Reserved58 "ICBVC_100ms_Group19_Reserved58";
BA_ "CompuMethodName" SG_ 1023 EPTToqCustSetngReqV "EPTToqCustSetngReqV";
BA_ "GenSigStartValue" SG_ 1023 EPTToqCustSetngReqV 1;
BA_ "ISignalName" SG_ 1023 EPTToqCustSetngReqV "IEPTToqCustSetngReqV";
BA_ "SysSignalName" SG_ 1023 EPTToqCustSetngReqV "EPTToqCustSetngReqV";
BA_ "CompuMethodName" SG_ 1023 EPTToqCustSetngReq "EPTToqCustSetngReq";
BA_ "GenSigStartValue" SG_ 1023 EPTToqCustSetngReq 2;
BA_ "ISignalName" SG_ 1023 EPTToqCustSetngReq "IEPTToqCustSetngReq";
BA_ "SysSignalName" SG_ 1023 EPTToqCustSetngReq "EPTToqCustSetngReq";
BA_ "CompuMethodName" SG_ 1023 LVBatSelfWakeupFlg "LVBatSelfWakeupFlg";
BA_ "ISignalName" SG_ 1023 LVBatSelfWakeupFlg "ILVBatSelfWakeupFlg";
BA_ "LongName" SG_ 1023 LVBatSelfWakeupFlg "ECU self wake-up flag";
BA_ "SysSignalName" SG_ 1023 LVBatSelfWakeupFlg "LVBatSelfWakeupFlg";
BA_ "CompuMethodName" SG_ 1023 EnrgSplReqRaw "EnrgSplReqRaw";
BA_ "ISignalName" SG_ 1023 EnrgSplReqRaw "IEnrgSplReqRaw";
BA_ "LongName" SG_ 1023 EnrgSplReqRaw "Vehicle Enregy Supply Rquest Raw Value";
BA_ "SysSignalName" SG_ 1023 EnrgSplReqRaw "EnrgSplReqRaw";
BA_ "CompuMethodName" SG_ 486 IPD_20ms_Group43_CRC "IPD_20ms_Group43_CRC";
BA_ "ISignalName" SG_ 486 IPD_20ms_Group43_CRC "IIPD_20ms_Group43_CRC";
BA_ "LongName" SG_ 486 IPD_20ms_Group43_CRC "IPD_20ms_Group43_CRC";
BA_ "SysSignalName" SG_ 486 IPD_20ms_Group43_CRC "IPD_20ms_Group43_CRC";
BA_ "CompuMethodName" SG_ 486 IPD_20ms_Group43_RC "IPD_20ms_Group43_RC";
BA_ "ISignalName" SG_ 486 IPD_20ms_Group43_RC "IIPD_20ms_Group43_RC";
BA_ "LongName" SG_ 486 IPD_20ms_Group43_RC "IPD_20ms_Group43_RC";
BA_ "SysSignalName" SG_ 486 IPD_20ms_Group43_RC "IPD_20ms_Group43_RC";
BA_ "CompuMethodName" SG_ 486 IPD_20ms_Group43_Reserved1 "IPD_20ms_Group43_Reserved1";
BA_ "GenSigStartValue" SG_ 486 IPD_20ms_Group43_Reserved1 15;
BA_ "ISignalName" SG_ 486 IPD_20ms_Group43_Reserved1 "IIPD_20ms_Group43_Reserved1";
BA_ "SysSignalName" SG_ 486 IPD_20ms_Group43_Reserved1 "IPD_20ms_Group43_Reserved1";
BA_ "CompuMethodName" SG_ 486 ACCAccReqToqVal "ACCAccReqToqVal";
BA_ "ISignalName" SG_ 486 ACCAccReqToqVal "IACCAccReqToqVal";
BA_ "LongName" SG_ 486 ACCAccReqToqVal "Adaptive Cruise Control Acceleration Request Torque Value";
BA_ "SysSignalName" SG_ 486 ACCAccReqToqVal "ACCAccReqToqVal";
BA_ "CompuMethodName" SG_ 486 IPD_20ms_Group43_Reserved2 "IPD_20ms_Group43_Reserved2";
BA_ "GenSigStartValue" SG_ 486 IPD_20ms_Group43_Reserved2 7;
BA_ "ISignalName" SG_ 486 IPD_20ms_Group43_Reserved2 "IIPD_20ms_Group43_Reserved2";
BA_ "SysSignalName" SG_ 486 IPD_20ms_Group43_Reserved2 "IPD_20ms_Group43_Reserved2";
BA_ "CompuMethodName" SG_ 486 FrtCarGoNotfr "FrtCarGoNotfr";
BA_ "ISignalName" SG_ 486 FrtCarGoNotfr "IFrtCarGoNotfr";
BA_ "LongName" SG_ 486 FrtCarGoNotfr "FrontCar GoNotifier";
BA_ "SysSignalName" SG_ 486 FrtCarGoNotfr "FrtCarGoNotfr";
BA_ "CompuMethodName" SG_ 486 ACCSysFltSts_SCS "ACCSysFltSts_SCS";
BA_ "ISignalName" SG_ 486 ACCSysFltSts_SCS "IACCSysFltSts_SCS";
BA_ "LongName" SG_ 486 ACCSysFltSts_SCS "Adaptive_Cruise_Control_System_Fault_Status";
BA_ "SysSignalName" SG_ 486 ACCSysFltSts_SCS "ACCSysFltSts_SCS";
BA_ "CompuMethodName" SG_ 486 IPD_20ms_Group43_Reserved3 "IPD_20ms_Group43_Reserved3";
BA_ "GenSigStartValue" SG_ 486 IPD_20ms_Group43_Reserved3 255;
BA_ "ISignalName" SG_ 486 IPD_20ms_Group43_Reserved3 "IIPD_20ms_Group43_Reserved3";
BA_ "SysSignalName" SG_ 486 IPD_20ms_Group43_Reserved3 "IPD_20ms_Group43_Reserved3";
BA_ "CompuMethodName" SG_ 486 IPD_20ms_Group43_Reserved4 "IPD_20ms_Group43_Reserved4";
BA_ "GenSigStartValue" SG_ 486 IPD_20ms_Group43_Reserved4 255;
BA_ "ISignalName" SG_ 486 IPD_20ms_Group43_Reserved4 "IIPD_20ms_Group43_Reserved4";
BA_ "SysSignalName" SG_ 486 IPD_20ms_Group43_Reserved4 "IPD_20ms_Group43_Reserved4";
BA_ "CompuMethodName" SG_ 486 IPD_20ms_Group43_Reserved5 "IPD_20ms_Group43_Reserved5";
BA_ "GenSigStartValue" SG_ 486 IPD_20ms_Group43_Reserved5 255;
BA_ "ISignalName" SG_ 486 IPD_20ms_Group43_Reserved5 "IIPD_20ms_Group43_Reserved5";
BA_ "SysSignalName" SG_ 486 IPD_20ms_Group43_Reserved5 "IPD_20ms_Group43_Reserved5";
BA_ "CompuMethodName" SG_ 733 IPD_50ms_Group49_CRC "IPD_50ms_Group49_CRC";
BA_ "ISignalName" SG_ 733 IPD_50ms_Group49_CRC "IIPD_50ms_Group49_CRC";
BA_ "SysSignalName" SG_ 733 IPD_50ms_Group49_CRC "IPD_50ms_Group49_CRC";
BA_ "CompuMethodName" SG_ 733 IPD_50ms_Group49_RC "IPD_50ms_Group49_RC";
BA_ "ISignalName" SG_ 733 IPD_50ms_Group49_RC "IIPD_50ms_Group49_RC";
BA_ "SysSignalName" SG_ 733 IPD_50ms_Group49_RC "IPD_50ms_Group49_RC";
BA_ "CompuMethodName" SG_ 733 KeepPwrRsnIPD "KeepPwrRsnIPD";
BA_ "ISignalName" SG_ 733 KeepPwrRsnIPD "IKeepPwrRsnIPD";
BA_ "LongName" SG_ 733 KeepPwrRsnIPD "Keep Power Reason IPD";
BA_ "SysSignalName" SG_ 733 KeepPwrRsnIPD "KeepPwrRsnIPD";
BA_ "CompuMethodName" SG_ 733 IPD_50ms_Group49_Reserved1 "IPD_50ms_Group49_Reserved1";
BA_ "GenSigStartValue" SG_ 733 IPD_50ms_Group49_Reserved1 31;
BA_ "ISignalName" SG_ 733 IPD_50ms_Group49_Reserved1 "IIPD_50ms_Group49_Reserved1";
BA_ "SysSignalName" SG_ 733 IPD_50ms_Group49_Reserved1 "IPD_50ms_Group49_Reserved1";
BA_ "CompuMethodName" SG_ 733 SysPwrMdCtrl "SysPwrMdCtrl";
BA_ "ISignalName" SG_ 733 SysPwrMdCtrl "ISysPwrMdCtrl";
BA_ "LongName" SG_ 733 SysPwrMdCtrl "System power mode control";
BA_ "SysSignalName" SG_ 733 SysPwrMdCtrl "SysPwrMdCtrl";
BA_ "CompuMethodName" SG_ 733 APAEnRunReq "APAEnRunReq";
BA_ "ISignalName" SG_ 733 APAEnRunReq "IAPAEnRunReq";
BA_ "LongName" SG_ 733 APAEnRunReq "Advanced Park Assist Engine Run Request";
BA_ "SysSignalName" SG_ 733 APAEnRunReq "APAEnRunReq";
BA_ "CompuMethodName" SG_ 733 IPD_50ms_Group49_Reserved2 "IPD_50ms_Group49_Reserved2";
BA_ "GenSigStartValue" SG_ 733 IPD_50ms_Group49_Reserved2 127;
BA_ "ISignalName" SG_ 733 IPD_50ms_Group49_Reserved2 "IIPD_50ms_Group49_Reserved2";
BA_ "SysSignalName" SG_ 733 IPD_50ms_Group49_Reserved2 "IPD_50ms_Group49_Reserved2";
BA_ "CompuMethodName" SG_ 733 IPD_50ms_Group49_Reserved3 "IPD_50ms_Group49_Reserved3";
BA_ "GenSigStartValue" SG_ 733 IPD_50ms_Group49_Reserved3 255;
BA_ "ISignalName" SG_ 733 IPD_50ms_Group49_Reserved3 "IIPD_50ms_Group49_Reserved3";
BA_ "SysSignalName" SG_ 733 IPD_50ms_Group49_Reserved3 "IPD_50ms_Group49_Reserved3";
BA_ "CompuMethodName" SG_ 733 IPD_50ms_Group49_Reserved4 "IPD_50ms_Group49_Reserved4";
BA_ "GenSigStartValue" SG_ 733 IPD_50ms_Group49_Reserved4 15;
BA_ "ISignalName" SG_ 733 IPD_50ms_Group49_Reserved4 "IIPD_50ms_Group49_Reserved4";
BA_ "SysSignalName" SG_ 733 IPD_50ms_Group49_Reserved4 "IPD_50ms_Group49_Reserved4";
BA_ "CompuMethodName" SG_ 733 LADSAFnInd "LADSAFnInd";
BA_ "ISignalName" SG_ 733 LADSAFnInd "ILADSAFnInd";
BA_ "LongName" SG_ 733 LADSAFnInd "Advanced Park Assist Active Function Indication";
BA_ "SysSignalName" SG_ 733 LADSAFnInd "LADSAFnInd";
BA_ "CompuMethodName" SG_ 733 IPD_50ms_Group49_Reserved5 "IPD_50ms_Group49_Reserved5";
BA_ "GenSigStartValue" SG_ 733 IPD_50ms_Group49_Reserved5 255;
BA_ "ISignalName" SG_ 733 IPD_50ms_Group49_Reserved5 "IIPD_50ms_Group49_Reserved5";
BA_ "SysSignalName" SG_ 733 IPD_50ms_Group49_Reserved5 "IPD_50ms_Group49_Reserved5";
BA_ "CompuMethodName" SG_ 733 IPD_50ms_Group49_Reserved6 "IPD_50ms_Group49_Reserved6";
BA_ "GenSigStartValue" SG_ 733 IPD_50ms_Group49_Reserved6 255;
BA_ "ISignalName" SG_ 733 IPD_50ms_Group49_Reserved6 "IIPD_50ms_Group49_Reserved6";
BA_ "SysSignalName" SG_ 733 IPD_50ms_Group49_Reserved6 "IPD_50ms_Group49_Reserved6";
BA_ "CompuMethodName" SG_ 982 ACCDetObjLongtRltvDist "ACCDetObjLongtRltvDist";
BA_ "ISignalName" SG_ 982 ACCDetObjLongtRltvDist "IACCDetObjLongtRltvDist";
BA_ "LongName" SG_ 982 ACCDetObjLongtRltvDist "Adaptive_Cruise_Control_Detected_Object_Longitudinal_Relative_Distance";
BA_ "SysSignalName" SG_ 982 ACCDetObjLongtRltvDist "ACCDetObjLongtRltvDist";
BA_ "CompuMethodName" SG_ 982 ACCDetObjSyncCtr "ACCDetObjSyncCtr";
BA_ "ISignalName" SG_ 982 ACCDetObjSyncCtr "IACCDetObjSyncCtr";
BA_ "LongName" SG_ 982 ACCDetObjSyncCtr "Adaptive_Cruise_Control_Detected_Object_Synchronize_Counter";
BA_ "SysSignalName" SG_ 982 ACCDetObjSyncCtr "ACCDetObjSyncCtr";
BA_ "CompuMethodName" SG_ 982 ACCDetObjLongtRltvSpd "ACCDetObjLongtRltvSpd";
BA_ "ISignalName" SG_ 982 ACCDetObjLongtRltvSpd "IACCDetObjLongtRltvSpd";
BA_ "LongName" SG_ 982 ACCDetObjLongtRltvSpd "Adaptive_Cruise_Control_Detected_Object_Longitudinal_Relative_Speed";
BA_ "SysSignalName" SG_ 982 ACCDetObjLongtRltvSpd "ACCDetObjLongtRltvSpd";
BA_ "CompuMethodName" SG_ 982 ACCDetObjRisk "ACCDetObjRisk";
BA_ "ISignalName" SG_ 982 ACCDetObjRisk "IACCDetObjRisk";
BA_ "LongName" SG_ 982 ACCDetObjRisk "Adaptive_Cruise_Control_Detected_Object_0_Risk";
BA_ "SysSignalName" SG_ 982 ACCDetObjRisk "ACCDetObjRisk";
BA_ "CompuMethodName" SG_ 982 ACCDetObjTyp "ACCDetObjTyp";
BA_ "ISignalName" SG_ 982 ACCDetObjTyp "IACCDetObjTyp";
BA_ "LongName" SG_ 982 ACCDetObjTyp "Adaptive_Cruise_Control_Detected_Object_0_Type";
BA_ "SysSignalName" SG_ 982 ACCDetObjTyp "ACCDetObjTyp";
BA_ "CompuMethodName" SG_ 982 ACCDetObjLatRltvDist "ACCDetObjLatRltvDist";
BA_ "ISignalName" SG_ 982 ACCDetObjLatRltvDist "IACCDetObjLatRltvDist";
BA_ "LongName" SG_ 982 ACCDetObjLatRltvDist "Adaptive_Cruise_Control_Detected_Object_Lateral_Relative_Distance";
BA_ "SysSignalName" SG_ 982 ACCDetObjLatRltvDist "ACCDetObjLatRltvDist";
BA_ "CompuMethodName" SG_ 982 ACCDetObjExistPrblty "ACCDetObjExistPrblty";
BA_ "ISignalName" SG_ 982 ACCDetObjExistPrblty "IACCDetObjExistPrblty";
BA_ "LongName" SG_ 982 ACCDetObjExistPrblty "Adaptive_Cruise_Control_Detected_Object_Exist_Probability";
BA_ "SysSignalName" SG_ 982 ACCDetObjExistPrblty "ACCDetObjExistPrblty";
BA_ "CompuMethodName" SG_ 982 ACCDetObjId "ACCDetObjId";
BA_ "ISignalName" SG_ 982 ACCDetObjId "IACCDetObjId";
BA_ "LongName" SG_ 982 ACCDetObjId "Adaptive_Cruise_Control_Detected_Object_Identifier";
BA_ "SysSignalName" SG_ 982 ACCDetObjId "ACCDetObjId";
BA_ "CompuMethodName" SG_ 478 IPD_20ms_Group64_CRC "IPD_20ms_Group64_CRC";
BA_ "ISignalName" SG_ 478 IPD_20ms_Group64_CRC "IIPD_20ms_Group64_CRC";
BA_ "LongName" SG_ 478 IPD_20ms_Group64_CRC "IPD_20ms_Group64 Checksum";
BA_ "SysSignalName" SG_ 478 IPD_20ms_Group64_CRC "IPD_20ms_Group64_CRC";
BA_ "CompuMethodName" SG_ 478 IPD_20ms_Group64_RC "IPD_20ms_Group64_RC";
BA_ "ISignalName" SG_ 478 IPD_20ms_Group64_RC "IIPD_20ms_Group64_RC";
BA_ "LongName" SG_ 478 IPD_20ms_Group64_RC "IPD_20ms_Group64 Alive Rolling Counter";
BA_ "SysSignalName" SG_ 478 IPD_20ms_Group64_RC "IPD_20ms_Group64_RC";
BA_ "CompuMethodName" SG_ 478 APASCSDrvrReqSts "APASCSDrvrReqSts";
BA_ "ISignalName" SG_ 478 APASCSDrvrReqSts "IAPASCSDrvrReqSts";
BA_ "SysSignalName" SG_ 478 APASCSDrvrReqSts "APASCSDrvrReqSts";
BA_ "CompuMethodName" SG_ 478 APASCSBrkFn "APASCSBrkFn";
BA_ "ISignalName" SG_ 478 APASCSBrkFn "IAPASCSBrkFn";
BA_ "SysSignalName" SG_ 478 APASCSBrkFn "APASCSBrkFn";
BA_ "CompuMethodName" SG_ 478 APASCSParkngVelMax "APASCSParkngVelMax";
BA_ "ISignalName" SG_ 478 APASCSParkngVelMax "IAPASCSParkngVelMax";
BA_ "SysSignalName" SG_ 478 APASCSParkngVelMax "APASCSParkngVelMax";
BA_ "CompuMethodName" SG_ 478 APASCSParkngTrgtDist "APASCSParkngTrgtDist";
BA_ "ISignalName" SG_ 478 APASCSParkngTrgtDist "IAPASCSParkngTrgtDist";
BA_ "SysSignalName" SG_ 478 APASCSParkngTrgtDist "APASCSParkngTrgtDist";
BA_ "CompuMethodName" SG_ 478 APAEnToqReqVal "APAEnToqReqVal";
BA_ "ISignalName" SG_ 478 APAEnToqReqVal "IAPAEnToqReqVal";
BA_ "SysSignalName" SG_ 478 APAEnToqReqVal "APAEnToqReqVal";
BA_ "CompuMethodName" SG_ 478 IPD_20ms_Group64_Reserved1 "IPD_20ms_Group64_Reserved1";
BA_ "GenSigStartValue" SG_ 478 IPD_20ms_Group64_Reserved1 1;
BA_ "ISignalName" SG_ 478 IPD_20ms_Group64_Reserved1 "IIPD_20ms_Group64_Reserved1";
BA_ "SysSignalName" SG_ 478 IPD_20ms_Group64_Reserved1 "IPD_20ms_Group64_Reserved1";
BA_ "CompuMethodName" SG_ 478 APAEnToqReqSts "APAEnToqReqSts";
BA_ "ISignalName" SG_ 478 APAEnToqReqSts "IAPAEnToqReqSts";
BA_ "SysSignalName" SG_ 478 APAEnToqReqSts "APAEnToqReqSts";
BA_ "CompuMethodName" SG_ 478 APASCSParkngPrflReq "APASCSParkngPrflReq";
BA_ "ISignalName" SG_ 478 APASCSParkngPrflReq "IAPASCSParkngPrflReq";
BA_ "SysSignalName" SG_ 478 APASCSParkngPrflReq "APASCSParkngPrflReq";
BA_ "CompuMethodName" SG_ 478 APASCSReqSts "APASCSReqSts";
BA_ "ISignalName" SG_ 478 APASCSReqSts "IAPASCSReqSts";
BA_ "SysSignalName" SG_ 478 APASCSReqSts "APASCSReqSts";
BA_ "CompuMethodName" SG_ 478 APASCSBrkFnMd "APASCSBrkFnMd";
BA_ "ISignalName" SG_ 478 APASCSBrkFnMd "IAPASCSBrkFnMd";
BA_ "SysSignalName" SG_ 478 APASCSBrkFnMd "APASCSBrkFnMd";
BA_ "CompuMethodName" SG_ 478 IPD_20ms_Group64_Reserved2 "IPD_20ms_Group64_Reserved2";
BA_ "GenSigStartValue" SG_ 478 IPD_20ms_Group64_Reserved2 255;
BA_ "ISignalName" SG_ 478 IPD_20ms_Group64_Reserved2 "IIPD_20ms_Group64_Reserved2";
BA_ "SysSignalName" SG_ 478 IPD_20ms_Group64_Reserved2 "IPD_20ms_Group64_Reserved2";
BA_ "CompuMethodName" SG_ 478 IPD_20ms_Group64_Reserved3 "IPD_20ms_Group64_Reserved3";
BA_ "GenSigStartValue" SG_ 478 IPD_20ms_Group64_Reserved3 255;
BA_ "ISignalName" SG_ 478 IPD_20ms_Group64_Reserved3 "IIPD_20ms_Group64_Reserved3";
BA_ "SysSignalName" SG_ 478 IPD_20ms_Group64_Reserved3 "IPD_20ms_Group64_Reserved3";
BA_ "CompuMethodName" SG_ 478 IPD_20ms_Group64_Reserved4 "IPD_20ms_Group64_Reserved4";
BA_ "GenSigStartValue" SG_ 478 IPD_20ms_Group64_Reserved4 255;
BA_ "ISignalName" SG_ 478 IPD_20ms_Group64_Reserved4 "IIPD_20ms_Group64_Reserved4";
BA_ "SysSignalName" SG_ 478 IPD_20ms_Group64_Reserved4 "IPD_20ms_Group64_Reserved4";
BA_ "CompuMethodName" SG_ 478 IPD_20ms_Group64_Reserved5 "IPD_20ms_Group64_Reserved5";
BA_ "GenSigStartValue" SG_ 478 IPD_20ms_Group64_Reserved5 255;
BA_ "ISignalName" SG_ 478 IPD_20ms_Group64_Reserved5 "IIPD_20ms_Group64_Reserved5";
BA_ "SysSignalName" SG_ 478 IPD_20ms_Group64_Reserved5 "IPD_20ms_Group64_Reserved5";
BA_ "CompuMethodName" SG_ 478 IPD_20ms_Group64_Reserved6 "IPD_20ms_Group64_Reserved6";
BA_ "GenSigStartValue" SG_ 478 IPD_20ms_Group64_Reserved6 255;
BA_ "ISignalName" SG_ 478 IPD_20ms_Group64_Reserved6 "IIPD_20ms_Group64_Reserved6";
BA_ "SysSignalName" SG_ 478 IPD_20ms_Group64_Reserved6 "IPD_20ms_Group64_Reserved6";
BA_ "CompuMethodName" SG_ 478 IPD_20ms_Group64_Reserved7 "IPD_20ms_Group64_Reserved7";
BA_ "GenSigStartValue" SG_ 478 IPD_20ms_Group64_Reserved7 255;
BA_ "ISignalName" SG_ 478 IPD_20ms_Group64_Reserved7 "IIPD_20ms_Group64_Reserved7";
BA_ "SysSignalName" SG_ 478 IPD_20ms_Group64_Reserved7 "IPD_20ms_Group64_Reserved7";
BA_ "CompuMethodName" SG_ 478 IPD_20ms_Group64_Reserved8 "IPD_20ms_Group64_Reserved8";
BA_ "GenSigStartValue" SG_ 478 IPD_20ms_Group64_Reserved8 255;
BA_ "ISignalName" SG_ 478 IPD_20ms_Group64_Reserved8 "IIPD_20ms_Group64_Reserved8";
BA_ "SysSignalName" SG_ 478 IPD_20ms_Group64_Reserved8 "IPD_20ms_Group64_Reserved8";
BA_ "CompuMethodName" SG_ 478 IPD_20ms_Group64_Reserved9 "IPD_20ms_Group64_Reserved9";
BA_ "GenSigStartValue" SG_ 478 IPD_20ms_Group64_Reserved9 255;
BA_ "ISignalName" SG_ 478 IPD_20ms_Group64_Reserved9 "IIPD_20ms_Group64_Reserved9";
BA_ "SysSignalName" SG_ 478 IPD_20ms_Group64_Reserved9 "IPD_20ms_Group64_Reserved9";
BA_ "CompuMethodName" SG_ 478 IPD_20ms_Group64_Reserved10 "IPD_20ms_Group64_Reserved10";
BA_ "GenSigStartValue" SG_ 478 IPD_20ms_Group64_Reserved10 255;
BA_ "ISignalName" SG_ 478 IPD_20ms_Group64_Reserved10 "IIPD_20ms_Group64_Reserved10";
BA_ "SysSignalName" SG_ 478 IPD_20ms_Group64_Reserved10 "IPD_20ms_Group64_Reserved10";
BA_ "CompuMethodName" SG_ 176 IPD_20ms_Group67_CRC "IPD_20ms_Group67_CRC";
BA_ "ISignalName" SG_ 176 IPD_20ms_Group67_CRC "IIPD_20ms_Group67_CRC";
BA_ "SysSignalName" SG_ 176 IPD_20ms_Group67_CRC "IPD_20ms_Group67_CRC";
BA_ "CompuMethodName" SG_ 176 IPD_20ms_Group67_RC "IPD_20ms_Group67_RC";
BA_ "ISignalName" SG_ 176 IPD_20ms_Group67_RC "IIPD_20ms_Group67_RC";
BA_ "SysSignalName" SG_ 176 IPD_20ms_Group67_RC "IPD_20ms_Group67_RC";
BA_ "CompuMethodName" SG_ 176 IPD_20ms_Group67_Reserved15 "IPD_20ms_Group67_Reserved15";
BA_ "GenSigStartValue" SG_ 176 IPD_20ms_Group67_Reserved15 15;
BA_ "ISignalName" SG_ 176 IPD_20ms_Group67_Reserved15 "IIPD_20ms_Group67_Reserved15";
BA_ "SysSignalName" SG_ 176 IPD_20ms_Group67_Reserved15 "IPD_20ms_Group67_Reserved15";
BA_ "CompuMethodName" SG_ 176 IPD_20ms_Group67_Reserved23 "IPD_20ms_Group67_Reserved23";
BA_ "GenSigStartValue" SG_ 176 IPD_20ms_Group67_Reserved23 255;
BA_ "ISignalName" SG_ 176 IPD_20ms_Group67_Reserved23 "IIPD_20ms_Group67_Reserved23";
BA_ "SysSignalName" SG_ 176 IPD_20ms_Group67_Reserved23 "IPD_20ms_Group67_Reserved23";
BA_ "CompuMethodName" SG_ 176 IPD_20ms_Group67_Reserved31 "IPD_20ms_Group67_Reserved31";
BA_ "GenSigStartValue" SG_ 176 IPD_20ms_Group67_Reserved31 255;
BA_ "ISignalName" SG_ 176 IPD_20ms_Group67_Reserved31 "IIPD_20ms_Group67_Reserved31";
BA_ "SysSignalName" SG_ 176 IPD_20ms_Group67_Reserved31 "IPD_20ms_Group67_Reserved31";
BA_ "CompuMethodName" SG_ 176 IPD_20ms_Group67_Reserved39 "IPD_20ms_Group67_Reserved39";
BA_ "GenSigStartValue" SG_ 176 IPD_20ms_Group67_Reserved39 255;
BA_ "ISignalName" SG_ 176 IPD_20ms_Group67_Reserved39 "IIPD_20ms_Group67_Reserved39";
BA_ "SysSignalName" SG_ 176 IPD_20ms_Group67_Reserved39 "IPD_20ms_Group67_Reserved39";
BA_ "CompuMethodName" SG_ 176 IPD_20ms_Group67_Reserved47 "IPD_20ms_Group67_Reserved47";
BA_ "GenSigStartValue" SG_ 176 IPD_20ms_Group67_Reserved47 255;
BA_ "ISignalName" SG_ 176 IPD_20ms_Group67_Reserved47 "IIPD_20ms_Group67_Reserved47";
BA_ "SysSignalName" SG_ 176 IPD_20ms_Group67_Reserved47 "IPD_20ms_Group67_Reserved47";
BA_ "CompuMethodName" SG_ 176 IPD_20ms_Group67_Reserved55 "IPD_20ms_Group67_Reserved55";
BA_ "GenSigStartValue" SG_ 176 IPD_20ms_Group67_Reserved55 255;
BA_ "ISignalName" SG_ 176 IPD_20ms_Group67_Reserved55 "IIPD_20ms_Group67_Reserved55";
BA_ "SysSignalName" SG_ 176 IPD_20ms_Group67_Reserved55 "IPD_20ms_Group67_Reserved55";
BA_ "CompuMethodName" SG_ 176 IPD_20ms_Group67_Reserved63 "IPD_20ms_Group67_Reserved63";
BA_ "GenSigStartValue" SG_ 176 IPD_20ms_Group67_Reserved63 255;
BA_ "ISignalName" SG_ 176 IPD_20ms_Group67_Reserved63 "IIPD_20ms_Group67_Reserved63";
BA_ "SysSignalName" SG_ 176 IPD_20ms_Group67_Reserved63 "IPD_20ms_Group67_Reserved63";
BA_ "CompuMethodName" SG_ 176 IPD_20ms_Group67_Reserved71 "IPD_20ms_Group67_Reserved71";
BA_ "GenSigStartValue" SG_ 176 IPD_20ms_Group67_Reserved71 255;
BA_ "ISignalName" SG_ 176 IPD_20ms_Group67_Reserved71 "IIPD_20ms_Group67_Reserved71";
BA_ "SysSignalName" SG_ 176 IPD_20ms_Group67_Reserved71 "IPD_20ms_Group67_Reserved71";
BA_ "CompuMethodName" SG_ 176 ADS_SpdAstSysTrgtSpd "ADS_SpdAstSysTrgtSpd";
BA_ "ISignalName" SG_ 176 ADS_SpdAstSysTrgtSpd "IADS_SpdAstSysTrgtSpd";
BA_ "LongName" SG_ 176 ADS_SpdAstSysTrgtSpd "ADAS_Speed_Assist_System_Target_Speed";
BA_ "SysSignalName" SG_ 176 ADS_SpdAstSysTrgtSpd "ADS_SpdAstSysTrgtSpd";
BA_ "CompuMethodName" SG_ 176 ADS_SpdAstSysTrgtSpdV "ADS_SpdAstSysTrgtSpdV";
BA_ "ISignalName" SG_ 176 ADS_SpdAstSysTrgtSpdV "IADS_SpdAstSysTrgtSpdV";
BA_ "LongName" SG_ 176 ADS_SpdAstSysTrgtSpdV "ADAS_Speed_Assist_System_Target_Speed Valid";
BA_ "SysSignalName" SG_ 176 ADS_SpdAstSysTrgtSpdV "ADS_SpdAstSysTrgtSpdV";
BA_ "CompuMethodName" SG_ 176 IPD_20ms_Group67_Reserved95 "IPD_20ms_Group67_Reserved95";
BA_ "GenSigStartValue" SG_ 176 IPD_20ms_Group67_Reserved95 255;
BA_ "ISignalName" SG_ 176 IPD_20ms_Group67_Reserved95 "IIPD_20ms_Group67_Reserved95";
BA_ "SysSignalName" SG_ 176 IPD_20ms_Group67_Reserved95 "IPD_20ms_Group67_Reserved95";
BA_ "CompuMethodName" SG_ 176 IPD_20ms_Group67_Reserved103 "IPD_20ms_Group67_Reserved103";
BA_ "GenSigStartValue" SG_ 176 IPD_20ms_Group67_Reserved103 255;
BA_ "ISignalName" SG_ 176 IPD_20ms_Group67_Reserved103 "IIPD_20ms_Group67_Reserved103";
BA_ "SysSignalName" SG_ 176 IPD_20ms_Group67_Reserved103 "IPD_20ms_Group67_Reserved103";
BA_ "CompuMethodName" SG_ 176 IPD_20ms_Group67_Reserved111 "IPD_20ms_Group67_Reserved111";
BA_ "GenSigStartValue" SG_ 176 IPD_20ms_Group67_Reserved111 255;
BA_ "ISignalName" SG_ 176 IPD_20ms_Group67_Reserved111 "IIPD_20ms_Group67_Reserved111";
BA_ "SysSignalName" SG_ 176 IPD_20ms_Group67_Reserved111 "IPD_20ms_Group67_Reserved111";
BA_ "CompuMethodName" SG_ 176 IPD_20ms_Group67_Reserved119 "IPD_20ms_Group67_Reserved119";
BA_ "GenSigStartValue" SG_ 176 IPD_20ms_Group67_Reserved119 255;
BA_ "ISignalName" SG_ 176 IPD_20ms_Group67_Reserved119 "IIPD_20ms_Group67_Reserved119";
BA_ "SysSignalName" SG_ 176 IPD_20ms_Group67_Reserved119 "IPD_20ms_Group67_Reserved119";
BA_ "CompuMethodName" SG_ 176 IPD_20ms_Group67_Reserved127 "IPD_20ms_Group67_Reserved127";
BA_ "GenSigStartValue" SG_ 176 IPD_20ms_Group67_Reserved127 255;
BA_ "ISignalName" SG_ 176 IPD_20ms_Group67_Reserved127 "IIPD_20ms_Group67_Reserved127";
BA_ "SysSignalName" SG_ 176 IPD_20ms_Group67_Reserved127 "IPD_20ms_Group67_Reserved127";
BA_ "CompuMethodName" SG_ 1202 IPD_NM_BSMtoRMS_PTCANFD "IPD_NM_BSMtoRMS_PTCANFD";
BA_ "ISignalName" SG_ 1202 IPD_NM_BSMtoRMS_PTCANFD "IIPD_NM_BSMtoRMS_PTCANFD";
BA_ "LongName" SG_ 1202 IPD_NM_BSMtoRMS_PTCANFD "IPD_NM_BSMtoRMS_PTCANFD";
BA_ "SysSignalName" SG_ 1202 IPD_NM_BSMtoRMS_PTCANFD "IPD_NM_BSMtoRMS_PTCANFD";
BA_ "CompuMethodName" SG_ 1202 IPD_NM_PBSMtoRMS_PTCANFD "IPD_NM_PBSMtoRMS_PTCANFD";
BA_ "ISignalName" SG_ 1202 IPD_NM_PBSMtoRMS_PTCANFD "IIPD_NM_PBSMtoRMS_PTCANFD";
BA_ "LongName" SG_ 1202 IPD_NM_PBSMtoRMS_PTCANFD "IPD_NM_PBSMtoRMS_PTCANFD";
BA_ "SysSignalName" SG_ 1202 IPD_NM_PBSMtoRMS_PTCANFD "IPD_NM_PBSMtoRMS_PTCANFD";
BA_ "CompuMethodName" SG_ 1202 IPD_NM_RMStoNOS_PTCANFD "IPD_NM_RMStoNOS_PTCANFD";
BA_ "ISignalName" SG_ 1202 IPD_NM_RMStoNOS_PTCANFD "IIPD_NM_RMStoNOS_PTCANFD";
BA_ "LongName" SG_ 1202 IPD_NM_RMStoNOS_PTCANFD "IPD_NM_RMStoNOS_PTCANFD";
BA_ "SysSignalName" SG_ 1202 IPD_NM_RMStoNOS_PTCANFD "IPD_NM_RMStoNOS_PTCANFD";
BA_ "CompuMethodName" SG_ 1202 IPD_NM_RSStoNOS_PTCANFD "IPD_NM_RSStoNOS_PTCANFD";
BA_ "ISignalName" SG_ 1202 IPD_NM_RSStoNOS_PTCANFD "IIPD_NM_RSStoNOS_PTCANFD";
BA_ "LongName" SG_ 1202 IPD_NM_RSStoNOS_PTCANFD "IPD_NM_RSStoNOS_PTCANFD";
BA_ "SysSignalName" SG_ 1202 IPD_NM_RSStoNOS_PTCANFD "IPD_NM_RSStoNOS_PTCANFD";
BA_ "CompuMethodName" SG_ 1202 IPD_NM_RSStoRMS_PTCANFD "IPD_NM_RSStoRMS_PTCANFD";
BA_ "ISignalName" SG_ 1202 IPD_NM_RSStoRMS_PTCANFD "IIPD_NM_RSStoRMS_PTCANFD";
BA_ "LongName" SG_ 1202 IPD_NM_RSStoRMS_PTCANFD "IPD_NM_RSStoRMS_PTCANFD";
BA_ "SysSignalName" SG_ 1202 IPD_NM_RSStoRMS_PTCANFD "IPD_NM_RSStoRMS_PTCANFD";
BA_ "CompuMethodName" SG_ 1202 IPD_NM_NOStoRMS_PTCANFD "IPD_NM_NOStoRMS_PTCANFD";
BA_ "ISignalName" SG_ 1202 IPD_NM_NOStoRMS_PTCANFD "IIPD_NM_NOStoRMS_PTCANFD";
BA_ "LongName" SG_ 1202 IPD_NM_NOStoRMS_PTCANFD "IPD_NM_NOStoRMS_PTCANFD";
BA_ "SysSignalName" SG_ 1202 IPD_NM_NOStoRMS_PTCANFD "IPD_NM_NOStoRMS_PTCANFD";
BA_ "CompuMethodName" SG_ 1202 IPD_NM_NOSSta_PTCANFD "IPD_NM_NOSSta_PTCANFD";
BA_ "ISignalName" SG_ 1202 IPD_NM_NOSSta_PTCANFD "IIPD_NM_NOSSta_PTCANFD";
BA_ "LongName" SG_ 1202 IPD_NM_NOSSta_PTCANFD "IPD_NM_NOSSta_PTCANFD";
BA_ "SysSignalName" SG_ 1202 IPD_NM_NOSSta_PTCANFD "IPD_NM_NOSSta_PTCANFD";
BA_ "CompuMethodName" SG_ 1202 IPD_NM_RMSSta_PTCANFD "IPD_NM_RMSSta_PTCANFD";
BA_ "ISignalName" SG_ 1202 IPD_NM_RMSSta_PTCANFD "IIPD_NM_RMSSta_PTCANFD";
BA_ "LongName" SG_ 1202 IPD_NM_RMSSta_PTCANFD "IPD_NM_RMSSta_PTCANFD";
BA_ "SysSignalName" SG_ 1202 IPD_NM_RMSSta_PTCANFD "IPD_NM_RMSSta_PTCANFD";
BA_ "CompuMethodName" SG_ 1202 IPD_NWI_PTCANFD "IPD_NWI_PTCANFD";
BA_ "ISignalName" SG_ 1202 IPD_NWI_PTCANFD "IIPD_NWI_PTCANFD";
BA_ "LongName" SG_ 1202 IPD_NWI_PTCANFD "IPD_PTCANFD Network Wakeup Indication";
BA_ "SysSignalName" SG_ 1202 IPD_NWI_PTCANFD "IPD_NWI_PTCANFD";
BA_ "CompuMethodName" SG_ 1202 IPD_NOI_PTCANFD "IPD_NOI_PTCANFD";
BA_ "ISignalName" SG_ 1202 IPD_NOI_PTCANFD "IIPD_NOI_PTCANFD";
BA_ "LongName" SG_ 1202 IPD_NOI_PTCANFD "IPD PTCANFD Network Operation Indication";
BA_ "SysSignalName" SG_ 1202 IPD_NOI_PTCANFD "IPD_NOI_PTCANFD";
BA_ "CompuMethodName" SG_ 1202 IPD_NKI_PTCANFD "IPD_NKI_PTCANFD";
BA_ "ISignalName" SG_ 1202 IPD_NKI_PTCANFD "IIPD_NKI_PTCANFD";
BA_ "LongName" SG_ 1202 IPD_NKI_PTCANFD "IPD PTCANFD Network Keep Indication";
BA_ "SysSignalName" SG_ 1202 IPD_NKI_PTCANFD "IPD_NKI_PTCANFD";
BA_ "CompuMethodName" SG_ 1168 LVBM_NM_BSMtoRMS_PTCANFD "LVBM_NM_BSMtoRMS_PTCANFD";
BA_ "ISignalName" SG_ 1168 LVBM_NM_BSMtoRMS_PTCANFD "ILVBM_NM_BSMtoRMS_PTCANFD";
BA_ "LongName" SG_ 1168 LVBM_NM_BSMtoRMS_PTCANFD "Low Voltage Battery Module PTEXTDCAN Network Management BSM to RMS";
BA_ "SysSignalName" SG_ 1168 LVBM_NM_BSMtoRMS_PTCANFD "LVBM_NM_BSMtoRMS_PTCANFD";
BA_ "CompuMethodName" SG_ 1168 LVBM_NM_PBSMtoRMS_PTCANFD "LVBM_NM_PBSMtoRMS_PTCANFD";
BA_ "ISignalName" SG_ 1168 LVBM_NM_PBSMtoRMS_PTCANFD "ILVBM_NM_PBSMtoRMS_PTCANFD";
BA_ "LongName" SG_ 1168 LVBM_NM_PBSMtoRMS_PTCANFD "Low Voltage Battery Module PTEXTDCAN Network Management PBSM To RMS";
BA_ "SysSignalName" SG_ 1168 LVBM_NM_PBSMtoRMS_PTCANFD "LVBM_NM_PBSMtoRMS_PTCANFD";
BA_ "CompuMethodName" SG_ 1168 LVBM_NM_RMStoNOS_PTCANFD "LVBM_NM_RMStoNOS_PTCANFD";
BA_ "ISignalName" SG_ 1168 LVBM_NM_RMStoNOS_PTCANFD "ILVBM_NM_RMStoNOS_PTCANFD";
BA_ "LongName" SG_ 1168 LVBM_NM_RMStoNOS_PTCANFD "Low Voltage Battery Module PTEXTDCAN Network Management RMS To NOS";
BA_ "SysSignalName" SG_ 1168 LVBM_NM_RMStoNOS_PTCANFD "LVBM_NM_RMStoNOS_PTCANFD";
BA_ "CompuMethodName" SG_ 1168 LVBM_NM_RSStoNOS_PTCANFD "LVBM_NM_RSStoNOS_PTCANFD";
BA_ "ISignalName" SG_ 1168 LVBM_NM_RSStoNOS_PTCANFD "ILVBM_NM_RSStoNOS_PTCANFD";
BA_ "LongName" SG_ 1168 LVBM_NM_RSStoNOS_PTCANFD "Low Voltage Battery Module PTEXTDCAN Network Management RSS To NOS";
BA_ "SysSignalName" SG_ 1168 LVBM_NM_RSStoNOS_PTCANFD "LVBM_NM_RSStoNOS_PTCANFD";
BA_ "CompuMethodName" SG_ 1168 LVBM_NM_RSStoRMS_PTCANFD "LVBM_NM_RSStoRMS_PTCANFD";
BA_ "ISignalName" SG_ 1168 LVBM_NM_RSStoRMS_PTCANFD "ILVBM_NM_RSStoRMS_PTCANFD";
BA_ "LongName" SG_ 1168 LVBM_NM_RSStoRMS_PTCANFD "Low Voltage Battery Module PTEXTDCAN Network Management RSS To RMS";
BA_ "SysSignalName" SG_ 1168 LVBM_NM_RSStoRMS_PTCANFD "LVBM_NM_RSStoRMS_PTCANFD";
BA_ "CompuMethodName" SG_ 1168 LVBM_NM_NOStoRMS_PTCANFD "LVBM_NM_NOStoRMS_PTCANFD";
BA_ "ISignalName" SG_ 1168 LVBM_NM_NOStoRMS_PTCANFD "ILVBM_NM_NOStoRMS_PTCANFD";
BA_ "LongName" SG_ 1168 LVBM_NM_NOStoRMS_PTCANFD "Low Voltage Battery Module PTEXTDCAN Network Management NOS to RMS";
BA_ "SysSignalName" SG_ 1168 LVBM_NM_NOStoRMS_PTCANFD "LVBM_NM_NOStoRMS_PTCANFD";
BA_ "CompuMethodName" SG_ 1168 LVBM_NM_NOSSta_PTCANFD "LVBM_NM_NOSSta_PTCANFD";
BA_ "ISignalName" SG_ 1168 LVBM_NM_NOSSta_PTCANFD "ILVBM_NM_NOSSta_PTCANFD";
BA_ "LongName" SG_ 1168 LVBM_NM_NOSSta_PTCANFD "Low Voltage Battery Module PTEXTDCAN Network Management Normal Operation state";
BA_ "SysSignalName" SG_ 1168 LVBM_NM_NOSSta_PTCANFD "LVBM_NM_NOSSta_PTCANFD";
BA_ "CompuMethodName" SG_ 1168 LVBM_NM_RMSSta_PTCANFD "LVBM_NM_RMSSta_PTCANFD";
BA_ "ISignalName" SG_ 1168 LVBM_NM_RMSSta_PTCANFD "ILVBM_NM_RMSSta_PTCANFD";
BA_ "LongName" SG_ 1168 LVBM_NM_RMSSta_PTCANFD "Low Voltage Battery Module PTEXTDCAN Network Management Repeat Message State";
BA_ "SysSignalName" SG_ 1168 LVBM_NM_RMSSta_PTCANFD "LVBM_NM_RMSSta_PTCANFD";
BA_ "CompuMethodName" SG_ 1168 LVBM_NWI_PTCANFD "LVBM_NWI_PTCANFD";
BA_ "ISignalName" SG_ 1168 LVBM_NWI_PTCANFD "ILVBM_NWI_PTCANFD";
BA_ "LongName" SG_ 1168 LVBM_NWI_PTCANFD "Low Voltage Battery Module Network Wakeup Indication";
BA_ "SysSignalName" SG_ 1168 LVBM_NWI_PTCANFD "LVBM_NWI_PTCANFD";
BA_ "CompuMethodName" SG_ 1168 LVBM_NOI_PTCANFD "LVBM_NOI_PTCANFD";
BA_ "ISignalName" SG_ 1168 LVBM_NOI_PTCANFD "ILVBM_NOI_PTCANFD";
BA_ "LongName" SG_ 1168 LVBM_NOI_PTCANFD "Low Voltage Battery Module Network Operation Indication";
BA_ "SysSignalName" SG_ 1168 LVBM_NOI_PTCANFD "LVBM_NOI_PTCANFD";
BA_ "CompuMethodName" SG_ 1168 LVBM_NKI_PTCANFD "LVBM_NKI_PTCANFD";
BA_ "ISignalName" SG_ 1168 LVBM_NKI_PTCANFD "ILVBM_NKI_PTCANFD";
BA_ "LongName" SG_ 1168 LVBM_NKI_PTCANFD "Intelligent Computation Center Network Keep Indication";
BA_ "SysSignalName" SG_ 1168 LVBM_NKI_PTCANFD "LVBM_NKI_PTCANFD";
BA_ "CompuMethodName" SG_ 1266 MMCU_NM_BSMtoRMS_PTCANFD "MMCU_NM_BSMtoRMS_PTCANFD";
BA_ "ISignalName" SG_ 1266 MMCU_NM_BSMtoRMS_PTCANFD "IMMCU_NM_BSMtoRMS_PTCANFD";
BA_ "SysSignalName" SG_ 1266 MMCU_NM_BSMtoRMS_PTCANFD "MMCU_NM_BSMtoRMS_PTCANFD";
BA_ "CompuMethodName" SG_ 1266 MMCU_NM_PBSMtoRMS_PTCANFD "MMCU_NM_PBSMtoRMS_PTCANFD";
BA_ "ISignalName" SG_ 1266 MMCU_NM_PBSMtoRMS_PTCANFD "IMMCU_NM_PBSMtoRMS_PTCANFD";
BA_ "SysSignalName" SG_ 1266 MMCU_NM_PBSMtoRMS_PTCANFD "MMCU_NM_PBSMtoRMS_PTCANFD";
BA_ "CompuMethodName" SG_ 1266 MMCU_NM_RMStoNOS_PTCANFD "MMCU_NM_RMStoNOS_PTCANFD";
BA_ "ISignalName" SG_ 1266 MMCU_NM_RMStoNOS_PTCANFD "IMMCU_NM_RMStoNOS_PTCANFD";
BA_ "SysSignalName" SG_ 1266 MMCU_NM_RMStoNOS_PTCANFD "MMCU_NM_RMStoNOS_PTCANFD";
BA_ "CompuMethodName" SG_ 1266 MMCU_NM_RSStoNOS_PTCANFD "MMCU_NM_RSStoNOS_PTCANFD";
BA_ "ISignalName" SG_ 1266 MMCU_NM_RSStoNOS_PTCANFD "IMMCU_NM_RSStoNOS_PTCANFD";
BA_ "SysSignalName" SG_ 1266 MMCU_NM_RSStoNOS_PTCANFD "MMCU_NM_RSStoNOS_PTCANFD";
BA_ "CompuMethodName" SG_ 1266 MMCU_NM_RSStoRMS_PTCANFD "MMCU_NM_RSStoRMS_PTCANFD";
BA_ "ISignalName" SG_ 1266 MMCU_NM_RSStoRMS_PTCANFD "IMMCU_NM_RSStoRMS_PTCANFD";
BA_ "SysSignalName" SG_ 1266 MMCU_NM_RSStoRMS_PTCANFD "MMCU_NM_RSStoRMS_PTCANFD";
BA_ "CompuMethodName" SG_ 1266 MMCU_NM_NOStoRMS_PTCANFD "MMCU_NM_NOStoRMS_PTCANFD";
BA_ "ISignalName" SG_ 1266 MMCU_NM_NOStoRMS_PTCANFD "IMMCU_NM_NOStoRMS_PTCANFD";
BA_ "SysSignalName" SG_ 1266 MMCU_NM_NOStoRMS_PTCANFD "MMCU_NM_NOStoRMS_PTCANFD";
BA_ "CompuMethodName" SG_ 1266 MMCU_NM_NOSSta_PTCANFD "MMCU_NM_NOSSta_PTCANFD";
BA_ "ISignalName" SG_ 1266 MMCU_NM_NOSSta_PTCANFD "IMMCU_NM_NOSSta_PTCANFD";
BA_ "SysSignalName" SG_ 1266 MMCU_NM_NOSSta_PTCANFD "MMCU_NM_NOSSta_PTCANFD";
BA_ "CompuMethodName" SG_ 1266 MMCU_NM_RMSSta_PTCANFD "MMCU_NM_RMSSta_PTCANFD";
BA_ "ISignalName" SG_ 1266 MMCU_NM_RMSSta_PTCANFD "IMMCU_NM_RMSSta_PTCANFD";
BA_ "SysSignalName" SG_ 1266 MMCU_NM_RMSSta_PTCANFD "MMCU_NM_RMSSta_PTCANFD";
BA_ "CompuMethodName" SG_ 1266 MMCU_NWI_PTCANFD "MMCU_NWI_PTCANFD";
BA_ "ISignalName" SG_ 1266 MMCU_NWI_PTCANFD "IMMCU_NWI_PTCANFD";
BA_ "SysSignalName" SG_ 1266 MMCU_NWI_PTCANFD "MMCU_NWI_PTCANFD";
BA_ "CompuMethodName" SG_ 1266 MMCU_NOI_PTCANFD "MMCU_NOI_PTCANFD";
BA_ "ISignalName" SG_ 1266 MMCU_NOI_PTCANFD "IMMCU_NOI_PTCANFD";
BA_ "SysSignalName" SG_ 1266 MMCU_NOI_PTCANFD "MMCU_NOI_PTCANFD";
BA_ "CompuMethodName" SG_ 1266 MMCU_NKI_PTCANFD "MMCU_NKI_PTCANFD";
BA_ "ISignalName" SG_ 1266 MMCU_NKI_PTCANFD "IMMCU_NKI_PTCANFD";
BA_ "LongName" SG_ 1266 MMCU_NKI_PTCANFD "MMCU PTCANFD Network Keep Indication";
BA_ "SysSignalName" SG_ 1266 MMCU_NKI_PTCANFD "MMCU_NKI_PTCANFD";
BA_ "CompuMethodName" SG_ 153 PEU_10ms_Group25_CRC "PEU_10ms_Group25_CRC";
BA_ "ISignalName" SG_ 153 PEU_10ms_Group25_CRC "IPEU_10ms_Group25_CRC";
BA_ "LongName" SG_ 153 PEU_10ms_Group25_CRC "PEU_10ms_Group25_CRC";
BA_ "SysSignalName" SG_ 153 PEU_10ms_Group25_CRC "PEU_10ms_Group25_CRC";
BA_ "CompuMethodName" SG_ 153 PEU_10ms_Group25_RC "PEU_10ms_Group25_RC";
BA_ "ISignalName" SG_ 153 PEU_10ms_Group25_RC "IPEU_10ms_Group25_RC";
BA_ "LongName" SG_ 153 PEU_10ms_Group25_RC "PEU_10ms_Group25_RC";
BA_ "SysSignalName" SG_ 153 PEU_10ms_Group25_RC "PEU_10ms_Group25_RC";
BA_ "CompuMethodName" SG_ 153 PEUMotBSpdSts "PEUMotBSpdSts";
BA_ "ISignalName" SG_ 153 PEUMotBSpdSts "IPEUMotBSpdSts";
BA_ "LongName" SG_ 153 PEUMotBSpdSts "Power Electric Unit Motor BSpeed Status";
BA_ "SysSignalName" SG_ 153 PEUMotBSpdSts "PEUMotBSpdSts";
BA_ "CompuMethodName" SG_ 153 PEUMotASpdSts "PEUMotASpdSts";
BA_ "ISignalName" SG_ 153 PEUMotASpdSts "IPEUMotASpdSts";
BA_ "LongName" SG_ 153 PEUMotASpdSts "Power Electric Unit Motor ASpeed Status";
BA_ "SysSignalName" SG_ 153 PEUMotASpdSts "PEUMotASpdSts";
BA_ "CompuMethodName" SG_ 153 PEUMotADampTrqCmdd "PEUMotADampTrqCmdd";
BA_ "GenSigStartValue" SG_ 153 PEUMotADampTrqCmdd 32767;
BA_ "ISignalName" SG_ 153 PEUMotADampTrqCmdd "IPEUMotADampTrqCmdd";
BA_ "LongName" SG_ 153 PEUMotADampTrqCmdd "Power Electric Unit Motor ADamp Torque Commanded";
BA_ "SysSignalName" SG_ 153 PEUMotADampTrqCmdd "PEUMotADampTrqCmdd";
BA_ "CompuMethodName" SG_ 153 PEUMotASpd "PEUMotASpd";
BA_ "GenSigStartValue" SG_ 153 PEUMotASpd 32767;
BA_ "ISignalName" SG_ 153 PEUMotASpd "IPEUMotASpd";
BA_ "LongName" SG_ 153 PEUMotASpd "Power Electric Unit Motor A Speed";
BA_ "SysSignalName" SG_ 153 PEUMotASpd "PEUMotASpd";
BA_ "CompuMethodName" SG_ 153 PEUMotBDampTrqCmdd "PEUMotBDampTrqCmdd";
BA_ "GenSigStartValue" SG_ 153 PEUMotBDampTrqCmdd 32767;
BA_ "ISignalName" SG_ 153 PEUMotBDampTrqCmdd "IPEUMotBDampTrqCmdd";
BA_ "LongName" SG_ 153 PEUMotBDampTrqCmdd "Power Electric Unit Motor BDamp Torque Commanded";
BA_ "SysSignalName" SG_ 153 PEUMotBDampTrqCmdd "PEUMotBDampTrqCmdd";
BA_ "CompuMethodName" SG_ 153 PEUMotBSpd "PEUMotBSpd";
BA_ "GenSigStartValue" SG_ 153 PEUMotBSpd 32767;
BA_ "ISignalName" SG_ 153 PEUMotBSpd "IPEUMotBSpd";
BA_ "LongName" SG_ 153 PEUMotBSpd "Peu Motor BSpeed";
BA_ "SysSignalName" SG_ 153 PEUMotBSpd "PEUMotBSpd";
BA_ "CompuMethodName" SG_ 153 PEUMotAToqAch "PEUMotAToqAch";
BA_ "GenSigStartValue" SG_ 153 PEUMotAToqAch 2047;
BA_ "ISignalName" SG_ 153 PEUMotAToqAch "IPEUMotAToqAch";
BA_ "LongName" SG_ 153 PEUMotAToqAch "Peu Motor ATorque Achieved";
BA_ "SysSignalName" SG_ 153 PEUMotAToqAch "PEUMotAToqAch";
BA_ "CompuMethodName" SG_ 153 PEUMotBToqAch "PEUMotBToqAch";
BA_ "GenSigStartValue" SG_ 153 PEUMotBToqAch 1023;
BA_ "ISignalName" SG_ 153 PEUMotBToqAch "IPEUMotBToqAch";
BA_ "LongName" SG_ 153 PEUMotBToqAch "Peu Motor BTorque Achieved";
BA_ "SysSignalName" SG_ 153 PEUMotBToqAch "PEUMotBToqAch";
BA_ "CompuMethodName" SG_ 153 PEUMotASpdV "PEUMotASpdV";
BA_ "GenSigStartValue" SG_ 153 PEUMotASpdV 1;
BA_ "ISignalName" SG_ 153 PEUMotASpdV "IPEUMotASpdV";
BA_ "LongName" SG_ 153 PEUMotASpdV "Power Electric Unit Motor ASpeed Validity";
BA_ "SysSignalName" SG_ 153 PEUMotASpdV "PEUMotASpdV";
BA_ "CompuMethodName" SG_ 153 PEU_10ms_Group25_Reserved1 "PEU_10ms_Group25_Reserved1";
BA_ "GenSigStartValue" SG_ 153 PEU_10ms_Group25_Reserved1 7;
BA_ "ISignalName" SG_ 153 PEU_10ms_Group25_Reserved1 "IPEU_10ms_Group25_Reserved1";
BA_ "SysSignalName" SG_ 153 PEU_10ms_Group25_Reserved1 "PEU_10ms_Group25_Reserved1";
BA_ "CompuMethodName" SG_ 153 ReAxleMaxAvlblWhlRgtnTqV "ReAxleMaxAvlblWhlRgtnTqV";
BA_ "GenSigStartValue" SG_ 153 ReAxleMaxAvlblWhlRgtnTqV 1;
BA_ "ISignalName" SG_ 153 ReAxleMaxAvlblWhlRgtnTqV "IReAxleMaxAvlblWhlRgtnTqV";
BA_ "LongName" SG_ 153 ReAxleMaxAvlblWhlRgtnTqV "Rear Axle Maximum  Available  Wheel Regeneration Torque Valid";
BA_ "SysSignalName" SG_ 153 ReAxleMaxAvlblWhlRgtnTqV "ReAxleMaxAvlblWhlRgtnTqV";
BA_ "CompuMethodName" SG_ 153 ReAxleMaxAvlblWhlDrvTqV "ReAxleMaxAvlblWhlDrvTqV";
BA_ "GenSigStartValue" SG_ 153 ReAxleMaxAvlblWhlDrvTqV 1;
BA_ "ISignalName" SG_ 153 ReAxleMaxAvlblWhlDrvTqV "IReAxleMaxAvlblWhlDrvTqV";
BA_ "LongName" SG_ 153 ReAxleMaxAvlblWhlDrvTqV "Rear Axle Maximum  Available  Wheel Drive Torque Valid";
BA_ "SysSignalName" SG_ 153 ReAxleMaxAvlblWhlDrvTqV "ReAxleMaxAvlblWhlDrvTqV";
BA_ "CompuMethodName" SG_ 153 PEUMotBToqAchV "PEUMotBToqAchV";
BA_ "ISignalName" SG_ 153 PEUMotBToqAchV "IPEUMotBToqAchV";
BA_ "LongName" SG_ 153 PEUMotBToqAchV "Power Electric Unit Motor BTorque Achieved Validity";
BA_ "SysSignalName" SG_ 153 PEUMotBToqAchV "PEUMotBToqAchV";
BA_ "CompuMethodName" SG_ 153 PEUMotBSpdV "PEUMotBSpdV";
BA_ "ISignalName" SG_ 153 PEUMotBSpdV "IPEUMotBSpdV";
BA_ "LongName" SG_ 153 PEUMotBSpdV "Peu Motor BSpeed Validity";
BA_ "SysSignalName" SG_ 153 PEUMotBSpdV "PEUMotBSpdV";
BA_ "CompuMethodName" SG_ 153 PEUMotAToqAchV "PEUMotAToqAchV";
BA_ "ISignalName" SG_ 153 PEUMotAToqAchV "IPEUMotAToqAchV";
BA_ "LongName" SG_ 153 PEUMotAToqAchV "Peu Motor ATorque Achieved Validity";
BA_ "SysSignalName" SG_ 153 PEUMotAToqAchV "PEUMotAToqAchV";
BA_ "CompuMethodName" SG_ 153 ReAxleMaxAvlblWhlDrvTq "ReAxleMaxAvlblWhlDrvTq";
BA_ "GenSigStartValue" SG_ 153 ReAxleMaxAvlblWhlDrvTq 32767;
BA_ "ISignalName" SG_ 153 ReAxleMaxAvlblWhlDrvTq "IReAxleMaxAvlblWhlDrvTq";
BA_ "LongName" SG_ 153 ReAxleMaxAvlblWhlDrvTq "Rear Axle Maximum  Available  Wheel Drive Torque";
BA_ "SysSignalName" SG_ 153 ReAxleMaxAvlblWhlDrvTq "ReAxleMaxAvlblWhlDrvTq";
BA_ "CompuMethodName" SG_ 153 ReAxleMaxAvlblWhlRgtnTq "ReAxleMaxAvlblWhlRgtnTq";
BA_ "GenSigStartValue" SG_ 153 ReAxleMaxAvlblWhlRgtnTq 32767;
BA_ "ISignalName" SG_ 153 ReAxleMaxAvlblWhlRgtnTq "IReAxleMaxAvlblWhlRgtnTq";
BA_ "LongName" SG_ 153 ReAxleMaxAvlblWhlRgtnTq "Rear Axle Maximum  Available  Wheel Regeneration Torque";
BA_ "SysSignalName" SG_ 153 ReAxleMaxAvlblWhlRgtnTq "ReAxleMaxAvlblWhlRgtnTq";
BA_ "CompuMethodName" SG_ 153 PEU_10ms_Group25_Reserved147 "PEU_10ms_Group25_Reserved147";
BA_ "GenSigStartValue" SG_ 153 PEU_10ms_Group25_Reserved147 15;
BA_ "ISignalName" SG_ 153 PEU_10ms_Group25_Reserved147 "IPEU_10ms_Group25_Reserved147";
BA_ "SysSignalName" SG_ 153 PEU_10ms_Group25_Reserved147 "PEU_10ms_Group25_Reserved147";
BA_ "CompuMethodName" SG_ 153 PEUMotBMdAch "PEUMotBMdAch";
BA_ "ISignalName" SG_ 153 PEUMotBMdAch "IPEUMotBMdAch";
BA_ "LongName" SG_ 153 PEUMotBMdAch "Power Electric Unit Motor BMode Achieved";
BA_ "SysSignalName" SG_ 153 PEUMotBMdAch "PEUMotBMdAch";
BA_ "CompuMethodName" SG_ 153 PEUMotAMdAch "PEUMotAMdAch";
BA_ "ISignalName" SG_ 153 PEUMotAMdAch "IPEUMotAMdAch";
BA_ "LongName" SG_ 153 PEUMotAMdAch "Power Electric Unit Motor AMode Achieved";
BA_ "SysSignalName" SG_ 153 PEUMotAMdAch "PEUMotAMdAch";
BA_ "CompuMethodName" SG_ 153 PEU_10ms_Group25_Reserved3 "PEU_10ms_Group25_Reserved3";
BA_ "GenSigStartValue" SG_ 153 PEU_10ms_Group25_Reserved3 255;
BA_ "ISignalName" SG_ 153 PEU_10ms_Group25_Reserved3 "IPEU_10ms_Group25_Reserved3";
BA_ "SysSignalName" SG_ 153 PEU_10ms_Group25_Reserved3 "PEU_10ms_Group25_Reserved3";
BA_ "CompuMethodName" SG_ 1170 PEU_NM_BSMtoRMS_PTCANFD "PEU_NM_BSMtoRMS_PTCANFD";
BA_ "ISignalName" SG_ 1170 PEU_NM_BSMtoRMS_PTCANFD "IPEU_NM_BSMtoRMS_PTCANFD";
BA_ "SysSignalName" SG_ 1170 PEU_NM_BSMtoRMS_PTCANFD "PEU_NM_BSMtoRMS_PTCANFD";
BA_ "CompuMethodName" SG_ 1170 PEU_NM_PBSMtoRMS_PTCANFD "PEU_NM_PBSMtoRMS_PTCANFD";
BA_ "ISignalName" SG_ 1170 PEU_NM_PBSMtoRMS_PTCANFD "IPEU_NM_PBSMtoRMS_PTCANFD";
BA_ "SysSignalName" SG_ 1170 PEU_NM_PBSMtoRMS_PTCANFD "PEU_NM_PBSMtoRMS_PTCANFD";
BA_ "CompuMethodName" SG_ 1170 PEU_NM_RMStoNOS_PTCANFD "PEU_NM_RMStoNOS_PTCANFD";
BA_ "ISignalName" SG_ 1170 PEU_NM_RMStoNOS_PTCANFD "IPEU_NM_RMStoNOS_PTCANFD";
BA_ "SysSignalName" SG_ 1170 PEU_NM_RMStoNOS_PTCANFD "PEU_NM_RMStoNOS_PTCANFD";
BA_ "CompuMethodName" SG_ 1170 PEU_NM_RSStoNOS_PTCANFD "PEU_NM_RSStoNOS_PTCANFD";
BA_ "ISignalName" SG_ 1170 PEU_NM_RSStoNOS_PTCANFD "IPEU_NM_RSStoNOS_PTCANFD";
BA_ "SysSignalName" SG_ 1170 PEU_NM_RSStoNOS_PTCANFD "PEU_NM_RSStoNOS_PTCANFD";
BA_ "CompuMethodName" SG_ 1170 PEU_NM_RSStoRMS_PTCANFD "PEU_NM_RSStoRMS_PTCANFD";
BA_ "ISignalName" SG_ 1170 PEU_NM_RSStoRMS_PTCANFD "IPEU_NM_RSStoRMS_PTCANFD";
BA_ "SysSignalName" SG_ 1170 PEU_NM_RSStoRMS_PTCANFD "PEU_NM_RSStoRMS_PTCANFD";
BA_ "CompuMethodName" SG_ 1170 PEU_NM_NOStoRMS_PTCANFD "PEU_NM_NOStoRMS_PTCANFD";
BA_ "ISignalName" SG_ 1170 PEU_NM_NOStoRMS_PTCANFD "IPEU_NM_NOStoRMS_PTCANFD";
BA_ "SysSignalName" SG_ 1170 PEU_NM_NOStoRMS_PTCANFD "PEU_NM_NOStoRMS_PTCANFD";
BA_ "CompuMethodName" SG_ 1170 PEU_NM_NOSSta_PTCANFD "PEU_NM_NOSSta_PTCANFD";
BA_ "ISignalName" SG_ 1170 PEU_NM_NOSSta_PTCANFD "IPEU_NM_NOSSta_PTCANFD";
BA_ "SysSignalName" SG_ 1170 PEU_NM_NOSSta_PTCANFD "PEU_NM_NOSSta_PTCANFD";
BA_ "CompuMethodName" SG_ 1170 PEU_NM_RMSSta_PTCANFD "PEU_NM_RMSSta_PTCANFD";
BA_ "ISignalName" SG_ 1170 PEU_NM_RMSSta_PTCANFD "IPEU_NM_RMSSta_PTCANFD";
BA_ "SysSignalName" SG_ 1170 PEU_NM_RMSSta_PTCANFD "PEU_NM_RMSSta_PTCANFD";
BA_ "CompuMethodName" SG_ 1170 PEU_NWI_PTCANFD "PEU_NWI_PTCANFD";
BA_ "ISignalName" SG_ 1170 PEU_NWI_PTCANFD "IPEU_NWI_PTCANFD";
BA_ "SysSignalName" SG_ 1170 PEU_NWI_PTCANFD "PEU_NWI_PTCANFD";
BA_ "CompuMethodName" SG_ 1170 PEU_NOI_PTCANFD "PEU_NOI_PTCANFD";
BA_ "ISignalName" SG_ 1170 PEU_NOI_PTCANFD "IPEU_NOI_PTCANFD";
BA_ "SysSignalName" SG_ 1170 PEU_NOI_PTCANFD "PEU_NOI_PTCANFD";
BA_ "CompuMethodName" SG_ 1170 PEU_NKI_PTCANFD "PEU_NKI_PTCANFD";
BA_ "ISignalName" SG_ 1170 PEU_NKI_PTCANFD "IPEU_NKI_PTCANFD";
BA_ "SysSignalName" SG_ 1170 PEU_NKI_PTCANFD "PEU_NKI_PTCANFD";
BA_ "CompuMethodName" SG_ 714 AGSModestatus2 "AGSModestatus2";
BA_ "GenSigStartValue" SG_ 714 AGSModestatus2 3;
BA_ "ISignalName" SG_ 714 AGSModestatus2 "IAGSModestatus2";
BA_ "LongName" SG_ 714 AGSModestatus2 "Aero Grille Shutter Mode Status 2";
BA_ "SysSignalName" SG_ 714 AGSModestatus2 "AGSModestatus2";
BA_ "CompuMethodName" SG_ 714 AGSModestatus1 "AGSModestatus1";
BA_ "GenSigStartValue" SG_ 714 AGSModestatus1 3;
BA_ "ISignalName" SG_ 714 AGSModestatus1 "IAGSModestatus1";
BA_ "LongName" SG_ 714 AGSModestatus1 "Aero Grille Shutter Mode Status 1";
BA_ "SysSignalName" SG_ 714 AGSModestatus1 "AGSModestatus1";
BA_ "CompuMethodName" SG_ 714 AGS1FltRsn "AGS1FltRsn";
BA_ "ISignalName" SG_ 714 AGS1FltRsn "IAGS1FltRsn";
BA_ "LongName" SG_ 714 AGS1FltRsn "AGS1 Fault Reason";
BA_ "SysSignalName" SG_ 714 AGS1FltRsn "AGS1FltRsn";
BA_ "CompuMethodName" SG_ 714 AGS2FltRsn "AGS2FltRsn";
BA_ "ISignalName" SG_ 714 AGS2FltRsn "IAGS2FltRsn";
BA_ "LongName" SG_ 714 AGS2FltRsn "AGS2 Fault Reason";
BA_ "SysSignalName" SG_ 714 AGS2FltRsn "AGS2FltRsn";
BA_ "CompuMethodName" SG_ 714 AGSActualPosition1 "AGSActualPosition1";
BA_ "ISignalName" SG_ 714 AGSActualPosition1 "IAGSActualPosition1";
BA_ "LongName" SG_ 714 AGSActualPosition1 "Aero Grille Shutter Actual Position 1";
BA_ "SysSignalName" SG_ 714 AGSActualPosition1 "AGSActualPosition1";
BA_ "CompuMethodName" SG_ 714 AGSActualPosition2 "AGSActualPosition2";
BA_ "ISignalName" SG_ 714 AGSActualPosition2 "IAGSActualPosition2";
BA_ "LongName" SG_ 714 AGSActualPosition2 "Aero Grille Shutter Actual Position 2";
BA_ "SysSignalName" SG_ 714 AGSActualPosition2 "AGSActualPosition2";
BA_ "CompuMethodName" SG_ 714 EPTElecWtrPumpActuSpd "EPTElecWtrPumpActuSpd";
BA_ "GenSigStartValue" SG_ 714 EPTElecWtrPumpActuSpd 255;
BA_ "ISignalName" SG_ 714 EPTElecWtrPumpActuSpd "IEPTElecWtrPumpActuSpd";
BA_ "LongName" SG_ 714 EPTElecWtrPumpActuSpd "Ept Electric Water Pump Actual Speed";
BA_ "SysSignalName" SG_ 714 EPTElecWtrPumpActuSpd "EPTElecWtrPumpActuSpd";
BA_ "CompuMethodName" SG_ 714 ESSElecWtrPumpActuSpd "ESSElecWtrPumpActuSpd";
BA_ "GenSigStartValue" SG_ 714 ESSElecWtrPumpActuSpd 255;
BA_ "ISignalName" SG_ 714 ESSElecWtrPumpActuSpd "IESSElecWtrPumpActuSpd";
BA_ "LongName" SG_ 714 ESSElecWtrPumpActuSpd "Ess Electric Water Pump Actual Speed";
BA_ "SysSignalName" SG_ 714 ESSElecWtrPumpActuSpd "ESSElecWtrPumpActuSpd";
BA_ "CompuMethodName" SG_ 714 EDUClntTem "EDUClntTem";
BA_ "ISignalName" SG_ 714 EDUClntTem "IEDUClntTem";
BA_ "LongName" SG_ 714 EDUClntTem "EDU Coolent Temperature";
BA_ "SysSignalName" SG_ 714 EDUClntTem "EDUClntTem";
BA_ "CompuMethodName" SG_ 714 AGSTorqueResponse2 "AGSTorqueResponse2";
BA_ "GenSigStartValue" SG_ 714 AGSTorqueResponse2 3;
BA_ "ISignalName" SG_ 714 AGSTorqueResponse2 "IAGSTorqueResponse2";
BA_ "LongName" SG_ 714 AGSTorqueResponse2 "Aero Grille Shutter Torque Response 2";
BA_ "SysSignalName" SG_ 714 AGSTorqueResponse2 "AGSTorqueResponse2";
BA_ "CompuMethodName" SG_ 714 AGSTorqueResponse1 "AGSTorqueResponse1";
BA_ "GenSigStartValue" SG_ 714 AGSTorqueResponse1 3;
BA_ "ISignalName" SG_ 714 AGSTorqueResponse1 "IAGSTorqueResponse1";
BA_ "LongName" SG_ 714 AGSTorqueResponse1 "Aero Grille Shutter Torque Response 1";
BA_ "SysSignalName" SG_ 714 AGSTorqueResponse1 "AGSTorqueResponse1";
BA_ "CompuMethodName" SG_ 714 AGSSelflearnStatus2 "AGSSelflearnStatus2";
BA_ "GenSigStartValue" SG_ 714 AGSSelflearnStatus2 3;
BA_ "ISignalName" SG_ 714 AGSSelflearnStatus2 "IAGSSelflearnStatus2";
BA_ "LongName" SG_ 714 AGSSelflearnStatus2 "Aero Grille Shutter Self-learn Status 2";
BA_ "SysSignalName" SG_ 714 AGSSelflearnStatus2 "AGSSelflearnStatus2";
BA_ "CompuMethodName" SG_ 714 AGSSelflearnStatus1 "AGSSelflearnStatus1";
BA_ "GenSigStartValue" SG_ 714 AGSSelflearnStatus1 3;
BA_ "ISignalName" SG_ 714 AGSSelflearnStatus1 "IAGSSelflearnStatus1";
BA_ "LongName" SG_ 714 AGSSelflearnStatus1 "Aero Grille Shutter Self-learn Status 1";
BA_ "SysSignalName" SG_ 714 AGSSelflearnStatus1 "AGSSelflearnStatus1";
BA_ "CompuMethodName" SG_ 714 OBMLifeTimeParmFromEsMaxLmt "OBMLifeTimeParmFromEsMaxLmt";
BA_ "ISignalName" SG_ 714 OBMLifeTimeParmFromEsMaxLmt "IOBMLifeTimeParmFromEsMaxLmt";
BA_ "LongName" SG_ 714 OBMLifeTimeParmFromEsMaxLmt "OBM lifetime parameter from EMS has reached its maximum limit";
BA_ "SysSignalName" SG_ 714 OBMLifeTimeParmFromEsMaxLmt "OBMLifeTimeParmFromEsMaxLmt";
BA_ "CompuMethodName" SG_ 714 EndSocTrgtHCUV "EndSocTrgtHCUV";
BA_ "GenSigStartValue" SG_ 714 EndSocTrgtHCUV 1;
BA_ "ISignalName" SG_ 714 EndSocTrgtHCUV "IEndSocTrgtHCUV";
BA_ "LongName" SG_ 714 EndSocTrgtHCUV "End Soc Target HCU Validity";
BA_ "SysSignalName" SG_ 714 EndSocTrgtHCUV "EndSocTrgtHCUV";
BA_ "CompuMethodName" SG_ 714 AISocMngtActv "AISocMngtActv";
BA_ "ISignalName" SG_ 714 AISocMngtActv "IAISocMngtActv";
BA_ "LongName" SG_ 714 AISocMngtActv "AI SOC Management Active";
BA_ "SysSignalName" SG_ 714 AISocMngtActv "AISocMngtActv";
BA_ "CompuMethodName" SG_ 714 TrgtSOCUpdtReq "TrgtSOCUpdtReq";
BA_ "ISignalName" SG_ 714 TrgtSOCUpdtReq "ITrgtSOCUpdtReq";
BA_ "LongName" SG_ 714 TrgtSOCUpdtReq "Target Soc Update Request";
BA_ "SysSignalName" SG_ 714 TrgtSOCUpdtReq "TrgtSOCUpdtReq";
BA_ "CompuMethodName" SG_ 714 WCACThrWayVlvActuPosV "WCACThrWayVlvActuPosV";
BA_ "GenSigStartValue" SG_ 714 WCACThrWayVlvActuPosV 1;
BA_ "ISignalName" SG_ 714 WCACThrWayVlvActuPosV "IWCACThrWayVlvActuPosV";
BA_ "LongName" SG_ 714 WCACThrWayVlvActuPosV "Water Charger Air Cooler Three Way Valve Actual Position Validity";
BA_ "SysSignalName" SG_ 714 WCACThrWayVlvActuPosV "WCACThrWayVlvActuPosV";
BA_ "CompuMethodName" SG_ 714 EDUClntTemV "EDUClntTemV";
BA_ "GenSigStartValue" SG_ 714 EDUClntTemV 1;
BA_ "ISignalName" SG_ 714 EDUClntTemV "IEDUClntTemV";
BA_ "LongName" SG_ 714 EDUClntTemV "EDU Coolent Temperature Valid";
BA_ "SysSignalName" SG_ 714 EDUClntTemV "EDUClntTemV";
BA_ "CompuMethodName" SG_ 714 AGSMoveStatus2 "AGSMoveStatus2";
BA_ "ISignalName" SG_ 714 AGSMoveStatus2 "IAGSMoveStatus2";
BA_ "LongName" SG_ 714 AGSMoveStatus2 "Aero Grille Shutter Move Status 2";
BA_ "SysSignalName" SG_ 714 AGSMoveStatus2 "AGSMoveStatus2";
BA_ "CompuMethodName" SG_ 714 AGSMoveStatus1 "AGSMoveStatus1";
BA_ "ISignalName" SG_ 714 AGSMoveStatus1 "IAGSMoveStatus1";
BA_ "LongName" SG_ 714 AGSMoveStatus1 "Aero Grille Shutter Move Status 1";
BA_ "SysSignalName" SG_ 714 AGSMoveStatus1 "AGSMoveStatus1";
BA_ "CompuMethodName" SG_ 714 WCACThrWayVlvActuPos "WCACThrWayVlvActuPos";
BA_ "ISignalName" SG_ 714 WCACThrWayVlvActuPos "IWCACThrWayVlvActuPos";
BA_ "LongName" SG_ 714 WCACThrWayVlvActuPos "Water Charger Air Cooler Three Way Valve Actual Position";
BA_ "SysSignalName" SG_ 714 WCACThrWayVlvActuPos "WCACThrWayVlvActuPos";
BA_ "CompuMethodName" SG_ 714 EndSocTrgtHCU "EndSocTrgtHCU";
BA_ "ISignalName" SG_ 714 EndSocTrgtHCU "IEndSocTrgtHCU";
BA_ "LongName" SG_ 714 EndSocTrgtHCU "End Soc Target HCU";
BA_ "SysSignalName" SG_ 714 EndSocTrgtHCU "EndSocTrgtHCU";
BA_ "CompuMethodName" SG_ 1196 PICM_NM_BSMtoRMS_PTCANFD "PICM_NM_BSMtoRMS_PTCANFD";
BA_ "ISignalName" SG_ 1196 PICM_NM_BSMtoRMS_PTCANFD "IPICM_NM_BSMtoRMS_PTCANFD";
BA_ "SysSignalName" SG_ 1196 PICM_NM_BSMtoRMS_PTCANFD "PICM_NM_BSMtoRMS_PTCANFD";
BA_ "CompuMethodName" SG_ 1196 PICM_NM_PBSMtoRMS_PTCANFD "PICM_NM_PBSMtoRMS_PTCANFD";
BA_ "ISignalName" SG_ 1196 PICM_NM_PBSMtoRMS_PTCANFD "IPICM_NM_PBSMtoRMS_PTCANFD";
BA_ "SysSignalName" SG_ 1196 PICM_NM_PBSMtoRMS_PTCANFD "PICM_NM_PBSMtoRMS_PTCANFD";
BA_ "CompuMethodName" SG_ 1196 PICM_NM_RMStoNOS_PTCANFD "PICM_NM_RMStoNOS_PTCANFD";
BA_ "ISignalName" SG_ 1196 PICM_NM_RMStoNOS_PTCANFD "IPICM_NM_RMStoNOS_PTCANFD";
BA_ "SysSignalName" SG_ 1196 PICM_NM_RMStoNOS_PTCANFD "PICM_NM_RMStoNOS_PTCANFD";
BA_ "CompuMethodName" SG_ 1196 PICM_NM_RSStoNOS_PTCANFD "PICM_NM_RSStoNOS_PTCANFD";
BA_ "ISignalName" SG_ 1196 PICM_NM_RSStoNOS_PTCANFD "IPICM_NM_RSStoNOS_PTCANFD";
BA_ "SysSignalName" SG_ 1196 PICM_NM_RSStoNOS_PTCANFD "PICM_NM_RSStoNOS_PTCANFD";
BA_ "CompuMethodName" SG_ 1196 PICM_NM_RSStoRMS_PTCANFD "PICM_NM_RSStoRMS_PTCANFD";
BA_ "ISignalName" SG_ 1196 PICM_NM_RSStoRMS_PTCANFD "IPICM_NM_RSStoRMS_PTCANFD";
BA_ "SysSignalName" SG_ 1196 PICM_NM_RSStoRMS_PTCANFD "PICM_NM_RSStoRMS_PTCANFD";
BA_ "CompuMethodName" SG_ 1196 PICM_NM_NOStoRMS_PTCANFD "PICM_NM_NOStoRMS_PTCANFD";
BA_ "ISignalName" SG_ 1196 PICM_NM_NOStoRMS_PTCANFD "IPICM_NM_NOStoRMS_PTCANFD";
BA_ "SysSignalName" SG_ 1196 PICM_NM_NOStoRMS_PTCANFD "PICM_NM_NOStoRMS_PTCANFD";
BA_ "CompuMethodName" SG_ 1196 PICM_NM_NOSSta_PTCANFD "PICM_NM_NOSSta_PTCANFD";
BA_ "ISignalName" SG_ 1196 PICM_NM_NOSSta_PTCANFD "IPICM_NM_NOSSta_PTCANFD";
BA_ "SysSignalName" SG_ 1196 PICM_NM_NOSSta_PTCANFD "PICM_NM_NOSSta_PTCANFD";
BA_ "CompuMethodName" SG_ 1196 PICM_NM_RMSSta_PTCANFD "PICM_NM_RMSSta_PTCANFD";
BA_ "ISignalName" SG_ 1196 PICM_NM_RMSSta_PTCANFD "IPICM_NM_RMSSta_PTCANFD";
BA_ "SysSignalName" SG_ 1196 PICM_NM_RMSSta_PTCANFD "PICM_NM_RMSSta_PTCANFD";
BA_ "CompuMethodName" SG_ 1196 PICM_NWI_PTCANFD "PICM_NWI_PTCANFD";
BA_ "ISignalName" SG_ 1196 PICM_NWI_PTCANFD "IPICM_NWI_PTCANFD";
BA_ "SysSignalName" SG_ 1196 PICM_NWI_PTCANFD "PICM_NWI_PTCANFD";
BA_ "CompuMethodName" SG_ 1196 PICM_NOI_PTCANFD "PICM_NOI_PTCANFD";
BA_ "ISignalName" SG_ 1196 PICM_NOI_PTCANFD "IPICM_NOI_PTCANFD";
BA_ "SysSignalName" SG_ 1196 PICM_NOI_PTCANFD "PICM_NOI_PTCANFD";
BA_ "CompuMethodName" SG_ 1196 PICM_NKI_PTCANFD "PICM_NKI_PTCANFD";
BA_ "ISignalName" SG_ 1196 PICM_NKI_PTCANFD "IPICM_NKI_PTCANFD";
BA_ "SysSignalName" SG_ 1196 PICM_NKI_PTCANFD "PICM_NKI_PTCANFD";
BA_ "CompuMethodName" SG_ 140 PICU_10ms_Group03_CRC "PICU_10ms_Group03_CRC";
BA_ "ISignalName" SG_ 140 PICU_10ms_Group03_CRC "IPICU_10ms_Group03_CRC";
BA_ "LongName" SG_ 140 PICU_10ms_Group03_CRC "PICU_10ms_Group03_CRC";
BA_ "SysSignalName" SG_ 140 PICU_10ms_Group03_CRC "PICU_10ms_Group03_CRC";
BA_ "CompuMethodName" SG_ 140 PICU_10ms_Group03_RC "PICU_10ms_Group03_RC";
BA_ "ISignalName" SG_ 140 PICU_10ms_Group03_RC "IPICU_10ms_Group03_RC";
BA_ "LongName" SG_ 140 PICU_10ms_Group03_RC "PICU_10ms_Group03_RC";
BA_ "SysSignalName" SG_ 140 PICU_10ms_Group03_RC "PICU_10ms_Group03_RC";
BA_ "CompuMethodName" SG_ 140 FrtAxleActuWhlToqV "FrtAxleActuWhlToqV";
BA_ "GenSigStartValue" SG_ 140 FrtAxleActuWhlToqV 1;
BA_ "ISignalName" SG_ 140 FrtAxleActuWhlToqV "IFrtAxleActuWhlToqV";
BA_ "LongName" SG_ 140 FrtAxleActuWhlToqV "Front Axle Actual Wheel Torque Validity";
BA_ "SysSignalName" SG_ 140 FrtAxleActuWhlToqV "FrtAxleActuWhlToqV";
BA_ "CompuMethodName" SG_ 140 PICU_10ms_Group03_Reserved1 "PICU_10ms_Group03_Reserved1";
BA_ "GenSigStartValue" SG_ 140 PICU_10ms_Group03_Reserved1 1;
BA_ "ISignalName" SG_ 140 PICU_10ms_Group03_Reserved1 "IPICU_10ms_Group03_Reserved1";
BA_ "SysSignalName" SG_ 140 PICU_10ms_Group03_Reserved1 "PICU_10ms_Group03_Reserved1";
BA_ "CompuMethodName" SG_ 140 DrvrReqRrAxleWhlToqV "DrvrReqRrAxleWhlToqV";
BA_ "GenSigStartValue" SG_ 140 DrvrReqRrAxleWhlToqV 1;
BA_ "ISignalName" SG_ 140 DrvrReqRrAxleWhlToqV "IDrvrReqRrAxleWhlToqV";
BA_ "LongName" SG_ 140 DrvrReqRrAxleWhlToqV "Driver Request Rear Axle Wheel Torque Validity";
BA_ "SysSignalName" SG_ 140 DrvrReqRrAxleWhlToqV "DrvrReqRrAxleWhlToqV";
BA_ "CompuMethodName" SG_ 140 DrvrReqFrtAxleWhlToqV "DrvrReqFrtAxleWhlToqV";
BA_ "GenSigStartValue" SG_ 140 DrvrReqFrtAxleWhlToqV 1;
BA_ "ISignalName" SG_ 140 DrvrReqFrtAxleWhlToqV "IDrvrReqFrtAxleWhlToqV";
BA_ "LongName" SG_ 140 DrvrReqFrtAxleWhlToqV "Driver Request Front Axle Wheel Torque Validity";
BA_ "SysSignalName" SG_ 140 DrvrReqFrtAxleWhlToqV "DrvrReqFrtAxleWhlToqV";
BA_ "CompuMethodName" SG_ 140 DrvrReqFrtAxleWhlToq "DrvrReqFrtAxleWhlToq";
BA_ "GenSigStartValue" SG_ 140 DrvrReqFrtAxleWhlToq 30000;
BA_ "ISignalName" SG_ 140 DrvrReqFrtAxleWhlToq "IDrvrReqFrtAxleWhlToq";
BA_ "LongName" SG_ 140 DrvrReqFrtAxleWhlToq "Driver Request Front Axle Wheel Torque";
BA_ "SysSignalName" SG_ 140 DrvrReqFrtAxleWhlToq "DrvrReqFrtAxleWhlToq";
BA_ "CompuMethodName" SG_ 140 DrvrReqRrAxleWhlToq "DrvrReqRrAxleWhlToq";
BA_ "GenSigStartValue" SG_ 140 DrvrReqRrAxleWhlToq 30000;
BA_ "ISignalName" SG_ 140 DrvrReqRrAxleWhlToq "IDrvrReqRrAxleWhlToq";
BA_ "LongName" SG_ 140 DrvrReqRrAxleWhlToq "Driver Request Rear Axle Wheel Torque";
BA_ "SysSignalName" SG_ 140 DrvrReqRrAxleWhlToq "DrvrReqRrAxleWhlToq";
BA_ "CompuMethodName" SG_ 140 FrtAxleActuWhlToq "FrtAxleActuWhlToq";
BA_ "GenSigStartValue" SG_ 140 FrtAxleActuWhlToq 30000;
BA_ "ISignalName" SG_ 140 FrtAxleActuWhlToq "IFrtAxleActuWhlToq";
BA_ "LongName" SG_ 140 FrtAxleActuWhlToq "Front Axle Actual Wheel Torque";
BA_ "SysSignalName" SG_ 140 FrtAxleActuWhlToq "FrtAxleActuWhlToq";
BA_ "CompuMethodName" SG_ 140 RrAxleActuWhlToq "RrAxleActuWhlToq";
BA_ "GenSigStartValue" SG_ 140 RrAxleActuWhlToq 30000;
BA_ "ISignalName" SG_ 140 RrAxleActuWhlToq "IRrAxleActuWhlToq";
BA_ "LongName" SG_ 140 RrAxleActuWhlToq "Rear Axle Actual Wheel Torque";
BA_ "SysSignalName" SG_ 140 RrAxleActuWhlToq "RrAxleActuWhlToq";
BA_ "CompuMethodName" SG_ 140 TotActuWhlToq "TotActuWhlToq";
BA_ "GenSigStartValue" SG_ 140 TotActuWhlToq 30000;
BA_ "ISignalName" SG_ 140 TotActuWhlToq "ITotActuWhlToq";
BA_ "LongName" SG_ 140 TotActuWhlToq "Total Actual Wheel Torque";
BA_ "SysSignalName" SG_ 140 TotActuWhlToq "TotActuWhlToq";
BA_ "CompuMethodName" SG_ 140 PICU_10ms_Group03_Reserved2 "PICU_10ms_Group03_Reserved2";
BA_ "GenSigStartValue" SG_ 140 PICU_10ms_Group03_Reserved2 15;
BA_ "ISignalName" SG_ 140 PICU_10ms_Group03_Reserved2 "IPICU_10ms_Group03_Reserved2";
BA_ "SysSignalName" SG_ 140 PICU_10ms_Group03_Reserved2 "PICU_10ms_Group03_Reserved2";
BA_ "CompuMethodName" SG_ 140 TotActuWhlToqV "TotActuWhlToqV";
BA_ "GenSigStartValue" SG_ 140 TotActuWhlToqV 1;
BA_ "ISignalName" SG_ 140 TotActuWhlToqV "ITotActuWhlToqV";
BA_ "LongName" SG_ 140 TotActuWhlToqV "Total Actual Wheel Torque Validity";
BA_ "SysSignalName" SG_ 140 TotActuWhlToqV "TotActuWhlToqV";
BA_ "CompuMethodName" SG_ 140 RrAxleActuWhlToqV "RrAxleActuWhlToqV";
BA_ "GenSigStartValue" SG_ 140 RrAxleActuWhlToqV 1;
BA_ "ISignalName" SG_ 140 RrAxleActuWhlToqV "IRrAxleActuWhlToqV";
BA_ "LongName" SG_ 140 RrAxleActuWhlToqV "Rear Axle Actual Wheel Torque Validity";
BA_ "SysSignalName" SG_ 140 RrAxleActuWhlToqV "RrAxleActuWhlToqV";
BA_ "CompuMethodName" SG_ 140 PtHVCntarReq "PtHVCntarReq";
BA_ "ISignalName" SG_ 140 PtHVCntarReq "IPtHVCntarReq";
BA_ "LongName" SG_ 140 PtHVCntarReq "Powertrain High Voltage Contactor Request";
BA_ "SysSignalName" SG_ 140 PtHVCntarReq "PtHVCntarReq";
BA_ "CompuMethodName" SG_ 140 PICU_10ms_Group03_Reserved3 "PICU_10ms_Group03_Reserved3";
BA_ "GenSigStartValue" SG_ 140 PICU_10ms_Group03_Reserved3 255;
BA_ "ISignalName" SG_ 140 PICU_10ms_Group03_Reserved3 "IPICU_10ms_Group03_Reserved3";
BA_ "SysSignalName" SG_ 140 PICU_10ms_Group03_Reserved3 "PICU_10ms_Group03_Reserved3";
BA_ "CompuMethodName" SG_ 140 PICU_10ms_Group03_Reserved4 "PICU_10ms_Group03_Reserved4";
BA_ "GenSigStartValue" SG_ 140 PICU_10ms_Group03_Reserved4 255;
BA_ "ISignalName" SG_ 140 PICU_10ms_Group03_Reserved4 "IPICU_10ms_Group03_Reserved4";
BA_ "SysSignalName" SG_ 140 PICU_10ms_Group03_Reserved4 "PICU_10ms_Group03_Reserved4";
BA_ "CompuMethodName" SG_ 140 PICU_10ms_Group03_Reserved5 "PICU_10ms_Group03_Reserved5";
BA_ "GenSigStartValue" SG_ 140 PICU_10ms_Group03_Reserved5 255;
BA_ "ISignalName" SG_ 140 PICU_10ms_Group03_Reserved5 "IPICU_10ms_Group03_Reserved5";
BA_ "SysSignalName" SG_ 140 PICU_10ms_Group03_Reserved5 "PICU_10ms_Group03_Reserved5";
BA_ "CompuMethodName" SG_ 140 PICU_10ms_Group03_Reserved6 "PICU_10ms_Group03_Reserved6";
BA_ "GenSigStartValue" SG_ 140 PICU_10ms_Group03_Reserved6 255;
BA_ "ISignalName" SG_ 140 PICU_10ms_Group03_Reserved6 "IPICU_10ms_Group03_Reserved6";
BA_ "SysSignalName" SG_ 140 PICU_10ms_Group03_Reserved6 "PICU_10ms_Group03_Reserved6";
BA_ "CompuMethodName" SG_ 140 PICU_10ms_Group03_Reserved7 "PICU_10ms_Group03_Reserved7";
BA_ "GenSigStartValue" SG_ 140 PICU_10ms_Group03_Reserved7 255;
BA_ "ISignalName" SG_ 140 PICU_10ms_Group03_Reserved7 "IPICU_10ms_Group03_Reserved7";
BA_ "SysSignalName" SG_ 140 PICU_10ms_Group03_Reserved7 "PICU_10ms_Group03_Reserved7";
BA_ "CompuMethodName" SG_ 140 PICU_10ms_Group03_Reserved8 "PICU_10ms_Group03_Reserved8";
BA_ "GenSigStartValue" SG_ 140 PICU_10ms_Group03_Reserved8 255;
BA_ "ISignalName" SG_ 140 PICU_10ms_Group03_Reserved8 "IPICU_10ms_Group03_Reserved8";
BA_ "SysSignalName" SG_ 140 PICU_10ms_Group03_Reserved8 "PICU_10ms_Group03_Reserved8";
BA_ "CompuMethodName" SG_ 140 PICU_10ms_Group03_Reserved9 "PICU_10ms_Group03_Reserved9";
BA_ "GenSigStartValue" SG_ 140 PICU_10ms_Group03_Reserved9 255;
BA_ "ISignalName" SG_ 140 PICU_10ms_Group03_Reserved9 "IPICU_10ms_Group03_Reserved9";
BA_ "SysSignalName" SG_ 140 PICU_10ms_Group03_Reserved9 "PICU_10ms_Group03_Reserved9";
BA_ "CompuMethodName" SG_ 359 PICU_20ms_Group11_CRC "PICU_20ms_Group11_CRC";
BA_ "ISignalName" SG_ 359 PICU_20ms_Group11_CRC "IPICU_20ms_Group11_CRC";
BA_ "SysSignalName" SG_ 359 PICU_20ms_Group11_CRC "PICU_20ms_Group11_CRC";
BA_ "CompuMethodName" SG_ 359 PICU_20ms_Group11_RC "PICU_20ms_Group11_RC";
BA_ "ISignalName" SG_ 359 PICU_20ms_Group11_RC "IPICU_20ms_Group11_RC";
BA_ "SysSignalName" SG_ 359 PICU_20ms_Group11_RC "PICU_20ms_Group11_RC";
BA_ "CompuMethodName" SG_ 359 PICU_20ms_Group11_Reserved1 "PICU_20ms_Group11_Reserved1";
BA_ "GenSigStartValue" SG_ 359 PICU_20ms_Group11_Reserved1 1;
BA_ "ISignalName" SG_ 359 PICU_20ms_Group11_Reserved1 "IPICU_20ms_Group11_Reserved1";
BA_ "SysSignalName" SG_ 359 PICU_20ms_Group11_Reserved1 "PICU_20ms_Group11_Reserved1";
BA_ "CompuMethodName" SG_ 359 HybAPAAvlbl "HybAPAAvlbl";
BA_ "ISignalName" SG_ 359 HybAPAAvlbl "IHybAPAAvlbl";
BA_ "LongName" SG_ 359 HybAPAAvlbl "Hybrid APA Avlbly";
BA_ "SysSignalName" SG_ 359 HybAPAAvlbl "HybAPAAvlbl";
BA_ "CompuMethodName" SG_ 359 MinAvlblTotWhlToqV "MinAvlblTotWhlToqV";
BA_ "GenSigStartValue" SG_ 359 MinAvlblTotWhlToqV 1;
BA_ "ISignalName" SG_ 359 MinAvlblTotWhlToqV "IMinAvlblTotWhlToqV";
BA_ "LongName" SG_ 359 MinAvlblTotWhlToqV "Minimum Available Total Wheel Torque Validity";
BA_ "SysSignalName" SG_ 359 MinAvlblTotWhlToqV "MinAvlblTotWhlToqV";
BA_ "CompuMethodName" SG_ 359 MaxAvlblTotWhlToqV "MaxAvlblTotWhlToqV";
BA_ "GenSigStartValue" SG_ 359 MaxAvlblTotWhlToqV 1;
BA_ "ISignalName" SG_ 359 MaxAvlblTotWhlToqV "IMaxAvlblTotWhlToqV";
BA_ "LongName" SG_ 359 MaxAvlblTotWhlToqV "Maximum Available Total Wheel Torque Validity";
BA_ "SysSignalName" SG_ 359 MaxAvlblTotWhlToqV "MaxAvlblTotWhlToqV";
BA_ "CompuMethodName" SG_ 359 MaxAvlblTotWhlToq "MaxAvlblTotWhlToq";
BA_ "GenSigStartValue" SG_ 359 MaxAvlblTotWhlToq 30000;
BA_ "ISignalName" SG_ 359 MaxAvlblTotWhlToq "IMaxAvlblTotWhlToq";
BA_ "LongName" SG_ 359 MaxAvlblTotWhlToq "Maximum Available Total Wheel Torque";
BA_ "SysSignalName" SG_ 359 MaxAvlblTotWhlToq "MaxAvlblTotWhlToq";
BA_ "CompuMethodName" SG_ 359 MinAvlblTotWhlToq "MinAvlblTotWhlToq";
BA_ "GenSigStartValue" SG_ 359 MinAvlblTotWhlToq 30000;
BA_ "ISignalName" SG_ 359 MinAvlblTotWhlToq "IMinAvlblTotWhlToq";
BA_ "LongName" SG_ 359 MinAvlblTotWhlToq "Minimum Available Total Wheel Torque";
BA_ "SysSignalName" SG_ 359 MinAvlblTotWhlToq "MinAvlblTotWhlToq";
BA_ "CompuMethodName" SG_ 359 PICU_20ms_Group11_Reserved2 "PICU_20ms_Group11_Reserved2";
BA_ "GenSigStartValue" SG_ 359 PICU_20ms_Group11_Reserved2 255;
BA_ "ISignalName" SG_ 359 PICU_20ms_Group11_Reserved2 "IPICU_20ms_Group11_Reserved2";
BA_ "SysSignalName" SG_ 359 PICU_20ms_Group11_Reserved2 "PICU_20ms_Group11_Reserved2";
BA_ "CompuMethodName" SG_ 359 CstRgtnBrkLgtReq "CstRgtnBrkLgtReq";
BA_ "ISignalName" SG_ 359 CstRgtnBrkLgtReq "ICstRgtnBrkLgtReq";
BA_ "LongName" SG_ 359 CstRgtnBrkLgtReq "Coast_Regenation_Brake_Light_Request";
BA_ "SysSignalName" SG_ 359 CstRgtnBrkLgtReq "CstRgtnBrkLgtReq";
BA_ "CompuMethodName" SG_ 359 CstRgtnBrkLgtReqV "CstRgtnBrkLgtReqV";
BA_ "ISignalName" SG_ 359 CstRgtnBrkLgtReqV "ICstRgtnBrkLgtReqV";
BA_ "LongName" SG_ 359 CstRgtnBrkLgtReqV "Coast_Regenation_Brake_Light_Request_Valid";
BA_ "SysSignalName" SG_ 359 CstRgtnBrkLgtReqV "CstRgtnBrkLgtReqV";
BA_ "CompuMethodName" SG_ 359 PICU_20ms_Group11_Reserved3 "PICU_20ms_Group11_Reserved3";
BA_ "GenSigStartValue" SG_ 359 PICU_20ms_Group11_Reserved3 63;
BA_ "ISignalName" SG_ 359 PICU_20ms_Group11_Reserved3 "IPICU_20ms_Group11_Reserved3";
BA_ "SysSignalName" SG_ 359 PICU_20ms_Group11_Reserved3 "PICU_20ms_Group11_Reserved3";
BA_ "CompuMethodName" SG_ 359 PICU_20ms_Group11_Reserved4 "PICU_20ms_Group11_Reserved4";
BA_ "GenSigStartValue" SG_ 359 PICU_20ms_Group11_Reserved4 255;
BA_ "ISignalName" SG_ 359 PICU_20ms_Group11_Reserved4 "IPICU_20ms_Group11_Reserved4";
BA_ "SysSignalName" SG_ 359 PICU_20ms_Group11_Reserved4 "PICU_20ms_Group11_Reserved4";
BA_ "CompuMethodName" SG_ 359 PICU_20ms_Group11_Reserved6 "PICU_20ms_Group11_Reserved6";
BA_ "GenSigStartValue" SG_ 359 PICU_20ms_Group11_Reserved6 3;
BA_ "ISignalName" SG_ 359 PICU_20ms_Group11_Reserved6 "IPICU_20ms_Group11_Reserved6";
BA_ "SysSignalName" SG_ 359 PICU_20ms_Group11_Reserved6 "PICU_20ms_Group11_Reserved6";
BA_ "CompuMethodName" SG_ 359 RdundtHybCmddEnToqRespTyp "RdundtHybCmddEnToqRespTyp";
BA_ "ISignalName" SG_ 359 RdundtHybCmddEnToqRespTyp "IRdundtHybCmddEnToqRespTyp";
BA_ "LongName" SG_ 359 RdundtHybCmddEnToqRespTyp "Redundant Hybrid Commanded Engine Torque Response Type";
BA_ "SysSignalName" SG_ 359 RdundtHybCmddEnToqRespTyp "RdundtHybCmddEnToqRespTyp";
BA_ "CompuMethodName" SG_ 359 PICU_20ms_Group11_Reserved5 "PICU_20ms_Group11_Reserved5";
BA_ "GenSigStartValue" SG_ 359 PICU_20ms_Group11_Reserved5 15;
BA_ "ISignalName" SG_ 359 PICU_20ms_Group11_Reserved5 "IPICU_20ms_Group11_Reserved5";
BA_ "SysSignalName" SG_ 359 PICU_20ms_Group11_Reserved5 "PICU_20ms_Group11_Reserved5";
BA_ "CompuMethodName" SG_ 359 PICU_20ms_Group11_Reserved7 "PICU_20ms_Group11_Reserved7";
BA_ "GenSigStartValue" SG_ 359 PICU_20ms_Group11_Reserved7 255;
BA_ "ISignalName" SG_ 359 PICU_20ms_Group11_Reserved7 "IPICU_20ms_Group11_Reserved7";
BA_ "SysSignalName" SG_ 359 PICU_20ms_Group11_Reserved7 "PICU_20ms_Group11_Reserved7";
BA_ "CompuMethodName" SG_ 359 RdundtHybCmddEnToqImmd "RdundtHybCmddEnToqImmd";
BA_ "GenSigStartValue" SG_ 359 RdundtHybCmddEnToqImmd 1696;
BA_ "ISignalName" SG_ 359 RdundtHybCmddEnToqImmd "IRdundtHybCmddEnToqImmd";
BA_ "LongName" SG_ 359 RdundtHybCmddEnToqImmd "Redundant Hybrid Commanded Engine Torque Immediate";
BA_ "SysSignalName" SG_ 359 RdundtHybCmddEnToqImmd "RdundtHybCmddEnToqImmd";
BA_ "CompuMethodName" SG_ 359 RdundtHybCmddEnToqPrdtd "RdundtHybCmddEnToqPrdtd";
BA_ "GenSigStartValue" SG_ 359 RdundtHybCmddEnToqPrdtd 1696;
BA_ "ISignalName" SG_ 359 RdundtHybCmddEnToqPrdtd "IRdundtHybCmddEnToqPrdtd";
BA_ "LongName" SG_ 359 RdundtHybCmddEnToqPrdtd "Redundant Hybrid Commanded Engine Torque Predicted";
BA_ "SysSignalName" SG_ 359 RdundtHybCmddEnToqPrdtd "RdundtHybCmddEnToqPrdtd";
BA_ "CompuMethodName" SG_ 359 PICU_20ms_Group11_Reserved8 "PICU_20ms_Group11_Reserved8";
BA_ "GenSigStartValue" SG_ 359 PICU_20ms_Group11_Reserved8 255;
BA_ "ISignalName" SG_ 359 PICU_20ms_Group11_Reserved8 "IPICU_20ms_Group11_Reserved8";
BA_ "SysSignalName" SG_ 359 PICU_20ms_Group11_Reserved8 "PICU_20ms_Group11_Reserved8";
BA_ "CompuMethodName" SG_ 359 PICU_20ms_Group11_Reserved9 "PICU_20ms_Group11_Reserved9";
BA_ "GenSigStartValue" SG_ 359 PICU_20ms_Group11_Reserved9 255;
BA_ "ISignalName" SG_ 359 PICU_20ms_Group11_Reserved9 "IPICU_20ms_Group11_Reserved9";
BA_ "SysSignalName" SG_ 359 PICU_20ms_Group11_Reserved9 "PICU_20ms_Group11_Reserved9";
BA_ "CompuMethodName" SG_ 236 PICU_10ms_Group23_CRC "PICU_10ms_Group23_CRC";
BA_ "ISignalName" SG_ 236 PICU_10ms_Group23_CRC "IPICU_10ms_Group23_CRC";
BA_ "SysSignalName" SG_ 236 PICU_10ms_Group23_CRC "PICU_10ms_Group23_CRC";
BA_ "CompuMethodName" SG_ 236 PICU_10ms_Group23_RC "PICU_10ms_Group23_RC";
BA_ "ISignalName" SG_ 236 PICU_10ms_Group23_RC "IPICU_10ms_Group23_RC";
BA_ "SysSignalName" SG_ 236 PICU_10ms_Group23_RC "PICU_10ms_Group23_RC";
BA_ "CompuMethodName" SG_ 236 EnStCtrlA "EnStCtrlA";
BA_ "ISignalName" SG_ 236 EnStCtrlA "IEnStCtrlA";
BA_ "LongName" SG_ 236 EnStCtrlA "Engine Start Control Active";
BA_ "SysSignalName" SG_ 236 EnStCtrlA "EnStCtrlA";
BA_ "CompuMethodName" SG_ 236 EnFuelCutA "EnFuelCutA";
BA_ "ISignalName" SG_ 236 EnFuelCutA "IEnFuelCutA";
BA_ "LongName" SG_ 236 EnFuelCutA "Engine Fuel Cut Active";
BA_ "SysSignalName" SG_ 236 EnFuelCutA "EnFuelCutA";
BA_ "CompuMethodName" SG_ 236 HybEnStSpOvrd "HybEnStSpOvrd";
BA_ "ISignalName" SG_ 236 HybEnStSpOvrd "IHybEnStSpOvrd";
BA_ "LongName" SG_ 236 HybEnStSpOvrd "Hybrid Engine Start Stop Override";
BA_ "SysSignalName" SG_ 236 HybEnStSpOvrd "HybEnStSpOvrd";
BA_ "CompuMethodName" SG_ 236 HybEnSpdReqF "HybEnSpdReqF";
BA_ "ISignalName" SG_ 236 HybEnSpdReqF "IHybEnSpdReqF";
BA_ "LongName" SG_ 236 HybEnSpdReqF "Hybrid Engine Speed Request Failed";
BA_ "SysSignalName" SG_ 236 HybEnSpdReqF "HybEnSpdReqF";
BA_ "CompuMethodName" SG_ 236 EnDclFuelCutOffAld "EnDclFuelCutOffAld";
BA_ "ISignalName" SG_ 236 EnDclFuelCutOffAld "IEnDclFuelCutOffAld";
BA_ "LongName" SG_ 236 EnDclFuelCutOffAld "Engine Deceleration Fuel Cut Off Allowed";
BA_ "SysSignalName" SG_ 236 EnDclFuelCutOffAld "EnDclFuelCutOffAld";
BA_ "CompuMethodName" SG_ 236 PICU_10ms_Group23_Reserved18 "PICU_10ms_Group23_Reserved18";
BA_ "GenSigStartValue" SG_ 236 PICU_10ms_Group23_Reserved18 1;
BA_ "ISignalName" SG_ 236 PICU_10ms_Group23_Reserved18 "IPICU_10ms_Group23_Reserved18";
BA_ "SysSignalName" SG_ 236 PICU_10ms_Group23_Reserved18 "PICU_10ms_Group23_Reserved18";
BA_ "CompuMethodName" SG_ 236 RVSEnRunning "RVSEnRunning";
BA_ "ISignalName" SG_ 236 RVSEnRunning "IRVSEnRunning";
BA_ "LongName" SG_ 236 RVSEnRunning "Remote Vehicle Start Engine Running";
BA_ "SysSignalName" SG_ 236 RVSEnRunning "RVSEnRunning";
BA_ "CompuMethodName" SG_ 236 EnHybVehStaOvrd "EnHybVehStaOvrd";
BA_ "ISignalName" SG_ 236 EnHybVehStaOvrd "IEnHybVehStaOvrd";
BA_ "LongName" SG_ 236 EnHybVehStaOvrd "Engine Hybrid Vehicle State Override";
BA_ "SysSignalName" SG_ 236 EnHybVehStaOvrd "EnHybVehStaOvrd";
BA_ "CompuMethodName" SG_ 236 EnSynRdy "EnSynRdy";
BA_ "ISignalName" SG_ 236 EnSynRdy "IEnSynRdy";
BA_ "LongName" SG_ 236 EnSynRdy "Engine Synchronization Ready";
BA_ "SysSignalName" SG_ 236 EnSynRdy "EnSynRdy";
BA_ "CompuMethodName" SG_ 236 EnSysDsbld "EnSysDsbld";
BA_ "ISignalName" SG_ 236 EnSysDsbld "IEnSysDsbld";
BA_ "LongName" SG_ 236 EnSysDsbld "Engine System Disabled";
BA_ "SysSignalName" SG_ 236 EnSysDsbld "EnSysDsbld";
BA_ "CompuMethodName" SG_ 236 EnComFlrRducdPwrCmdd "EnComFlrRducdPwrCmdd";
BA_ "ISignalName" SG_ 236 EnComFlrRducdPwrCmdd "IEnComFlrRducdPwrCmdd";
BA_ "LongName" SG_ 236 EnComFlrRducdPwrCmdd "Engine Communication Failure Reduced Power Commanded";
BA_ "SysSignalName" SG_ 236 EnComFlrRducdPwrCmdd "EnComFlrRducdPwrCmdd";
BA_ "CompuMethodName" SG_ 236 PtACCA "PtACCA";
BA_ "ISignalName" SG_ 236 PtACCA "IPtACCA";
BA_ "LongName" SG_ 236 PtACCA "Powertrain Adaptive Cruise Control Active";
BA_ "SysSignalName" SG_ 236 PtACCA "PtACCA";
BA_ "CompuMethodName" SG_ 236 EnDclFuelCutOffReq "EnDclFuelCutOffReq";
BA_ "ISignalName" SG_ 236 EnDclFuelCutOffReq "IEnDclFuelCutOffReq";
BA_ "LongName" SG_ 236 EnDclFuelCutOffReq "Engine Deceleration Fuel Cut Off Request";
BA_ "SysSignalName" SG_ 236 EnDclFuelCutOffReq "EnDclFuelCutOffReq";
BA_ "CompuMethodName" SG_ 236 EnDclFuelCutOffSta "EnDclFuelCutOffSta";
BA_ "ISignalName" SG_ 236 EnDclFuelCutOffSta "IEnDclFuelCutOffSta";
BA_ "LongName" SG_ 236 EnDclFuelCutOffSta "Engine Deceleration Fuel Cut Off State";
BA_ "SysSignalName" SG_ 236 EnDclFuelCutOffSta "EnDclFuelCutOffSta";
BA_ "CompuMethodName" SG_ 236 EnIdleCtrlA "EnIdleCtrlA";
BA_ "ISignalName" SG_ 236 EnIdleCtrlA "IEnIdleCtrlA";
BA_ "LongName" SG_ 236 EnIdleCtrlA "Engine Idle Control Active";
BA_ "SysSignalName" SG_ 236 EnIdleCtrlA "EnIdleCtrlA";
BA_ "CompuMethodName" SG_ 236 EnIdleCtrlSts "EnIdleCtrlSts";
BA_ "ISignalName" SG_ 236 EnIdleCtrlSts "IEnIdleCtrlSts";
BA_ "LongName" SG_ 236 EnIdleCtrlSts "Engine Idle Control Status";
BA_ "SysSignalName" SG_ 236 EnIdleCtrlSts "EnIdleCtrlSts";
BA_ "CompuMethodName" SG_ 236 CrkshftNonTrRegdCmddToq "CrkshftNonTrRegdCmddToq";
BA_ "ISignalName" SG_ 236 CrkshftNonTrRegdCmddToq "ICrkshftNonTrRegdCmddToq";
BA_ "LongName" SG_ 236 CrkshftNonTrRegdCmddToq "Crankshaft Non Transmission Regulated Commanded Torque";
BA_ "SysSignalName" SG_ 236 CrkshftNonTrRegdCmddToq "CrkshftNonTrRegdCmddToq";
BA_ "CompuMethodName" SG_ 236 EnReqdStTyp "EnReqdStTyp";
BA_ "ISignalName" SG_ 236 EnReqdStTyp "IEnReqdStTyp";
BA_ "LongName" SG_ 236 EnReqdStTyp "Engine Requested Start Type";
BA_ "SysSignalName" SG_ 236 EnReqdStTyp "EnReqdStTyp";
BA_ "CompuMethodName" SG_ 236 EnFuelRcvrySpd "EnFuelRcvrySpd";
BA_ "ISignalName" SG_ 236 EnFuelRcvrySpd "IEnFuelRcvrySpd";
BA_ "LongName" SG_ 236 EnFuelRcvrySpd "Engine Fuel Recovery Speed";
BA_ "SysSignalName" SG_ 236 EnFuelRcvrySpd "EnFuelRcvrySpd";
BA_ "CompuMethodName" SG_ 777 RZCU_100ms_Group10_CRC "RZCU_100ms_Group10_CRC";
BA_ "ISignalName" SG_ 777 RZCU_100ms_Group10_CRC "IRZCU_100ms_Group10_CRC";
BA_ "LongName" SG_ 777 RZCU_100ms_Group10_CRC "RZCU_100ms_Group10_CRC";
BA_ "SysSignalName" SG_ 777 RZCU_100ms_Group10_CRC "RZCU_100ms_Group10_CRC";
BA_ "CompuMethodName" SG_ 777 RZCU_100ms_Group10_RC "RZCU_100ms_Group10_RC";
BA_ "ISignalName" SG_ 777 RZCU_100ms_Group10_RC "IRZCU_100ms_Group10_RC";
BA_ "LongName" SG_ 777 RZCU_100ms_Group10_RC "RZCU_100ms_Group10_RC";
BA_ "SysSignalName" SG_ 777 RZCU_100ms_Group10_RC "RZCU_100ms_Group10_RC";
BA_ "CompuMethodName" SG_ 777 RZCU_100ms_Group10_Reserved1 "RZCU_100ms_Group10_Reserved1";
BA_ "GenSigStartValue" SG_ 777 RZCU_100ms_Group10_Reserved1 3;
BA_ "ISignalName" SG_ 777 RZCU_100ms_Group10_Reserved1 "IRZCU_100ms_Group10_Reserved1";
BA_ "SysSignalName" SG_ 777 RZCU_100ms_Group10_Reserved1 "RZCU_100ms_Group10_Reserved1";
BA_ "CompuMethodName" SG_ 777 FlbStrgFnSts "FlbStrgFnSts";
BA_ "ISignalName" SG_ 777 FlbStrgFnSts "IFlbStrgFnSts";
BA_ "LongName" SG_ 777 FlbStrgFnSts "Flexible Steering Function Status";
BA_ "SysSignalName" SG_ 777 FlbStrgFnSts "FlbStrgFnSts";
BA_ "CompuMethodName" SG_ 777 OfbdChrgrNgtvSktTem "OfbdChrgrNgtvSktTem";
BA_ "GenSigStartValue" SG_ 777 OfbdChrgrNgtvSktTem 254;
BA_ "ISignalName" SG_ 777 OfbdChrgrNgtvSktTem "IOfbdChrgrNgtvSktTem";
BA_ "LongName" SG_ 777 OfbdChrgrNgtvSktTem "Offboard_Charger_Negative_Socket_Temperature";
BA_ "SysSignalName" SG_ 777 OfbdChrgrNgtvSktTem "OfbdChrgrNgtvSktTem";
BA_ "CompuMethodName" SG_ 777 OnBdChrgrSktPstvSnsrTem "OnBdChrgrSktPstvSnsrTem";
BA_ "ISignalName" SG_ 777 OnBdChrgrSktPstvSnsrTem "IOnBdChrgrSktPstvSnsrTem";
BA_ "LongName" SG_ 777 OnBdChrgrSktPstvSnsrTem "On_Board_Charger_Socket_Positive_Sensor_Temperature";
BA_ "SysSignalName" SG_ 777 OnBdChrgrSktPstvSnsrTem "OnBdChrgrSktPstvSnsrTem";
BA_ "CompuMethodName" SG_ 777 EleccLckCtrlResp "EleccLckCtrlResp";
BA_ "ISignalName" SG_ 777 EleccLckCtrlResp "IEleccLckCtrlResp";
BA_ "LongName" SG_ 777 EleccLckCtrlResp "Combined Charging Unit Electronic Lock Control Response";
BA_ "SysSignalName" SG_ 777 EleccLckCtrlResp "EleccLckCtrlResp";
BA_ "CompuMethodName" SG_ 777 OnbdChrgrSktEleccLckEnable "OnbdChrgrSktEleccLckEnable";
BA_ "ISignalName" SG_ 777 OnbdChrgrSktEleccLckEnable "IOnbdChrgrSktEleccLckEnable";
BA_ "LongName" SG_ 777 OnbdChrgrSktEleccLckEnable "Combined Charging Unit On oboard Charger Socket Electric Lock Enable";
BA_ "SysSignalName" SG_ 777 OnbdChrgrSktEleccLckEnable "OnbdChrgrSktEleccLckEnable";
BA_ "CompuMethodName" SG_ 777 OnBdChrgrSktPstvSnsrTemV "OnBdChrgrSktPstvSnsrTemV";
BA_ "GenSigStartValue" SG_ 777 OnBdChrgrSktPstvSnsrTemV 1;
BA_ "ISignalName" SG_ 777 OnBdChrgrSktPstvSnsrTemV "IOnBdChrgrSktPstvSnsrTemV";
BA_ "LongName" SG_ 777 OnBdChrgrSktPstvSnsrTemV "On_Board_Charger_Socket_Positive_Sensor_Temperature_Validity";
BA_ "SysSignalName" SG_ 777 OnBdChrgrSktPstvSnsrTemV "OnBdChrgrSktPstvSnsrTemV";
BA_ "CompuMethodName" SG_ 777 OfbdChrgrNgtvSktTemV "OfbdChrgrNgtvSktTemV";
BA_ "GenSigStartValue" SG_ 777 OfbdChrgrNgtvSktTemV 1;
BA_ "ISignalName" SG_ 777 OfbdChrgrNgtvSktTemV "IOfbdChrgrNgtvSktTemV";
BA_ "LongName" SG_ 777 OfbdChrgrNgtvSktTemV "Offboard_Charger_Negative_Socket_Temperature_Validity";
BA_ "SysSignalName" SG_ 777 OfbdChrgrNgtvSktTemV "OfbdChrgrNgtvSktTemV";
BA_ "CompuMethodName" SG_ 777 RZCU_100ms_Group10_Reserved2 "RZCU_100ms_Group10_Reserved2";
BA_ "GenSigStartValue" SG_ 777 RZCU_100ms_Group10_Reserved2 1;
BA_ "ISignalName" SG_ 777 RZCU_100ms_Group10_Reserved2 "IRZCU_100ms_Group10_Reserved2";
BA_ "SysSignalName" SG_ 777 RZCU_100ms_Group10_Reserved2 "RZCU_100ms_Group10_Reserved2";
BA_ "CompuMethodName" SG_ 777 RZCU_100ms_Group10_Reserved3 "RZCU_100ms_Group10_Reserved3";
BA_ "GenSigStartValue" SG_ 777 RZCU_100ms_Group10_Reserved3 127;
BA_ "ISignalName" SG_ 777 RZCU_100ms_Group10_Reserved3 "IRZCU_100ms_Group10_Reserved3";
BA_ "SysSignalName" SG_ 777 RZCU_100ms_Group10_Reserved3 "RZCU_100ms_Group10_Reserved3";
BA_ "CompuMethodName" SG_ 777 FlbStrgFnStsResp "FlbStrgFnStsResp";
BA_ "ISignalName" SG_ 777 FlbStrgFnStsResp "IFlbStrgFnStsResp";
BA_ "LongName" SG_ 777 FlbStrgFnStsResp "Flexible Steering Function Status Response";
BA_ "SysSignalName" SG_ 777 FlbStrgFnStsResp "FlbStrgFnStsResp";
BA_ "CompuMethodName" SG_ 777 RZCU_100ms_Group10_Reserved4 "RZCU_100ms_Group10_Reserved4";
BA_ "GenSigStartValue" SG_ 777 RZCU_100ms_Group10_Reserved4 15;
BA_ "ISignalName" SG_ 777 RZCU_100ms_Group10_Reserved4 "IRZCU_100ms_Group10_Reserved4";
BA_ "SysSignalName" SG_ 777 RZCU_100ms_Group10_Reserved4 "RZCU_100ms_Group10_Reserved4";
BA_ "CompuMethodName" SG_ 777 IMU_Signal_status "IMU_Signal_status";
BA_ "ISignalName" SG_ 777 IMU_Signal_status "IIMU_Signal_status";
BA_ "LongName" SG_ 777 IMU_Signal_status "IMU Signal status";
BA_ "SysSignalName" SG_ 777 IMU_Signal_status "IMU_Signal_status";
BA_ "CompuMethodName" SG_ 777 VCUCtrlS2Req "VCUCtrlS2Req";
BA_ "ISignalName" SG_ 777 VCUCtrlS2Req "IVCUCtrlS2Req";
BA_ "LongName" SG_ 777 VCUCtrlS2Req "Vehicle Control Unit Control S2 Request";
BA_ "SysSignalName" SG_ 777 VCUCtrlS2Req "VCUCtrlS2Req";
BA_ "CompuMethodName" SG_ 777 RZCU_100ms_Group10_Reserved5 "RZCU_100ms_Group10_Reserved5";
BA_ "GenSigStartValue" SG_ 777 RZCU_100ms_Group10_Reserved5 7;
BA_ "ISignalName" SG_ 777 RZCU_100ms_Group10_Reserved5 "IRZCU_100ms_Group10_Reserved5";
BA_ "SysSignalName" SG_ 777 RZCU_100ms_Group10_Reserved5 "RZCU_100ms_Group10_Reserved5";
BA_ "CompuMethodName" SG_ 777 OnBdChrgrSktElecLckStaV "OnBdChrgrSktElecLckStaV";
BA_ "GenSigStartValue" SG_ 777 OnBdChrgrSktElecLckStaV 1;
BA_ "ISignalName" SG_ 777 OnBdChrgrSktElecLckStaV "IOnBdChrgrSktElecLckStaV";
BA_ "LongName" SG_ 777 OnBdChrgrSktElecLckStaV "Combined Charging Unit On Board Charger Socket Electronic Lock State Validity";
BA_ "SysSignalName" SG_ 777 OnBdChrgrSktElecLckStaV "OnBdChrgrSktElecLckStaV";
BA_ "CompuMethodName" SG_ 777 OnBdChrgrSktElecLckSta "OnBdChrgrSktElecLckSta";
BA_ "ISignalName" SG_ 777 OnBdChrgrSktElecLckSta "IOnBdChrgrSktElecLckSta";
BA_ "LongName" SG_ 777 OnBdChrgrSktElecLckSta "Combined Charging Unit On Board Charger Socket Electric Lock Status";
BA_ "SysSignalName" SG_ 777 OnBdChrgrSktElecLckSta "OnBdChrgrSktElecLckSta";
VAL_ 351 APAVCUReqSts 0 "APAVCUReqSts_0_NoRequest" 1 "APAVCUReqSts_1_RequestSpeedControl" 2 "APAVCUReqSts_2_RequestTorqueControl" 3 "APAVCUReqSts_3_Active";
VAL_ 351 APARevrDrgReq 0 "APARevrDrgReq_0_NoRequest" 1 "APARevrDrgReq_1_RequestReverseDrag";
VAL_ 424 AutodDrvngSysStsV 0 "AutodDrvngSysStsV_0_Valid" 1 "AutodDrvngSysStsV_1_Invalid";
VAL_ 424 APASts 0 "APASts_0_Disable" 1 "APASts_1_Standby" 2 "APASts_2_Semi_apaActive" 3 "APASts_3_Fully_apaActive" 4 "APASts_4_Failed";
VAL_ 424 AutodDrvngSysSts 0 "AutodDrvngSysSts_CH_0_Off" 1 "AutodDrvngSysSts_CH_1_APA_Disable" 2 "AutodDrvngSysSts_CH_2_APA_Standby" 3 "AutodDrvngSysSts_CH_3_Semi_APA_Active" 4 "AutodDrvngSysSts_CH_4_Fully_APA_Active" 5 "AutodDrvngSysSts_CH_5_APA_Failed" 6 "AutodDrvngSysSts_CH_6_Automated_driving_system_Disable" 7 "AutodDrvngSysSts_CH_7_Automated_driving_system_Standby" 8 "AutodDrvngSysSts_CH_8_Automated_driving_system_Failed" 9 "AutodDrvngSysSts_CH_9_Automated_driving_system_active";
VAL_ 431 ACCDclReqSts 0 "ACCDclReqSts_0_No_Request" 1 "ACCDclReqSts_1_ACC_Deceleration_Request";
VAL_ 431 ACCOtptShaftTotToqReqSts 0 "ACCOtptShaftTotToqReqSts_0_NoRequest" 1 "ACCOtptShaftTotToqReqSts_1_TorqueRequest";
VAL_ 431 AutodDrvngSysStsPT 0 "AutodDrvngSysStsPT_0_Off" 1 "AutodDrvngSysStsPT_1_APA_Disable" 2 "AutodDrvngSysStsPT_2_APA_Standby" 3 "AutodDrvngSysStsPT_3_Semi_APA_Active" 4 "AutodDrvngSysStsPT_4_Fully_APA_Active" 5 "AutodDrvngSysStsPT_5_APA_Failed" 6 "AutodDrvngSysStsPT_6_Automated_driving_system_Disable" 7 "AutodDrvngSysStsPT_7_Automated_driving_system_Standby" 8 "AutodDrvngSysStsPT_8_Automated_driving_system_Failed" 9 "AutodDrvngSysStsPT_9_Automated_driving_system_active";
VAL_ 81 TJAICASysFltSts 0 "TJAICASysFltSts_0_noerror" 1 "TJAICASysFltSts_1_performancedegradation" 2 "TJAICASysFltSts_2_systemtemporaryunavailable" 3 "TJAICASysFltSts_3_servicerequired" 4 "TJAICASysFltSts_4_Reserved" 5 "TJAICASysFltSts_5_Reserved" 6 "TJAICASysFltSts_6_Reserved" 7 "TJAICASysFltSts_7_Reserved";
VAL_ 81 ACCToqReqSts 0 "ACCToqReqSts_0__No_request" 1 "ACCToqReqSts_1__Torque_request_request" 2 "ACCToqReqSts_2_Reserved1" 3 "ACCToqReqSts_3_Reserved2";
VAL_ 81 LKASysFltSts 0 "LKASysFltSts_0_noerror" 1 "LKASysFltSts_1_performancedegradation" 2 "LKASysFltSts_2_systemtemporaryunavailable" 3 "LKASysFltSts_3_servicerequired";
VAL_ 81 TJAICASysSts 0 "TJAICASysSts_0_Off" 1 "TJAICASysSts_1_Standby" 2 "TJAICASysSts_2_Active" 3 "TJAICASysSts_3_Override" 4 "TJAICASysSts_4_Passive" 5 "TJAICASysSts_5_Degradation" 6 "TJAICASysSts_6_SafeStop" 7 "TJAICASysSts_7_Prohibition";
VAL_ 81 LKASysSts 0 "LKASysSts_0_Off" 1 "LKASysSts_1_Standby" 2 "LKASysSts_2_Active" 3 "LKASysSts_3_Override" 4 "LKASysSts_4_Active_no_warning";
VAL_ 1329 LghtWlcmMdReq 0 "LghtWlcmMdReq_0_No_Request" 1 "LghtWlcmMdReq_1__Mode_1" 2 "LghtWlcmMdReq_2__Mode_2" 3 "LghtWlcmMdReq_3__Mode_3" 4 "LghtWlcmMdReq_4__Mode_4" 5 "LghtWlcmMdReq_5__Mode_5" 6 "LghtWlcmMdReq_6__Mode_6" 7 "LghtWlcmMdReq_7__Mode_7" 8 "LghtWlcmMdReq_8__Mode_8" 9 "LghtWlcmMdReq_9__Mode_9" 10 "LghtWlcmMdReq_10__Mode_10" 11 "LghtWlcmMdReq_11__Mode_11" 12 "LghtWlcmMdReq_12__Mode_12" 13 "LghtWlcmMdReq_13__Mode_13" 14 "LghtWlcmMdReq_14__Mode_14" 15 "LghtWlcmMdReq_15__Mode_15";
VAL_ 1329 AvgFuelCsumpPrcsV 0 "AvgFuelCsumpPrcsV_0_Valid" 1 "AvgFuelCsumpPrcsV_1_Invalid";
VAL_ 1329 AvgFuelCsumpV 0 "AvgFuelCsumpV_0_Valid" 1 "AvgFuelCsumpV_1_Invalid";
VAL_ 1329 IgnOffTimeV 0 "IgnOffTimeV_0_Valid" 1 "IgnOffTimeV_1_Invalid";
VAL_ 1329 RCPDMdSwReq 0 "RCPDMdSwReq_0_No_Request" 1 "RCPDMdSwReq_1_On" 2 "RCPDMdSwReq_2_Off" 3 "RCPDMdSwReq_3_Reserved";
VAL_ 1329 RCPDDlyTimeSwReq 0 "RCPDDlyTimeSwReq_0_No_Delay" 1 "Delay_5_Minutes" 2 "Delay_9_Minutes" 3 "RCPDDlyTimeSwReq_3_Reserved" 4 "RCPDDlyTimeSwReq_4_Reserved" 5 "RCPDDlyTimeSwReq_5_Reserved" 6 "RCPDDlyTimeSwReq_6_Reserved" 7 "RCPDDlyTimeSwReq_7_Reserved";
VAL_ 1023 RgnLvReqFICMV 0 "RgnLvReqFICMV_0_Valid" 1 "RgnLvReqFICMV_1_Invalid";
VAL_ 1023 RgnLvReqFICM 0 "RgnLvReqFICM_0_Low" 1 "RgnLvReqFICM_1_standard" 2 "RgnLvReqFICM_2_high" 3 "RgnLvReqFICM_3_auto" 4 "RgnLvReqFICM_4_regen_limited" 5 "RgnLvReqFICM_5_Off" 6 "RgnLvReqFICM_6_reserved" 7 "RgnLvReqFICM_7_reserved";
VAL_ 1023 LVBatChrgReqRaw 0 "LVBatChrgReqRaw_0_False" 1 "LVBatChrgReqRaw_1_True";
VAL_ 1023 LVBatChrgReqInhbt 0 "LVBatChrgReqInhbt_0_False" 1 "LVBatChrgReqInhbt_1_True";
VAL_ 1023 LVBatEnrgSufct 0 "LVBatEnrgSufct_0_False" 1 "LVBatEnrgSufct_1_True";
VAL_ 1023 LVBatEnrgLow 0 "LVBatEnrgLow_0_False" 1 "LVBatEnrgLow_1_True";
VAL_ 1023 EnrgSplReqV 0 "EnrgSplReqV_0_Valid" 1 "EnrgSplReqV_1_Invalid";
VAL_ 1023 EnrgSplReq 0 "EnrgSplReq_0_False" 1 "EnrgSplReq_1_True";
VAL_ 1023 PMDCSta 0 "PMDCSta_0_No_Error" 1 "PMDCSta_1_Communication_Error" 2 "PMDCSta_2_LV_System_Error";
VAL_ 1023 VehEnrgRdyLvlV 0 "VehEnrgRdyLvlV_0_Valid" 1 "VehEnrgRdyLvlV_1_Invalid";
VAL_ 1023 VehEnrgRdyLvl 0 "VehEnrgRdyLvl_0_Level0" 1 "VehEnrgRdyLvl_1_Level1" 2 "VehEnrgRdyLvl_2_Level2" 3 "VehEnrgRdyLvl_3_Level3" 4 "VehEnrgRdyLvl_4_Level4" 5 "VehEnrgRdyLvl_5_Level5" 6 "VehEnrgRdyLvl_6_Level6" 7 "VehEnrgRdyLvl_7_Level7";
VAL_ 1023 LVBMDisChrgMOSCtrl 0 "LVBMDisChrgMOSCtrl_0_Norequest" 1 "LVBMDisChrgMOSCtrl_1_Open";
VAL_ 1023 AuxBatUnAssembled 0 "AuxBatUnAssembled_0_False" 1 "AuxBatUnAssembled_1_True";
VAL_ 1023 EPTToqCustSetngReqV 0 "EPTToqCustSetngReqV_0_Valid" 1 "EPTToqCustSetngReqV_1_Invalid";
VAL_ 1023 EPTToqCustSetngReq 0 "EPTToqCustSetngReq_0_Unavailable" 1 "EPTToqCustSetngReq_1_EcoMode" 2 "EPTToqCustSetngReq_2_NormalMode" 3 "EPTToqCustSetngReq_3_SportMode";
VAL_ 1023 LVBatSelfWakeupFlg 0 "LVBatSelfWakeupFlg_0_False" 1 "LVBatSelfWakeupFlg_1_True";
VAL_ 1023 EnrgSplReqRaw 0 "EnrgSplReqRaw_0_False" 1 "EnrgSplReqRaw_1_True";
VAL_ 486 FrtCarGoNotfr 0 "FrtCarGoNotfr_0_False" 1 "FrtCarGoNotfr_1_Waminglevel1" 2 "FrtCarGoNotfr_2_Warninglevel2" 3 "FrtCarGoNotfr_3_Warninglevel3";
VAL_ 486 ACCSysFltSts_SCS 0 "ACCSysFltSts_SCS_0_NoError" 1 "ACCSysFltSts_SCS_1_PerformanceDegradation" 2 "ACCSysFltSts_SCS_2_SystemTemporaryUnvailable" 3 "ACCSysFltSts_SCS_3_ServiceRequired" 4 "ACCSysFltSts_SCS_4_Reserved" 5 "ACCSysFltSts_SCS_5_Reserved" 6 "ACCSysFltSts_SCS_6_Reserved" 7 "ACCSysFltSts_SCS_7_Reserved";
VAL_ 733 KeepPwrRsnIPD 0 "KeepPwrRsnIPD_0_Unknown" 1 "KeepPwrRsnIPD_1_Off" 2 "KeepPwrRsnIPD_2_On" 3 "KeepPwrRsnIPD_3__LPM_SnsrOff" 4 "KeepPwrRsnIPD_4_SnsrOff" 5 "KeepPwrRsnIPD_5_Reserved" 6 "KeepPwrRsnIPD_6_Reserved" 7 "KeepPwrRsnIPD_7_Reserved" 8 "KeepPwrRsnIPD_8_Reserved" 9 "KeepPwrRsnIPD_9_GoingDown" 10 "KeepPwrRsnIPD_10_off_SuperECO" 11 "KeepPwrRsnIPD_11_Reserved" 12 "KeepPwrRsnIPD_12_Reserved" 13 "KeepPwrRsnIPD_13_Reserved" 14 "KeepPwrRsnIPD_14_Reserved" 15 "KeepPwrRsnIPD_15_Reserved";
VAL_ 733 SysPwrMdCtrl 0 "SysPwrMdCtrl_0_NoRequest" 1 "SysPwrMdCtrl_1_Accessory" 2 "SysPwrMdCtrl_2_Run" 3 "SysPwrMdCtrl_3_Crank_Request" 4 "SysPwrMdCtrl_4_Change_to_normal_mode" 5 "SysPwrMdCtrl_5_Change_to_AD_mode" 6 "SysPwrMdCtrl_6_OFF";
VAL_ 733 APAEnRunReq 0 "APAEnRunReq_0_No_request" 1 "APAEnRunReq_1_Request";
VAL_ 733 LADSAFnInd 0 "LADSAFnInd_0_IDLE" 1 "LADSAFnInd_1_RADS" 2 "LADSAFnInd_2_ESSSwap_Park" 3 "LADSAFnInd_3_NPA" 4 "LADSAFnInd_4_AVP" 5 "LADSAFnInd_5_Remember_Build_Map" 6 "LADSAFnInd_6_Remember_Summon" 7 "LADSAFnInd_7_Remember_ParkIn" 8 "LADSAFnInd_8_RemoteOnekeyParkIn_Super" 9 "LADSAFnInd_9_ParkIn_super" 10 "LADSAFnInd_10_ParkIn" 11 "LADSAFnInd_11_ParkOut" 12 "LADSAFnInd_12_NRCD" 13 "LADSAFnInd_13_RemoteOnekeyParkIn" 14 "LADSAFnInd_14_RemoteOnekeyParkOut" 15 "LADSAFnInd_15_NCP";
VAL_ 982 ACCDetObjRisk 0 "ACCDetObjRisk_0_NoRisk" 1 "ACCDetObjRisk_1_RiskExist";
VAL_ 982 ACCDetObjTyp 0 "ACCDetObjTyp_0_Unknown" 1 "ACCDetObjTyp_1_Car" 2 "ACCDetObjTyp_2_Truck" 3 "ACCDetObjTyp_3_Motorbike" 4 "ACCDetObjTyp_4_Bicycle" 5 "ACCDetObjTyp_5_Reserved" 6 "ACCDetObjTyp_6_Reserved" 7 "ACCDetObjTyp_7_Reserved";
VAL_ 478 APASCSDrvrReqSts 0 "APASCSDrvrReqSts_0_No_Request" 1 "APASCSDrvrReqSts_1_Requested";
VAL_ 478 APASCSBrkFn 0 "APASCSBrkFn_0_No_Action" 1 "APASCSBrkFn_1_Reserved" 2 "APASCSBrkFn_2_Reserved" 3 "APASCSBrkFn_3_AutomaticPark" 4 "APASCSBrkFn_4_Remote_Park" 5 "APASCSBrkFn_5_Inside_P_to_P" 6 "APASCSBrkFn_6_Outside_P_to_P" 7 "APASCSBrkFn_7_Reserved";
VAL_ 478 APAEnToqReqSts 0 "APAEnToqReqSts_0_norequest" 1 "APAEnToqReqSts_1_enginetorquerequest";
VAL_ 478 APASCSParkngPrflReq 0 "APASCSParkngPrflReq_0_No_Request" 1 "APASCSParkngPrflReq_1_Requested";
VAL_ 478 APASCSReqSts 0 "APASCSReqSts_0_No_Action" 1 "APASCSReqSts_1_Standby" 2 "APASCSReqSts_2_Active_APA" 3 "APASCSReqSts_3_ManeuverFinished" 4 "APASCSReqSts_4_Suspend" 5 "APASCSReqSts_5_Abort" 6 "APASCSReqSts_6_Active_RPA" 7 "APASCSReqSts_7_Reserved";
VAL_ 478 APASCSBrkFnMd 0 "APASCSBrkFnMd_0_Idle_No_Braking" 1 "APASCSBrkFnMd_1_Comfortable" 2 "APASCSBrkFnMd_2_Emergency" 3 "APASCSBrkFnMd_3_Reserved";
VAL_ 176 ADS_SpdAstSysTrgtSpdV 0 "ADS_SpdAstSysTrgtSpdV_0_False" 1 "ADS_SpdAstSysTrgtSpdV_1_True";
VAL_ 1202 IPD_NM_BSMtoRMS_PTCANFD 0 "IPD_NM_BSMtoRMS_PTCANFD_0_IPD_NM_BSMtoRMS_0_False" 1 "IPD_NM_BSMtoRMS_PTCANFD_1_IPD_NM_BSMtoRMS_1_True";
VAL_ 1202 IPD_NM_PBSMtoRMS_PTCANFD 0 "IPD_NM_PBSMtoRMS_PTCANFD_0_IPD_NM_PBSMtoRMS_0_False" 1 "IPD_NM_PBSMtoRMS_PTCANFD_1_IPD_NM_PBSMtoRMS_1_True";
VAL_ 1202 IPD_NM_RMStoNOS_PTCANFD 0 "IPD_NM_RMStoNOS_PTCANFD_0_IPD_NM_RMStoNOS_0_False" 1 "IPD_NM_RMStoNOS_PTCANFD_1_IPD_NM_RMStoNOS_1_True";
VAL_ 1202 IPD_NM_RSStoNOS_PTCANFD 0 "IPD_NM_RSStoNOS_PTCANFD_0_IPD_NM_RSStoNOS_0_False" 1 "IPD_NM_RSStoNOS_PTCANFD_1_IPD_NM_RSStoNOS_1_True";
VAL_ 1202 IPD_NM_RSStoRMS_PTCANFD 0 "IPD_NM_RSStoRMS_PTCANFD_0_IPD_NM_RSStoRMS_0_False" 1 "IPD_NM_RSStoRMS_PTCANFD_1_IPD_NM_RSStoRMS_1_True";
VAL_ 1202 IPD_NM_NOStoRMS_PTCANFD 0 "IPD_NM_NOStoRMS_PTCANFD_0_IPD_NM_NOStoRMS_0_False" 1 "IPD_NM_NOStoRMS_PTCANFD_1_IPD_NM_NOStoRMS_1_True";
VAL_ 1202 IPD_NM_NOSSta_PTCANFD 0 "IPD_NM_NOSSta_PTCANFD_0_IPD_NM_NOSSta_0_False" 1 "IPD_NM_NOSSta_PTCANFD_1_IPD_NM_NOSSta_1_True";
VAL_ 1202 IPD_NM_RMSSta_PTCANFD 0 "IPD_NM_RMSSta_PTCANFD_0_IPD_NM_RMSSta_0_False" 1 "IPD_NM_RMSSta_PTCANFD_1_IPD_NM_RMSSta_1_True";
VAL_ 1202 IPD_NWI_PTCANFD 0 "IPD_NWI_PTCANFD_0_NoWakeNetworkSource" 1 "IPD_NWI_PTCANFD_1_PowerModeIsNonOFF" 2 "IPD_NWI_PTCANFD_2_OnboardChargerConnected";
VAL_ 1202 IPD_NOI_PTCANFD 0 "IPD_NOI_PTCANFD_0_NoRequest" 65535 "IPD_NOI_PTCANFD_65535_AllNetworkOperationActive";
VAL_ 1202 IPD_NKI_PTCANFD 0 "IPD_NKI_PTCANFD_0_NoRequest" 1 "IPD_NKI_PTCANFD_1_PowerModeIsNonOFF" 2 "IPD_NKI_PTCANFD_2_DOW" 3 "IPD_NKI_PTCANFD_3_RPA";
VAL_ 1168 LVBM_NM_BSMtoRMS_PTCANFD 0 "LVBM_NM_BSMtoRMS_PTCANFD_0_False" 1 "LVBM_NM_BSMtoRMS_PTCANFD_1_True";
VAL_ 1168 LVBM_NM_PBSMtoRMS_PTCANFD 0 "LVBM_NM_PBSMtoRMS_PTCANFD_0_False" 1 "LVBM_NM_PBSMtoRMS_PTCANFD_1_True";
VAL_ 1168 LVBM_NM_RMStoNOS_PTCANFD 0 "LVBM_NM_RMStoNOS_PTCANFD_0_False" 1 "LVBM_NM_RMStoNOS_PTCANFD_1_True";
VAL_ 1168 LVBM_NM_RSStoNOS_PTCANFD 0 "LVBM_NM_RSStoNOS_PTCANFD_0_False" 1 "LVBM_NM_RSStoNOS_PTCANFD_1_True";
VAL_ 1168 LVBM_NM_RSStoRMS_PTCANFD 0 "LVBM_NM_RSStoRMS_PTCANFD_0_False" 1 "LVBM_NM_RSStoRMS_PTCANFD_1_True";
VAL_ 1168 LVBM_NM_NOStoRMS_PTCANFD 0 "LVBM_NM_NOStoRMS_PTCANFD_0_False" 1 "LVBM_NM_NOStoRMS_PTCANFD_1_True";
VAL_ 1168 LVBM_NM_NOSSta_PTCANFD 0 "LVBM_NM_NOSSta_PTCANFD_0_False" 1 "LVBM_NM_NOSSta_PTCANFD_1_True";
VAL_ 1168 LVBM_NM_RMSSta_PTCANFD 0 "LVBM_NM_RMSSta_PTCANFD_0_False" 1 "LVBM_NM_RMSSta_PTCANFD_1_True";
VAL_ 1168 LVBM_NWI_PTCANFD 0 "LVBM_NWI_PTCANFD_0_NoWakeNetworkSource" 1 "LVBM_NWI_PTCANFD_1_PowerModeIsRun_crank" 2 "LVBM_NWI_PTCANFD_2_LowSOCWakeup" 3 "LVBM_NWI_PTCANFD_3_ThermalRunawayWakeup" 4 "LVBM_NWI_PTCANFD_4_lowPowerMd";
VAL_ 1168 LVBM_NOI_PTCANFD 0 "LVBM_NOI_PTCANFD_0_NoRequest" 65535 "LVBM_NOI_PTCANFD_65535_AllNetworkOperationActive";
VAL_ 1168 LVBM_NKI_PTCANFD 0 "LVBM_NKI_PTCANFD_0_NoRequest" 1 "LVBM_NKI_PTCANFD_1_PowerModeIsNonOFF" 2 "LVBM_NKI_PTCANFD_2_LowPowerMode" 4 "LVBM_NKI_PTCANFD_4_ThermalRunaway";
VAL_ 1266 MMCU_NM_BSMtoRMS_PTCANFD 0 "MMCU_NM_BSMtoRMS_PTCANFD_0_False" 1 "MMCU_NM_BSMtoRMS_PTCANFD_1_True";
VAL_ 1266 MMCU_NM_PBSMtoRMS_PTCANFD 0 "MMCU_NM_PBSMtoRMS_PTCANFD_0_False" 1 "MMCU_NM_PBSMtoRMS_PTCANFD_1_True";
VAL_ 1266 MMCU_NM_RMStoNOS_PTCANFD 0 "MMCU_NM_RMStoNOS_PTCANFD_0_False" 1 "MMCU_NM_RMStoNOS_PTCANFD_1_True";
VAL_ 1266 MMCU_NM_RSStoNOS_PTCANFD 0 "MMCU_NM_RSStoNOS_PTCANFD_0_False" 1 "MMCU_NM_RSStoNOS_PTCANFD_1_True";
VAL_ 1266 MMCU_NM_RSStoRMS_PTCANFD 0 "MMCU_NM_RSStoRMS_PTCANFD_0_False" 1 "MMCU_NM_RSStoRMS_PTCANFD_1_True";
VAL_ 1266 MMCU_NM_NOStoRMS_PTCANFD 0 "MMCU_NM_NOStoRMS_PTCANFD_0_False" 1 "MMCU_NM_NOStoRMS_PTCANFD_1_True";
VAL_ 1266 MMCU_NM_NOSSta_PTCANFD 0 "MMCU_NM_NOSSta_PTCANFD_0_False" 1 "MMCU_NM_NOSSta_PTCANFD_1_True";
VAL_ 1266 MMCU_NM_RMSSta_PTCANFD 0 "MMCU_NM_RMSSta_PTCANFD_0_False" 1 "MMCU_NM_RMSSta_PTCANFD_1_True";
VAL_ 1266 MMCU_NWI_PTCANFD 0 "MMCU_NWI_PTCANFD_0_NoWakeNetworkSource" 1 "MMCU_NWI_PTCANFD_1_PowerModeIsNonOFF";
VAL_ 1266 MMCU_NOI_PTCANFD 0 "MMCU_NOI_PTCANFD_0_NoRequest" 65535 "MMCU_NOI_PTCANFD_65535_AllNetworkOperationActive";
VAL_ 1266 MMCU_NKI_PTCANFD 0 "MMCU_NKI_PTCANFD_0_NoRequest" 1 "MMCU_NKI_PTCANFD_1_PowerModeIsNonOFF" 2 "MMCU_NKI_PTCANFD_2_EOPCAfterrun";
VAL_ 153 PEUMotBSpdSts 0 "PEUMotBSpdSts_0_Speed_Normal" 1 "PEUMotBSpdSts_1_Speed_Degraded" 2 "PEUMotBSpdSts_2_Speed_Backup_Source" 3 "PEUMotBSpdSts_3_Speed_Unusable";
VAL_ 153 PEUMotASpdSts 0 "PEUMotASpdSts_0_Speed_Normal" 1 "PEUMotASpdSts_1_Speed_Degraded" 2 "PEUMotASpdSts_2_Speed_Backup_Source" 3 "PEUMotASpdSts_3_Speed_Unusable";
VAL_ 153 PEUMotASpdV 0 "PEUMotASpdV_0_Valid" 1 "PEUMotASpdV_1_Invalid";
VAL_ 153 ReAxleMaxAvlblWhlRgtnTqV 0 "ReAxleMaxAvlblWhlRgtnTqV_0_Valid" 1 "ReAxleMaxAvlblWhlRgtnTqV_1_Invalid";
VAL_ 153 ReAxleMaxAvlblWhlDrvTqV 0 "ReAxleMaxAvlblWhlDrvTqV_0_Valid" 1 "ReAxleMaxAvlblWhlDrvTqV_1_Invalid";
VAL_ 153 PEUMotBToqAchV 0 "PEUMotBToqAchV_0_Valid" 1 "PEUMotBToqAchV_1_Invalid";
VAL_ 153 PEUMotBSpdV 0 "PEUMotBSpdV_0_Valid" 1 "PEUMotBSpdV_1_Invalid";
VAL_ 153 PEUMotAToqAchV 0 "PEUMotAToqAchV_0_Valid" 1 "PEUMotAToqAchV_1_Invalid";
VAL_ 153 PEUMotBMdAch 0 "PEUMotBMdAch_0_None" 1 "PEUMotBMdAch_1_Torque" 2 "PEUMotBMdAch_2_Speed" 3 "PEUMotBMdAch_3_Voltage";
VAL_ 153 PEUMotAMdAch 0 "PEUMotAMdAch_0_None" 1 "PEUMotAMdAch_1_Torque" 2 "PEUMotAMdAch_2_Speed" 3 "PEUMotAMdAch_3_Voltage";
VAL_ 1170 PEU_NM_BSMtoRMS_PTCANFD 0 "PEU_NM_BSMtoRMS_PTCANFD_0_False" 1 "PEU_NM_BSMtoRMS_PTCANFD_1_True";
VAL_ 1170 PEU_NM_PBSMtoRMS_PTCANFD 0 "PEU_NM_PBSMtoRMS_PTCANFD_0_False" 1 "PEU_NM_PBSMtoRMS_PTCANFD_1_True";
VAL_ 1170 PEU_NM_RMStoNOS_PTCANFD 0 "PEU_NM_RMStoNOS_PTCANFD_0_False" 1 "PEU_NM_RMStoNOS_PTCANFD_1_True";
VAL_ 1170 PEU_NM_RSStoNOS_PTCANFD 0 "PEU_NM_RSStoNOS_PTCANFD_0_False" 1 "PEU_NM_RSStoNOS_PTCANFD_1_True";
VAL_ 1170 PEU_NM_RSStoRMS_PTCANFD 0 "PEU_NM_RSStoRMS_PTCANFD_0_False" 1 "PEU_NM_RSStoRMS_PTCANFD_1_True";
VAL_ 1170 PEU_NM_NOStoRMS_PTCANFD 0 "PEU_NM_NOStoRMS_PTCANFD_0_False" 1 "PEU_NM_NOStoRMS_PTCANFD_1_True";
VAL_ 1170 PEU_NM_NOSSta_PTCANFD 0 "PEU_NM_NOSSta_PTCANFD_0_False" 1 "PEU_NM_NOSSta_PTCANFD_1_True";
VAL_ 1170 PEU_NM_RMSSta_PTCANFD 0 "PEU_NM_RMSSta_PTCANFD_0_False" 1 "PEU_NM_RMSSta_PTCANFD_1_True";
VAL_ 1170 PEU_NWI_PTCANFD 0 "PEU_NWI_PTCANFD_0_NoWakeNetworkSource" 1 "PEU_NWI_PTCANFD_1_PowerModeIsNonOFF";
VAL_ 1170 PEU_NOI_PTCANFD 0 "PEU_NOI_PTCANFD_0_NoRequest" 65535 "PEU_NOI_PTCANFD_65535_AllNetworkOperationActive";
VAL_ 1170 PEU_NKI_PTCANFD 0 "PEU_NKI_PTCANFD_0_NoRequest" 1 "PEU_NKI_PTCANFD_1_PowerModeIsNonOFF" 2 "PEU_NKI_PTCANFD_2_ThermalFaultActive" 4 "PEU_NKI_PTCANFD_4_Refuel" 16 "PEU_NKI_PTCANFD_16_HVBulid";
VAL_ 714 AGSModestatus2 0 "AGSModestatus2_0_normal_mode" 1 "AGSModestatus2_1_error_mode" 2 "AGSModestatus2_2_sleep_mode" 3 "AGSModestatus2_3_Reserved";
VAL_ 714 AGSModestatus1 0 "AGSModestatus1_0_normal_mode" 1 "AGSModestatus1_1_error_mode" 2 "AGSModestatus1_2_sleep_mode" 3 "AGSModestatus1_3_Reserved";
VAL_ 714 AGS1FltRsn 0 "AGS1FltRsn_0_normal" 1 "AGS1FltRsn_1_AGSMotorTemperatureSensorFault1" 2 "AGS1FltRsn_2_AGSMotorVoltageSensorFault1" 4 "AGS1FltRsn_4_AGSMotorCurrentSensorFault1" 8 "AGS1FltRsn_8_AGSMotorOverheat1" 16 "AGS1FltRsn_16_AGSMotorShortToGround1" 32 "AGS1FltRsn_32_AGSMotorShortToBattery1" 64 "AGS1FltRsn_64_AGSMotorElectronicFault1" 128 "AGS1FltRsn_128_AGSMechanicalBreakError1" 256 "AGS1FltRsn_256_AGSMechanicalblockError1" 512 "AGS1FltRsn_512_AGSControlTimeoutFault1" 1024 "AGS1FltRsn_1024_AGSMotorOverSpeed1" 2048 "AGS1FltRsn_2048_AGSMotorOverCurrent1";
VAL_ 714 AGS2FltRsn 0 "AGS2FltRsn_0_normal" 1 "AGS2FltRsn_1_AGSMotorTemperatureSensorFault2" 2 "AGS2FltRsn_2_AGSMotorVoltageSensorFault2" 4 "AGS2FltRsn_4_AGSMotorCurrentSensorFault2" 8 "AGS2FltRsn_8_AGSMotorOverheat2" 16 "AGS2FltRsn_16_AGSMotorShortToGround2" 32 "AGS2FltRsn_32_AGSMotorShortToBattery2" 64 "AGS2FltRsn_64_AGSMotorElectronicFault2" 128 "AGS2FltRsn_128_AGSMechanicalBreakError2" 256 "AGS2FltRsn_256_AGSMechanicalblockError2" 512 "AGS2FltRsn_512_AGSControlTimeoutFault2" 1024 "AGS2FltRsn_1024_AGSMotorOverSpeed2" 2048 "AGS2FltRsn_2048_AGSMotorOverCurrent2";
VAL_ 714 EPTElecWtrPumpActuSpd 255 "EPTElecWtrPumpActuSpd_255_invalid";
VAL_ 714 ESSElecWtrPumpActuSpd 255 "ESSElecWtrPumpActuSpd_255_invalid";
VAL_ 714 AGSTorqueResponse2 0 "AGSTorqueResponse2_0_normal_torque_level" 1 "AGSTorqueResponse2_1_Boost_mode_torque_level_1" 2 "AGSTorqueResponse2_2_Boost_mode_torque_level_2" 3 "AGSTorqueResponse2_3_reserved";
VAL_ 714 AGSTorqueResponse1 0 "AGSTorqueResponse1_0_normal_torque_level" 1 "AGSTorqueResponse1_1_Boost_mode_torque_level_1" 2 "AGSTorqueResponse1_2_Boost_mode_torque_level_2" 3 "AGSTorqueResponse1_3_reserved";
VAL_ 714 AGSSelflearnStatus2 0 "AGSSelflearnStatus2_0_successful" 1 "AGSSelflearnStatus2_1_self_learning" 2 "AGSSelflearnStatus2_2_failed" 3 "AGSSelflearnStatus2_3_reserved";
VAL_ 714 AGSSelflearnStatus1 0 "AGSSelflearnStatus1_0_successful" 1 "AGSSelflearnStatus1_1_self_learning" 2 "AGSSelflearnStatus1_2_failed" 3 "AGSSelflearnStatus1_3_reserved";
VAL_ 714 OBMLifeTimeParmFromEsMaxLmt 0 "OBMLifeTimeParmFromEsMaxLmt_0_not_reached_the_max_value" 1 "OBMLifeTimeParmFromEsMaxLmt_1_reached_the_max_value";
VAL_ 714 EndSocTrgtHCUV 0 "EndSocTrgtHCUV_0_Valid" 1 "EndSocTrgtHCUV_1_Invalid";
VAL_ 714 AISocMngtActv 0 "AISocMngtActv_0_Flase" 1 "AISocMngtActv_1_True";
VAL_ 714 TrgtSOCUpdtReq 0 "TrgtSOCUpdtReq_0_Flase" 1 "TrgtSOCUpdtReq_1_True";
VAL_ 714 WCACThrWayVlvActuPosV 0 "WCACThrWayVlvActuPosV_0_0_Valid" 1 "WCACThrWayVlvActuPosV_1_1_Invalid";
VAL_ 714 EDUClntTemV 0 "EDUClntTemV_0_Valid" 1 "EDUClntTemV_1_Invalid";
VAL_ 714 AGSMoveStatus2 0 "AGSMoveStatus2_0_motor_is_idle" 1 "AGSMoveStatus2_1_motor_is_moving";
VAL_ 714 AGSMoveStatus1 0 "AGSMoveStatus1_0_motor_is_idle" 1 "AGSMoveStatus1_1_motor_is_moving";
VAL_ 1196 PICM_NM_BSMtoRMS_PTCANFD 0 "PICM_NM_BSMtoRMS_PTCANFD_0_False" 1 "PICM_NM_BSMtoRMS_PTCANFD_1_True";
VAL_ 1196 PICM_NM_PBSMtoRMS_PTCANFD 0 "PICM_NM_PBSMtoRMS_PTCANFD_0_False" 1 "PICM_NM_PBSMtoRMS_PTCANFD_1_True";
VAL_ 1196 PICM_NM_RMStoNOS_PTCANFD 0 "PICM_NM_RMStoNOS_PTCANFD_0_False" 1 "PICM_NM_RMStoNOS_PTCANFD_1_True";
VAL_ 1196 PICM_NM_RSStoNOS_PTCANFD 0 "PICM_NM_RSStoNOS_PTCANFD_0_False" 1 "PICM_NM_RSStoNOS_PTCANFD_1_True";
VAL_ 1196 PICM_NM_RSStoRMS_PTCANFD 0 "PICM_NM_RSStoRMS_PTCANFD_0_False" 1 "PICM_NM_RSStoRMS_PTCANFD_1_True";
VAL_ 1196 PICM_NM_NOStoRMS_PTCANFD 0 "PICM_NM_NOStoRMS_PTCANFD_0_False" 1 "PICM_NM_NOStoRMS_PTCANFD_1_True";
VAL_ 1196 PICM_NM_NOSSta_PTCANFD 0 "PICM_NM_NOSSta_PTCANFD_0_False" 1 "PICM_NM_NOSSta_PTCANFD_1_True";
VAL_ 1196 PICM_NM_RMSSta_PTCANFD 0 "PICM_NM_RMSSta_PTCANFD_0_False" 1 "PICM_NM_RMSSta_PTCANFD_1_True";
VAL_ 1196 PICM_NWI_PTCANFD 0 "PICM_NWI_PTCANFD_0_NoWakeNetworkSource" 1 "PICM_NWI_PTCANFD_1_PowerModeIsNonOFF";
VAL_ 1196 PICM_NOI_PTCANFD 0 "PICM_NOI_PTCANFD_0_NoRequest" 65535 "PICM_NOI_PTCANFD_65535_AllNetworkOperationActive";
VAL_ 1196 PICM_NKI_PTCANFD 0 "PICM_NKI_PTCANFD_0_NoRequest" 1 "PICM_NKI_PTCANFD_1_PowerModeIsNonOFF" 2 "PICM_NKI_PTCANFD_2_ThermalFaultActive" 4 "PICM_NKI_PTCANFD_4_Refuel" 16 "PICM_NKI_PTCANFD_16_HVBulid";
VAL_ 140 FrtAxleActuWhlToqV 0 "FrtAxleActuWhlToqV_0_Valid" 1 "FrtAxleActuWhlToqV_1_Invalid";
VAL_ 140 DrvrReqRrAxleWhlToqV 0 "DrvrReqRrAxleWhlToqV_0_Valid" 1 "DrvrReqRrAxleWhlToqV_1_Invalid";
VAL_ 140 DrvrReqFrtAxleWhlToqV 0 "DrvrReqFrtAxleWhlToqV_0_Valid" 1 "DrvrReqFrtAxleWhlToqV_1_Invalid";
VAL_ 140 TotActuWhlToqV 0 "TotActuWhlToqV_0_Valid" 1 "TotActuWhlToqV_1_Invalid";
VAL_ 140 RrAxleActuWhlToqV 0 "RrAxleActuWhlToqV_0_Valid" 1 "RrAxleActuWhlToqV_1_Invalid";
VAL_ 140 PtHVCntarReq 0 "PtHVCntarReq_0_Undetermined" 1 "PtHVCntarReq_1_CloseAllowed" 2 "PtHVCntarReq_2_RequestOpen";
VAL_ 359 HybAPAAvlbl 0 "HybAPAAvlbl_0_Unavailable" 1 "HybAPAAvlbl_1_Available";
VAL_ 359 MinAvlblTotWhlToqV 0 "MinAvlblTotWhlToqV_0_Valid" 1 "MinAvlblTotWhlToqV_1_Invalid";
VAL_ 359 MaxAvlblTotWhlToqV 0 "MaxAvlblTotWhlToqV_0_Valid" 1 "MaxAvlblTotWhlToqV_1_Invalid";
VAL_ 359 CstRgtnBrkLgtReq 0 "CstRgtnBrkLgtReq_0_NoRequest" 1 "CstRgtnBrkLgtReq_1_Request";
VAL_ 359 CstRgtnBrkLgtReqV 0 "CstRgtnBrkLgtReqV_0_Valid" 1 "CstRgtnBrkLgtReqV_1_Invalid";
VAL_ 359 RdundtHybCmddEnToqRespTyp 0 "RdundtHybCmddEnToqRespTyp_0_Inactive" 1 "RdundtHybCmddEnToqRespTyp_1_PleasabilityLimited" 2 "RdundtHybCmddEnToqRespTyp_2_MaximumRange" 3 "RdundtHybCmddEnToqRespTyp_3_AutomaticActuatorSelection";
VAL_ 236 EnStCtrlA 0 "EnStCtrlA_0_EnStCtrlA_0_FALSE" 1 "EnStCtrlA_1_EnStCtrlA1_TRUE";
VAL_ 236 EnFuelCutA 0 "EnFuelCutA_0_False" 1 "EnFuelCutA_1_True";
VAL_ 236 HybEnStSpOvrd 0 "HybEnStSpOvrd_0_No_Override" 1 "HybEnStSpOvrd_1_Engine_On" 2 "HybEnStSpOvrd_2_Engine_Off" 3 "HybEnStSpOvrd_3_Engine_On_Cycling_Allowed";
VAL_ 236 HybEnSpdReqF 0 "HybEnSpdReqF_0_False" 1 "HybEnSpdReqF_1_True";
VAL_ 236 EnDclFuelCutOffAld 0 "EnDclFuelCutOffAld_0_False" 1 "EnDclFuelCutOffAld_1_True";
VAL_ 236 RVSEnRunning 0 "RVSEnRunning_0_False" 1 "RVSEnRunning_1_True";
VAL_ 236 EnHybVehStaOvrd 0 "EnHybVehStaOvrd_0_HEV_Off" 1 "EnHybVehStaOvrd_1_HEV_Conventional" 2 "EnHybVehStaOvrd_2_HEV_Charge" 3 "EnHybVehStaOvrd_3_HEV_Boost" 4 "EnHybVehStaOvrd_4_HEV_Regen" 5 "EnHybVehStaOvrd_5_HEV_Autostop" 6 "EnHybVehStaOvrd_6_HEV_EngStart" 7 "EnHybVehStaOvrd_7_HEV_Eidle" 8 "EnHybVehStaOvrd_8_Reserved" 9 "EnHybVehStaOvrd_9_Reserved" 10 "EnHybVehStaOvrd_10_Reserved" 11 "EnHybVehStaOvrd_11_EV_Boost" 12 "EnHybVehStaOvrd_12_EV_Regen";
VAL_ 236 EnSynRdy 0 "EnSynRdy_0_EngineSyncNotRdy" 1 "EnSynRdy_1_EngineSyncRdy";
VAL_ 236 EnSysDsbld 0 "EnSysDsbld_0_False" 1 "EnSysDsbld_1_True";
VAL_ 236 EnComFlrRducdPwrCmdd 0 "EnComFlrRducdPwrCmdd_0_False" 1 "EnComFlrRducdPwrCmdd_1_True";
VAL_ 236 PtACCA 0 "PtACCA_0_False" 1 "PtACCA_1_True";
VAL_ 236 EnDclFuelCutOffReq 0 "EnDclFuelCutOffReq_0_DFCO_Not_Requested" 1 "EnDclFuelCutOffReq_1_DFCO_Requested";
VAL_ 236 EnDclFuelCutOffSta 0 "EnDclFuelCutOffSta_0_Normal_Fueling" 1 "EnDclFuelCutOffSta_1_DFCO_Enabled";
VAL_ 236 EnIdleCtrlA 0 "EnIdleCtrlA_0_False" 1 "EnIdleCtrlA_1_True";
VAL_ 236 EnIdleCtrlSts 0 "EnIdleCtrlSts_0_False" 1 "EnIdleCtrlSts_1_True";
VAL_ 236 EnReqdStTyp 0 "EnReqdStTyp_0_No_Request" 1 "EnReqdStTyp_1_Key_Start_Normal" 2 "EnReqdStTyp_2_Key_Start_Low_Power" 3 "EnReqdStTyp_3_Key_Start_Low_Power_B" 4 "EnReqdStTyp_4_Key_Start_Generic" 5 "EnReqdStTyp_5_Auto_Start_Smooth" 6 "EnReqdStTyp_6_Auto_Start_Normal" 7 "EnReqdStTyp_7_Auto_Start_Aggressive" 8 "EnReqdStTyp_8_Auto_Start_Generic" 9 "EnReqdStTyp_9_Compression_Test" 10 "EnReqdStTyp_10_Gear_Start";
VAL_ 777 FlbStrgFnSts 0 "FlbStrgFnSts_0_Off" 1 "FlbStrgFnSts_1_Standby" 2 "FlbStrgFnSts_2_Active" 3 "FlbStrgFnSts_3_Disable";
VAL_ 777 EleccLckCtrlResp 0 "EleccLckCtrlResp_0_Default" 1 "EleccLckCtrlResp_1_Command_Executed_Successful" 2 "EleccLckCtrlResp_2_Failed";
VAL_ 777 OnbdChrgrSktEleccLckEnable 0 "OnbdChrgrSktEleccLckEnable_0_Default" 1 "OnbdChrgrSktEleccLckEnable_1_Locked" 2 "OnbdChrgrSktEleccLckEnable_2_Unlocked";
VAL_ 777 OnBdChrgrSktPstvSnsrTemV 0 "OnBdChrgrSktPstvSnsrTemV_0_Valid" 1 "OnBdChrgrSktPstvSnsrTemV_1_Invalid";
VAL_ 777 OfbdChrgrNgtvSktTemV 0 "OfbdChrgrNgtvSktTemV_0_Valid" 1 "OfbdChrgrNgtvSktTemV_1_Invalid";
VAL_ 777 FlbStrgFnStsResp 0 "FlbStrgFnStsResp_0_Off" 1 "FlbStrgFnStsResp_1_Standby" 2 "FlbStrgFnStsResp_2_Active" 3 "FlbStrgFnStsResp_3_Disable";
VAL_ 777 IMU_Signal_status 0 "IMUSignalStatus_0_Normal" 1 "IMUSignalStatus_1_Failure" 2 "IMUSignalStatus_2_Resved" 3 "IMUSignalStatus_3_Resved" 4 "IMUSignalStatus_4_Resved" 5 "IMUSignalStatus_5_Resved" 6 "IMUSignalStatus_6_Resved" 7 "IMUSignalStatus_7_Resved";
VAL_ 777 VCUCtrlS2Req 0 "VCUCtrlS2Req_0_Default" 1 "VCUCtrlS2Req_1_Close_Request" 2 "VCUCtrlS2Req_2_Open_Request";
VAL_ 777 OnBdChrgrSktElecLckStaV 0 "OnBdChrgrSktElecLckStaV_0_Valid" 1 "OnBdChrgrSktElecLckStaV_1_Invalid";
VAL_ 777 OnBdChrgrSktElecLckSta 0 "OnBdChrgrSktElecLckSta_0_Unlocked" 1 "OnBdChrgrSktElecLckSta_1_Locked" 2 "OnBdChrgrSktElecLckSta_2_ControlLineFailure" 3 "OnBdChrgrSktElecLckSta_3_FeedbackError";
SIG_GROUP_ 351 IICBAD_20ms_Group05 1 : APACrpSpdReqVal_IPD APARevrDrgReq APAToqReqVal APATotWhlToqReqVal APAVCUReqSts ICBAD_20ms_Group05_CRC ICBAD_20ms_Group05_RC ICBAD_20ms_Group05_Reserved1 ICBAD_20ms_Group05_Reserved10 ICBAD_20ms_Group05_Reserved11 ICBAD_20ms_Group05_Reserved12 ICBAD_20ms_Group05_Reserved13 ICBAD_20ms_Group05_Reserved14 ICBAD_20ms_Group05_Reserved15 ICBAD_20ms_Group05_Reserved2 ICBAD_20ms_Group05_Reserved3 ICBAD_20ms_Group05_Reserved4 ICBAD_20ms_Group05_Reserved5 ICBAD_20ms_Group05_Reserved6 ICBAD_20ms_Group05_Reserved7 ICBAD_20ms_Group05_Reserved8 ICBAD_20ms_Group05_Reserved9;
SIG_GROUP_ 424 IICBAD_20ms_Group12 1 : APASts AutodDrvngSysSts AutodDrvngSysStsV ICBAD_20ms_Group12_CRC ICBAD_20ms_Group12_RC ICBAD_20ms_Group12_Reserved1 ICBAD_20ms_Group12_Reserved2 ICBAD_20ms_Group12_Reserved3 ICBAD_20ms_Group12_Reserved4 ICBAD_20ms_Group12_Reserved5 ICBAD_20ms_Group12_Reserved6;
SIG_GROUP_ 431 IICBAD_20ms_Group15 1 : ACCDclReqSts ACCOtptShaftTotToqReqSts ACCOtptShaftTotToqReqVal AutodDrvngSysStsPT ICBAD_20ms_Group15_CRC ICBAD_20ms_Group15_RC ICBAD_20ms_Group15_Reserved1 ICBAD_20ms_Group15_Reserved2 ICBAD_20ms_Group15_Reserved3 ICBAD_20ms_Group15_Reserved4 ICBAD_20ms_Group15_Reserved5 ICBAD_20ms_Group15_Reserved6 ICBAD_20ms_Group15_Reserved7 ICBAD_20ms_Group15_Reserved8 ICBAD_20ms_Group15_Reserved9;
SIG_GROUP_ 81 IICBAD_ZONE_20ms_Group13 1 : ACCToqReqSts ACCToqReqVal ICBAD_ZONE_20ms_Group13_CRC ICBAD_ZONE_20ms_Group13_RC ICBAD_ZONE_20ms_Group13_Reserved0 ICBAD_ZONE_20ms_Group13_Reserved1 ICBAD_ZONE_20ms_Group13_Reserved2 ICBAD_ZONE_20ms_Group13_Reserved3 ICBAD_ZONE_20ms_Group13_Reserved4 ICBAD_ZONE_20ms_Group13_Reserved5 LKASysFltSts LKASysSts TJAICASysFltSts TJAICASysSts;
SIG_GROUP_ 1023 IICBVC_100ms_Group19 1 : AuxBatUnAssembled EPMCurEstdCapct EPMMaxEstdCapct EPMOprtMd EPTToqCustSetngReq EPTToqCustSetngReqV EnrgSplReq EnrgSplReqRaw EnrgSplReqV ICBVC_100ms_Group19_CRC ICBVC_100ms_Group19_RC ICBVC_100ms_Group19_Reserved21 ICBVC_100ms_Group19_Reserved35 ICBVC_100ms_Group19_Reserved58 LVBMDisChrgMOSCtrl LVBatChrgReqInhbt LVBatChrgReqRaw LVBatEnrgLow LVBatEnrgSufct LVBatSelfWakeupFlg PMDCSta RgnLvReqFICM RgnLvReqFICMV VehEnrgRdyLvl VehEnrgRdyLvlV;
SIG_GROUP_ 486 IIPD_20ms_Group43 1 : ACCAccReqToqVal ACCSysFltSts_SCS FrtCarGoNotfr IPD_20ms_Group43_CRC IPD_20ms_Group43_RC IPD_20ms_Group43_Reserved1 IPD_20ms_Group43_Reserved2 IPD_20ms_Group43_Reserved3 IPD_20ms_Group43_Reserved4 IPD_20ms_Group43_Reserved5;
SIG_GROUP_ 733 IIPD_50ms_Group49 1 : APAEnRunReq IPD_50ms_Group49_CRC IPD_50ms_Group49_RC IPD_50ms_Group49_Reserved1 IPD_50ms_Group49_Reserved2 IPD_50ms_Group49_Reserved3 IPD_50ms_Group49_Reserved4 IPD_50ms_Group49_Reserved5 IPD_50ms_Group49_Reserved6 KeepPwrRsnIPD LADSAFnInd SysPwrMdCtrl;
SIG_GROUP_ 478 IIPD_20ms_Group64 1 : APAEnToqReqSts APAEnToqReqVal APASCSBrkFn APASCSBrkFnMd APASCSDrvrReqSts APASCSParkngPrflReq APASCSParkngTrgtDist APASCSParkngVelMax APASCSReqSts IPD_20ms_Group64_CRC IPD_20ms_Group64_RC IPD_20ms_Group64_Reserved1 IPD_20ms_Group64_Reserved10 IPD_20ms_Group64_Reserved2 IPD_20ms_Group64_Reserved3 IPD_20ms_Group64_Reserved4 IPD_20ms_Group64_Reserved5 IPD_20ms_Group64_Reserved6 IPD_20ms_Group64_Reserved7 IPD_20ms_Group64_Reserved8 IPD_20ms_Group64_Reserved9;
SIG_GROUP_ 176 IIPD_20ms_Group67 1 : ADS_SpdAstSysTrgtSpd ADS_SpdAstSysTrgtSpdV IPD_20ms_Group67_CRC IPD_20ms_Group67_RC IPD_20ms_Group67_Reserved103 IPD_20ms_Group67_Reserved111 IPD_20ms_Group67_Reserved119 IPD_20ms_Group67_Reserved127 IPD_20ms_Group67_Reserved15 IPD_20ms_Group67_Reserved23 IPD_20ms_Group67_Reserved31 IPD_20ms_Group67_Reserved39 IPD_20ms_Group67_Reserved47 IPD_20ms_Group67_Reserved55 IPD_20ms_Group67_Reserved63 IPD_20ms_Group67_Reserved71 IPD_20ms_Group67_Reserved95;
SIG_GROUP_ 153 IPEU_10ms_Group25 1 : PEUMotADampTrqCmdd PEUMotAMdAch PEUMotASpd PEUMotASpdSts PEUMotASpdV PEUMotAToqAch PEUMotAToqAchV PEUMotBDampTrqCmdd PEUMotBMdAch PEUMotBSpd PEUMotBSpdSts PEUMotBSpdV PEUMotBToqAch PEUMotBToqAchV PEU_10ms_Group25_CRC PEU_10ms_Group25_RC PEU_10ms_Group25_Reserved1 PEU_10ms_Group25_Reserved147 PEU_10ms_Group25_Reserved3 ReAxleMaxAvlblWhlDrvTq ReAxleMaxAvlblWhlDrvTqV ReAxleMaxAvlblWhlRgtnTq ReAxleMaxAvlblWhlRgtnTqV;
SIG_GROUP_ 140 IPICU_10ms_Group03 1 : DrvrReqFrtAxleWhlToq DrvrReqFrtAxleWhlToqV DrvrReqRrAxleWhlToq DrvrReqRrAxleWhlToqV FrtAxleActuWhlToq FrtAxleActuWhlToqV PICU_10ms_Group03_CRC PICU_10ms_Group03_RC PICU_10ms_Group03_Reserved1 PICU_10ms_Group03_Reserved2 PICU_10ms_Group03_Reserved3 PICU_10ms_Group03_Reserved4 PICU_10ms_Group03_Reserved5 PICU_10ms_Group03_Reserved6 PICU_10ms_Group03_Reserved7 PICU_10ms_Group03_Reserved8 PICU_10ms_Group03_Reserved9 PtHVCntarReq RrAxleActuWhlToq RrAxleActuWhlToqV TotActuWhlToq TotActuWhlToqV;
SIG_GROUP_ 359 IPICU_20ms_Group11 1 : CstRgtnBrkLgtReq CstRgtnBrkLgtReqV HybAPAAvlbl MaxAvlblTotWhlToq MaxAvlblTotWhlToqV MinAvlblTotWhlToq MinAvlblTotWhlToqV PICU_20ms_Group11_CRC PICU_20ms_Group11_RC PICU_20ms_Group11_Reserved1 PICU_20ms_Group11_Reserved2 PICU_20ms_Group11_Reserved3 PICU_20ms_Group11_Reserved4 PICU_20ms_Group11_Reserved5 PICU_20ms_Group11_Reserved6 PICU_20ms_Group11_Reserved7 PICU_20ms_Group11_Reserved8 PICU_20ms_Group11_Reserved9 RdundtHybCmddEnToqImmd RdundtHybCmddEnToqPrdtd RdundtHybCmddEnToqRespTyp;
SIG_GROUP_ 236 IPICU_10ms_Group23 1 : CrkshftNonTrRegdCmddToq EnComFlrRducdPwrCmdd EnDclFuelCutOffAld EnDclFuelCutOffReq EnDclFuelCutOffSta EnFuelCutA EnFuelRcvrySpd EnHybVehStaOvrd EnIdleCtrlA EnIdleCtrlSts EnReqdStTyp EnStCtrlA EnSynRdy EnSysDsbld HybEnSpdReqF HybEnStSpOvrd PICU_10ms_Group23_CRC PICU_10ms_Group23_RC PICU_10ms_Group23_Reserved18 PtACCA RVSEnRunning;
SIG_GROUP_ 777 IRZCU_100ms_Group10 1 : EleccLckCtrlResp FlbStrgFnSts FlbStrgFnStsResp IMU_Signal_status OfbdChrgrNgtvSktTem OfbdChrgrNgtvSktTemV OnBdChrgrSktElecLckSta OnBdChrgrSktElecLckStaV OnBdChrgrSktPstvSnsrTem OnBdChrgrSktPstvSnsrTemV OnbdChrgrSktEleccLckEnable RZCU_100ms_Group10_CRC RZCU_100ms_Group10_RC RZCU_100ms_Group10_Reserved1 RZCU_100ms_Group10_Reserved2 RZCU_100ms_Group10_Reserved3 RZCU_100ms_Group10_Reserved4 RZCU_100ms_Group10_Reserved5 VCUCtrlS2Req;
